VERSION "created by canmatrix"

NS_ :

BS_:

BU_: HUT T_BOX GW XBOX_D CEM Tester

BO_ 849 ABM1: 16 GW
 SG_ CheckSum_ABM1 : 7|8@0+ (1,0) [0|255] "" HUT
 SG_ SecRowLSBR : 14|1@0+ (1,0) [0|1] "" HUT
 SG_ AirbFailLmpCmd : 13|1@0+ (1,0) [0|1] "" HUT
 SG_ SecRowMidSBR : 12|1@0+ (1,0) [0|1] "" HUT
 SG_ DrvSBR : 11|1@0+ (1,0) [0|1] "" HUT
 SG_ SecRowRSBR : 10|1@0+ (1,0) [0|1] "" HUT
 SG_ PassSBR : 9|1@0+ (1,0) [0|1] "" HUT
 SG_ PassSBR_Visual : 27|2@0+ (1,0) [0|3] "" HUT
 SG_ DrvSBR_Visual : 25|2@0+ (1,0) [0|3] "" HUT
 SG_ SecRowLSBR_Visual : 29|2@0+ (1,0) [0|3] "" HUT
 SG_ SecRowMidSBR_Visual : 31|2@0+ (1,0) [0|3] "" HUT
 SG_ SecRowRSBR_Visual : 33|2@0+ (1,0) [0|3] "" HUT
 SG_ CrashOutputSts : 23|8@0+ (1,0) [0|18] "" HUT,T_BOX
 SG_ RollingCounter_ABM1 : 59|4@0+ (1,0) [0|15] "" HUT
 SG_ FreshnessValue_ABM1 : 71|16@0+ (1,0) [0|65535] "" HUT
 SG_ MAC_Check_ABM1 : 87|48@0+ (1,0) [0|281474976710655] "" HUT

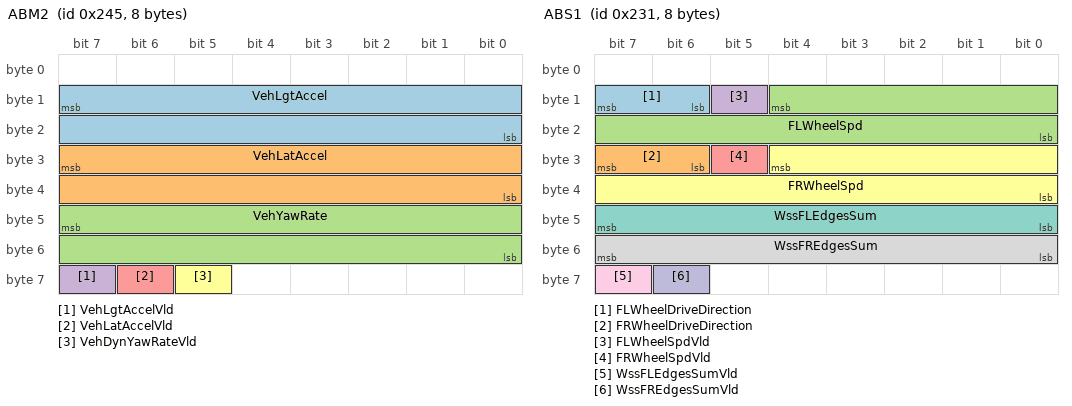
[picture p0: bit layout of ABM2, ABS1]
BO_ 581 ABM2: 8 GW
 SG_ VehLgtAccel : 15|16@0+ (0.00098,-21.592) [-21.592|21.592] "ms^2" HUT,T_BOX
 SG_ VehLatAccel : 31|16@0+ (0.00098,-21.592) [-21.592|21.592] "ms^2" HUT,T_BOX
 SG_ VehYawRate : 47|16@0+ (0.00024,-2.093) [-2.093|2.093] "rads" HUT,T_BOX
 SG_ VehLgtAccelVld : 63|1@0+ (1,0) [0|1] "" HUT,T_BOX
 SG_ VehLatAccelVld : 62|1@0+ (1,0) [0|1] "" HUT,T_BOX
 SG_ VehDynYawRateVld : 61|1@0+ (1,0) [0|1] "" HUT,T_BOX

BO_ 561 ABS1: 8 GW
 SG_ FLWheelDriveDirection : 15|2@0+ (1,0) [0|3] "" HUT
 SG_ FRWheelDriveDirection : 31|2@0+ (1,0) [0|3] "" HUT
 SG_ FLWheelSpd : 12|13@0+ (1,0) [0|299.98125] "kmh" HUT
 SG_ FLWheelSpdVld : 13|1@0+ (1,0) [0|1] "" HUT
 SG_ FRWheelSpdVld : 29|1@0+ (1,0) [0|1] "" HUT
 SG_ FRWheelSpd : 28|13@0+ (1,0) [0|299.98125] "kmh" HUT
 SG_ WssFLEdgesSum : 47|8@0+ (1,0) [0|255] "" HUT
 SG_ WssFREdgesSum : 55|8@0+ (1,0) [0|255] "" HUT
 SG_ WssFLEdgesSumVld : 63|1@0+ (1,0) [0|1] "" HUT
 SG_ WssFREdgesSumVld : 62|1@0+ (1,0) [0|1] "" HUT

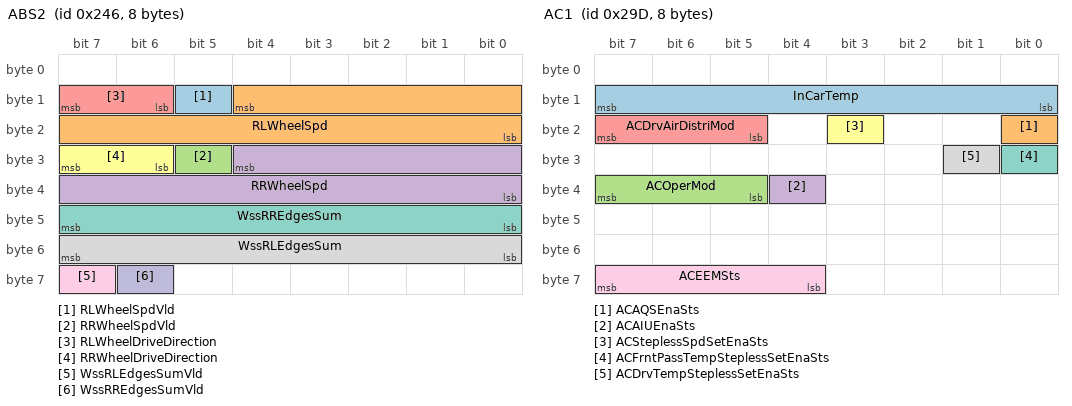
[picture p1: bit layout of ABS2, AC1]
BO_ 582 ABS2: 8 GW
 SG_ RLWheelSpdVld : 13|1@0+ (1,0) [0|1] "" HUT,T_BOX
 SG_ RLWheelSpd : 12|13@0+ (0.05625,0) [0|299.98125] "kmh" HUT,T_BOX
 SG_ RRWheelSpdVld : 29|1@0+ (1,0) [0|1] "" HUT,T_BOX
 SG_ RRWheelSpd : 28|13@0+ (0.05625,0) [0|299.98125] "kmh" HUT,T_BOX
 SG_ RLWheelDriveDirection : 15|2@0+ (1,0) [0|3] "" HUT
 SG_ RRWheelDriveDirection : 31|2@0+ (1,0) [0|3] "" HUT
 SG_ WssRREdgesSum : 47|8@0+ (1,0) [0|255] "" HUT
 SG_ WssRLEdgesSum : 55|8@0+ (1,0) [0|255] "" HUT
 SG_ WssRLEdgesSumVld : 63|1@0+ (1,0) [0|1] "" HUT
 SG_ WssRREdgesSumVld : 62|1@0+ (1,0) [0|1] "" HUT

BO_ 669 AC1: 8 GW
 SG_ InCarTemp : 15|8@0+ (0.5,-40) [-40|86.5] "Ã‚Â°C" HUT,T_BOX
 SG_ ACAQSEnaSts : 16|1@0+ (1,0) [0|1] "" HUT
 SG_ ACOperMod : 39|3@0+ (1,0) [0|7] "" HUT
 SG_ ACAIUEnaSts : 36|1@0+ (1,0) [0|1] "" HUT,T_BOX
 SG_ ACDrvAirDistriMod : 23|3@0+ (1,0) [0|7] "" HUT
 SG_ ACSteplessSpdSetEnaSts : 19|1@0+ (1,0) [0|1] "" HUT
 SG_ ACFrntPassTempSteplessSetEnaSts : 24|1@0+ (1,0) [0|1] "" HUT
 SG_ ACDrvTempSteplessSetEnaSts : 25|1@0+ (1,0) [0|1] "" HUT
 SG_ ACEEMSts : 63|4@0+ (1,0) [0|15] "" HUT

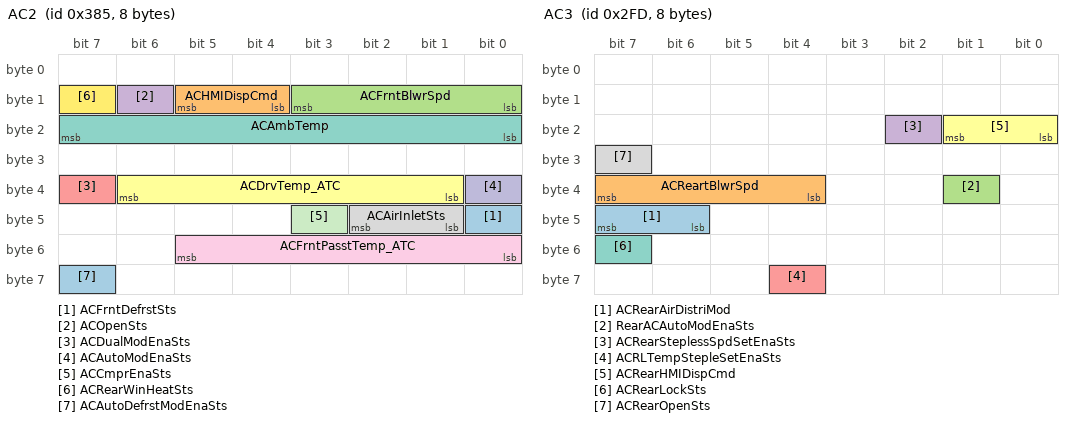
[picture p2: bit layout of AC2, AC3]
BO_ 901 AC2: 8 GW
 SG_ ACFrntDefrstSts : 40|1@0+ (1,0) [0|1] "" HUT,T_BOX
 SG_ ACHMIDispCmd : 13|2@0+ (1,0) [0|3] "" HUT,T_BOX
 SG_ ACFrntBlwrSpd : 11|4@0+ (1,0) [0|15] "" HUT,T_BOX
 SG_ ACOpenSts : 14|1@0+ (1,0) [0|1] "" HUT,T_BOX
 SG_ ACDualModEnaSts : 39|1@0+ (1,0) [0|1] "" HUT
 SG_ ACDrvTemp_ATC : 38|6@0+ (0.5,16) [16|32] "Ã‚Â°C" HUT,T_BOX
 SG_ ACAmbTemp : 23|8@0+ (0.5,-40) [-40|86.5] "Ã‚Â°C" HUT
 SG_ ACAirInletSts : 42|2@0+ (1,0) [0|3] "" HUT
 SG_ ACFrntPasstTemp_ATC : 53|6@0+ (0.5,16) [16|32] "Ã‚Â°C" HUT,T_BOX
 SG_ ACAutoModEnaSts : 32|1@0+ (1,0) [0|1] "" HUT,T_BOX
 SG_ ACCmprEnaSts : 43|1@0+ (1,0) [0|1] "" HUT
 SG_ ACRearWinHeatSts : 15|1@0+ (1,0) [0|1] "" HUT
 SG_ ACAutoDefrstModEnaSts : 63|1@0+ (1,0) [0|1] "" HUT

BO_ 765 AC3: 8 GW
 SG_ ACRearAirDistriMod : 47|2@0+ (1,0) [0|3] "" HUT
 SG_ ACReartBlwrSpd : 39|4@0+ (1,0) [0|15] "" HUT
 SG_ RearACAutoModEnaSts : 33|1@0+ (1,0) [0|1] "" HUT
 SG_ ACRearSteplessSpdSetEnaSts : 18|1@0+ (1,0) [0|1] "" HUT
 SG_ ACRLTempStepleSetEnaSts : 60|1@0+ (1,0) [0|1] "" HUT
 SG_ ACRearHMIDispCmd : 17|2@0+ (1,0) [0|3] "" HUT
 SG_ ACRearLockSts : 55|1@0+ (1,0) [0|1] "" HUT
 SG_ ACRearOpenSts : 31|1@0+ (1,0) [0|1] "" HUT

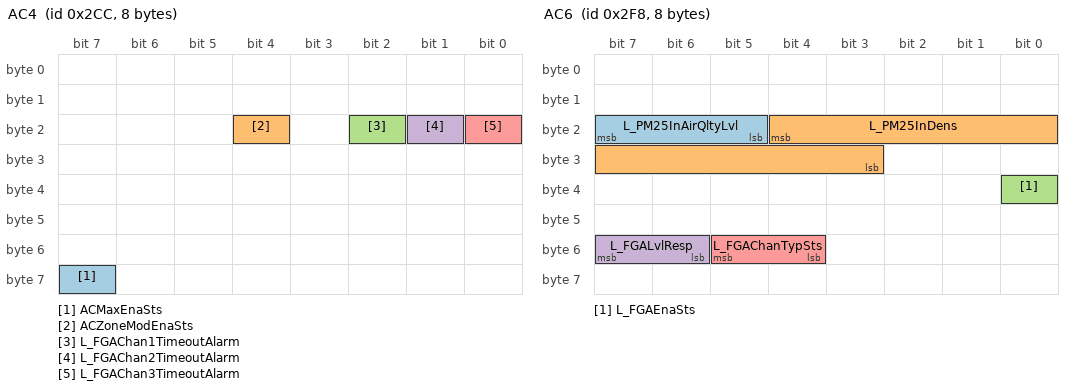
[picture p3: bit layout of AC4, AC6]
BO_ 716 AC4: 8 GW
 SG_ ACMaxEnaSts : 63|1@0+ (1,0) [0|1] "" HUT
 SG_ ACZoneModEnaSts : 20|1@0+ (1,0) [0|1] "" HUT
 SG_ L_FGAChan1TimeoutAlarm : 18|1@0+ (1,0) [0|1] "" HUT
 SG_ L_FGAChan2TimeoutAlarm : 17|1@0+ (1,0) [0|1] "" HUT
 SG_ L_FGAChan3TimeoutAlarm : 16|1@0+ (1,0) [0|1] "" HUT

BO_ 760 AC6: 8 GW
 SG_ L_PM25InAirQltyLvl : 23|3@0+ (1,0) [0|7] "" HUT
 SG_ L_PM25InDens : 20|10@0+ (1,0) [0|999] "ugm^3" HUT
 SG_ L_FGAEnaSts : 32|1@0+ (1,0) [0|1] "" HUT
 SG_ L_FGALvlResp : 55|2@0+ (1,0) [0|3] "" HUT
 SG_ L_FGAChanTypSts : 53|2@0+ (1,0) [0|3] "" HUT

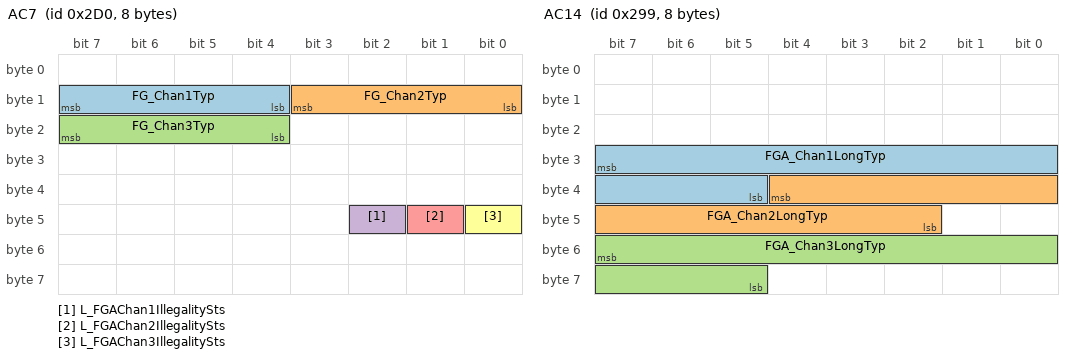
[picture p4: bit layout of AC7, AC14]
BO_ 720 AC7: 8 GW
 SG_ FG_Chan1Typ : 15|4@0+ (1,0) [0|15] "" HUT
 SG_ FG_Chan2Typ : 11|4@0+ (1,0) [0|15] "" HUT
 SG_ FG_Chan3Typ : 23|4@0+ (1,0) [0|15] "" HUT
 SG_ L_FGAChan1IllegalitySts : 42|1@0+ (1,0) [0|1] "" HUT
 SG_ L_FGAChan2IllegalitySts : 41|1@0+ (1,0) [0|1] "" HUT
 SG_ L_FGAChan3IllegalitySts : 40|1@0+ (1,0) [0|1] "" HUT

BO_ 636 AC8: 8 GW
 SG_ RearInCarTemp : 47|8@0+ (0.5,-40) [-40|86.5] "Ã‚Â°C" HUT,T_BOX
 SG_ ACRLTemp_ATC : 31|6@0+ (0.5,16) [16|32] "Ã‚Â°C" HUT,T_BOX

BO_ 665 AC14: 8 GW
 SG_ FGA_Chan1LongTyp : 31|11@0+ (1,0) [0|2047] "" HUT
 SG_ FGA_Chan2LongTyp : 36|11@0+ (1,0) [0|2047] "" HUT
 SG_ FGA_Chan3LongTyp : 55|11@0+ (1,0) [0|2047] "" HUT

BO_ 683 ACC_FD2: 64 IFC
 SG_ ACC_LeTgt_02_Dy : 15|7@0+ (0.1,-8) [-8|0] "m" HUT
 SG_ ACC_LeTgt_02_Dx : 8|9@0+ (0.5,0) [0|150] "m" HUT
 SG_ ACC_LeTgt_02_Typ : 31|3@0+ (1,0) [0|7] "" HUT
 SG_ ACC_LeTargrt_02_Detn : 28|2@0+ (1,0) [0|3] "" HUT
 SG_ ACC_RiTargrt_02_Detn : 26|2@0+ (1,0) [0|3] "" HUT
 SG_ ACC_RiTgt_02_Dy : 55|7@0+ (0.1,0) [0|8] "m" HUT
 SG_ ACC_RiTgt_02_Dx : 24|9@0+ (0.5,0) [0|150] "m" HUT
 SG_ ACC_RiTgt_02_Typ : 63|3@0+ (1,0) [0|7] "" HUT
 SG_ ACC_LeTgtObjBarDisp : 47|3@0+ (1,0) [0|7] "" HUT
 SG_ ACC_RiTgtObjBarDisp : 44|3@0+ (1,0) [0|7] "" HUT
 SG_ Checksum_ACC3 : 71|8@0+ (1,0) [0|255] "" HUT
 SG_ ICA_HandsOffResp : 78|1@0+ (1,0) [0|1] "" HUT
 SG_ ALC_Resp : 73|1@0+ (1,0) [0|1] "" HUT
 SG_ HWA_Resp : 77|1@0+ (1,0) [0|1] "" HUT
 SG_ ISL_Resp : 79|1@0+ (1,0) [0|1] "" HUT
 SG_ HWA_SnvtySet_Resp : 76|2@0+ (1,0) [0|3] "" HUT
 SG_ Longctrl_VehHldReq_DVR : 87|1@0+ (1,0) [0|1] "" HUT
 SG_ Longctrl_DrvOFF_Req_DVR : 86|1@0+ (1,0) [0|1] "" HUT
 SG_ Longctrl_ModSts_DVR : 85|4@0+ (1,0) [0|15] "" HUT
 SG_ Longctrl_Decel_Req_DVR : 81|1@0+ (1,0) [0|1] "" HUT
 SG_ Longctrl_EngTrqReq_DVR : 95|16@0+ (0.0030518,-100) [-100|99.999713] "%" HUT
 SG_ Longctrl_EngTrqReqActive_DVR : 80|1@0+ (1,0) [0|1] "" HUT
 SG_ Longctrl_DecelToStopReq_DVR : 119|1@0+ (1,0) [0|1] "" HUT
 SG_ Longctrl_ParkShiftReq_DVR : 118|2@0+ (1,0) [0|3] "" HUT
 SG_ Longctrl_Decel_ReqValue_DVR : 111|8@0+ (0.05,-7) [-7|5.75] "ms^2" HUT
 SG_ ALC_InterSysInfoDisp : 127|2@0+ (1,0) [0|3] "" HUT
 SG_ RollingCounter_ACC3 : 123|4@0+ (1,0) [0|15] "" HUT
 SG_ Checksum_ACC4 : 135|8@0+ (1,0) [0|255] "" HUT
 SG_ ACC_ObjDetecte : 143|1@0+ (1,0) [0|1] "" HUT
 SG_ ACC_TakeOverReq : 142|1@0+ (1,0) [0|1] "" HUT
 SG_ ACC_InterSysInfoDisp : 141|5@0+ (1,0) [0|31] "" HUT
 SG_ ACC_ModDisp : 151|5@0+ (1,0) [0|31] "" HUT
 SG_ ACC_FctSts : 146|2@0+ (1,0) [0|3] "" HUT
 SG_ ACC_TgtObjBarDisp : 159|3@0+ (1,0) [0|7] "" HUT
 SG_ Longctrl_HazActv : 156|2@0+ (1,0) [0|3] "" HUT
 SG_ TJA_ACC_SelSts : 154|3@0+ (1,0) [0|7] "" HUT
 SG_ CruCha_ModDisp : 167|4@0+ (1,0) [0|15] "" HUT
 SG_ TJA_ICA_InterSysInfoDisp : 163|3@0+ (1,0) [0|7] "" HUT
 SG_ TJA_ICA_ModDisp : 175|3@0+ (1,0) [0|7] "" HUT
 SG_ ISL_InterSysInfoDisp : 172|2@0+ (1,0) [0|3] "" HUT
 SG_ ACC_TimeGapSet : 170|3@0+ (1,0) [0|7] "" HUT
 SG_ ACC_SpdSetValue : 183|8@0+ (1,0) [0|255] "kphmph" HUT
 SG_ CruChar_InterSysInfoDisp : 191|4@0+ (1,0) [0|15] "" HUT
 SG_ RollingCounter_ACC4 : 187|4@0+ (1,0) [0|15] "" HUT
 SG_ Checksum_ACC8 : 199|8@0+ (1,0) [0|255] "" HUT
 SG_ HWA_ModDisp : 207|4@0+ (1,0) [0|15] "" HUT
 SG_ HWA_InterSysInfoDisp : 203|4@0+ (1,0) [0|15] "" HUT
 SG_ HWA_LaneChange : 213|2@0+ (1,0) [0|3] "" HUT
 SG_ HWA_LaneChangeReq : 223|3@0+ (1,0) [0|7] "" HUT
 SG_ HWA_Warning : 217|2@0+ (1,0) [0|3] "" HUT
 SG_ RollingCounter_ACC8 : 251|4@0+ (1,0) [0|15] "" HUT
 SG_ Checksum_ACC6 : 263|8@0+ (1,0) [0|255] "" HUT
 SG_ ACC_PotentialTgtDy : 271|8@0+ (0.1,-8) [-8|8] "m" HUT
 SG_ ACC_PotentialTgtDx : 279|9@0+ (0.5,0) [0|150] "m" HUT
 SG_ ACC_RlvTgtDetn : 286|2@0+ (1,0) [0|3] "" HUT
 SG_ ACC_EgoStatus : 284|2@0+ (1,0) [0|3] "" HUT
 SG_ ACC_RlvTgtTyp : 282|3@0+ (1,0) [0|7] "" HUT
 SG_ ACC_RlvTgtDy : 295|8@0+ (0.1,-8) [-8|8] "m" HUT
 SG_ ACC_RlvTgtDx : 303|9@0+ (0.5,0) [0|150] "m" HUT
 SG_ ACC_PotentialTgtDetn : 309|2@0+ (1,0) [0|3] "" HUT
 SG_ ACC_PotentialTgtTyp : 307|3@0+ (1,0) [0|7] "" HUT
 SG_ RollingCounter_ACC6 : 315|4@0+ (1,0) [0|15] "" HUT
 SG_ Checksum_ACC7 : 327|8@0+ (1,0) [0|255] "" HUT
 SG_ Request_driveoff : 383|3@0+ (1,0) [0|7] "" HUT
 SG_ ACCSts : 380|1@0+ (1,0) [0|1] "" HUT
 SG_ ACC_LeTgtDy : 335|8@0+ (0.1,-8) [-8|8] "m" HUT
 SG_ ACC_LeTgtDx : 343|9@0+ (0.5,0) [0|150] "m" HUT
 SG_ ACC_LeTgtTyp : 350|3@0+ (1,0) [0|7] "" HUT
 SG_ ACC_LeTargrtDection : 347|2@0+ (1,0) [0|3] "" HUT
 SG_ ACC_RiTargrtDetn : 345|2@0+ (1,0) [0|3] "" HUT
 SG_ ACC_RiTgtDy : 359|8@0+ (0.1,-8) [-8|8] "m" HUT
 SG_ ACC_RiTgtDx : 367|9@0+ (0.5,0) [0|150] "m" HUT
 SG_ ACC_RiTgtTyp : 374|3@0+ (1,0) [0|7] "" HUT
 SG_ RollingCounter_ACC7 : 379|4@0+ (1,0) [0|15] "" HUT
 SG_ FreshnessValue_ACC_FD2 : 455|16@0+ (1,0) [0|65535] "" HUT
 SG_ MAC_Check_ACC_FD2 : 471|48@0+ (1,0) [0|281474976710655] "" HUT
 SG_ ACC_RlvTgtfusion : 399|1@0+ (1,0) [0|1] "" HUT
 SG_ ACC_RlvTgtHeading : 398|6@0+ (0.05,-1.5) [-1.5|1.5] "rad" HUT
 SG_ ACC_LeTgtfusion : 392|1@0+ (1,0) [0|1] "" HUT
 SG_ ACC_LeTgtHeading : 407|6@0+ (0.05,-1.5) [-1.5|1.5] "rad" HUT
 SG_ ACC_RiTgtfusion : 401|1@0+ (1,0) [0|1] "" HUT
 SG_ ACC_RiTgtHeading : 415|6@0+ (0.05,-1.5) [-1.5|1.5] "rad" HUT
 SG_ ACC_PotentialTgtfusion : 400|1@0+ (1,0) [0|1] "" HUT
 SG_ ACC_PotentialTgtHeading : 409|6@0+ (0.05,-1.5) [-1.5|1.5] "rad" HUT
 SG_ TargetCutinPro : 419|6@0+ (0.02,0) [0|1] "" HUT
 SG_ TargetCutoutPro : 429|6@0+ (0.02,0) [0|1] "" HUT
 SG_ Longctrl_WheelTrqReqActive_DVR : 116|1@0+ (1,0) [0|1] "" HUT
 SG_ Longctrl_WheelTrqReq_DVR : 231|16@0+ (0.5,-16384) [-16384|16383.5] "NM" HUT

BO_ 692 ACC_FD3: 64 GW
 SG_ JAPedObjExist : 47|6@0+ (0.015625,0) [0|0.984375] "%" HUT
 SG_ AEBJAObjID : 79|8@0+ (1,0) [0|255] "" HUT
 SG_ AEBJAObjExist : 87|6@0+ (0.015625,0) [0|0.984375] "%" HUT
 SG_ JAPedObjID : 119|8@0+ (1,0) [0|255] "" HUT
 SG_ AEBJAObjVideoCfmd : 81|1@0+ (1,0) [0|1] "" HUT
 SG_ AEBJAObjVx : 95|12@0+ (0.0625,-128) [-128|127] "ms" HUT
 SG_ AEBJAObjDx : 99|12@0+ (0.0625,0) [0|255.9375] "m" HUT
 SG_ JAPedObjVideoCfmd : 80|1@0+ (1,0) [0|1] "" HUT
 SG_ AEBJAObjState : 127|3@0+ (1,0) [0|7] "" HUT
 SG_ AEBJAObjCntAlive : 143|12@0+ (17,0) [0|65535] "" HUT
 SG_ AEBJAObjDy : 147|11@0+ (0.125,-128) [-128|127.875] "m" HUT
 SG_ JAPedObjState : 191|3@0+ (1,0) [0|7] "" HUT
 SG_ AEBJAObjObstcl : 152|5@0+ (0.03125,0) [0|0.96875] "%" HUT
 SG_ AEBJAObjVy : 163|10@0+ (0.125,-64) [-64|63.875] "ms" HUT
 SG_ AEBJAObjAx : 169|10@0+ (0.03125,-16) [-16|15.96875] "ms2" HUT
 SG_ AEBJAObjAy : 207|10@0+ (0.03125,-16) [-16|15.96875] "ms2" HUT
 SG_ JAPedObjObstcl : 213|5@0+ (0.03125,0) [0|0.96875] "%" HUT
 SG_ JAPedObjDy : 223|11@0+ (0.125,-128) [-128|127.875] "m" HUT
 SG_ JAPedObjDx : 228|12@0+ (0.0625,0) [0|255.9375] "m" HUT
 SG_ FCWAEB_JATTC : 247|6@0+ (0.1,0) [0|6.3] "s" HUT
 SG_ JAPedObjVx : 271|12@0+ (0.0625,-128) [-128|127] "ms" HUT
 SG_ JAPedObjVy : 295|10@0+ (0.125,-64) [-64|63.875] "ms" HUT
 SG_ JAPedObjAy : 301|10@0+ (0.03125,-16) [-16|15.96875] "ms2" HUT
 SG_ JAPedObjCntAlive : 275|12@0+ (17,0) [0|65535] "" HUT
 SG_ FCWAEB_longTTC : 365|6@0+ (0.1,0) [0|6.3] "s" HUT
 SG_ FCWAEB_crossingTTC : 375|6@0+ (0.1,0) [0|6.3] "s" HUT
 SG_ JAPedObjAx : 335|10@0+ (0.03125,-16) [-16|15.96875] "ms2" HUT
 SG_ NOH_Sts : 355|4@0+ (1,0) [0|15] "" HUT
 SG_ NOH_Swt_Resp : 368|1@0+ (1,0) [0|1] "" HUT
 SG_ NOH_Act_Resp : 369|1@0+ (1,0) [0|1] "" HUT
 SG_ NOH_SysInfoDisplay : 383|4@0+ (1,0) [0|15] "" HUT
 SG_ NOH_DistToExit : 351|12@0+ (1,0) [0|4095] "m" HUT

BO_ 696 ACC_FD4: 64 GW
 SG_ AEBObjID : 7|8@0+ (1,0) [0|255] "" HUT
 SG_ AEBObjExist : 15|6@0+ (0.015625,0) [0|0.984375] "%" HUT
 SG_ AEBObjVideoCfmd : 9|1@0+ (1,0) [0|1] "" HUT
 SG_ AEBObjVx : 23|12@0+ (0.0625,-128) [-128|127] "ms" HUT
 SG_ AEBObjDx : 27|12@0+ (0.0625,0) [0|255.9375] "m" HUT
 SG_ AEBObjCntAlive : 47|12@0+ (1,0) [0|3855] "" HUT
 SG_ AEBObjDy : 50|11@0+ (0.125,-128) [-128|127.875] "m" HUT
 SG_ AEBObjState : 71|3@0+ (1,0) [0|7] "" HUT
 SG_ AEBObjObstcl : 68|5@0+ (0.03125,0) [0|0.96875] "%" HUT
 SG_ AEBObjVy : 79|10@0+ (0.125,-64) [-64|63.875] "ms" HUT
 SG_ CyclistObjExist : 85|6@0+ (0.015625,0) [0|0.984375] "%" HUT
 SG_ AEBObjAx : 95|10@0+ (0.03125,-16) [-16|15.96875] "ms2" HUT
 SG_ AEBObjAy : 101|10@0+ (0.03125,-16) [-16|15.96875] "ms2" HUT
 SG_ CyclistObjDx : 107|12@0+ (0.0625,0) [0|255.9375] "m" HUT
 SG_ CyclistObjID : 127|8@0+ (1,0) [0|255] "" HUT
 SG_ CyclistObjObstcl : 135|5@0+ (0.03125,0) [0|0.96875] "%" HUT
 SG_ CyclistObjDy : 130|11@0+ (0.125,-128) [-128|127.875] "m" HUT
 SG_ CyclistObjVx : 151|12@0+ (0.0625,-128) [-128|127] "ms" HUT
 SG_ CyclistObjCntAlive : 155|12@0+ (1,0) [0|3855] "" HUT
 SG_ CyclistObjVy : 175|10@0+ (0.125,-64) [-64|63.875] "ms" HUT
 SG_ CyclistObjState : 181|3@0+ (1,0) [0|7] "" HUT
 SG_ CyclistObjVideoCfmd : 178|1@0+ (1,0) [0|1] "" HUT
 SG_ CyclistObjAx : 177|10@0+ (0.03125,-16) [-16|15.96875] "ms2" HUT
 SG_ CyclistObjAy : 199|10@0+ (0.03125,-16) [-16|15.96875] "ms2" HUT
 SG_ PedObjExist : 205|6@0+ (0.015625,0) [0|0.984375] "%" HUT
 SG_ PedObjID : 215|8@0+ (1,0) [0|255] "" HUT
 SG_ PedObjObstcl : 223|5@0+ (0.03125,0) [0|0.96875] "%" HUT
 SG_ PedObjDy : 218|11@0+ (0.125,-128) [-128|127.875] "m" HUT
 SG_ PedObjDx : 239|12@0+ (0.0625,0) [0|255.9375] "m" HUT
 SG_ PedObjVx : 243|12@0+ (0.0625,-128) [-128|127] "ms" HUT
 SG_ PedObjVy : 263|10@0+ (0.125,-64) [-64|63.875] "ms" HUT
 SG_ PedObjVideoCfmd : 269|1@0+ (1,0) [0|1] "" HUT
 SG_ ACCTgtObjDx : 267|12@0+ (0.0625,0) [0|255.9375] "m" HUT
 SG_ PedObjAy : 287|10@0+ (0.03125,-16) [-16|15.96875] "ms2" HUT
 SG_ PedObjCntAlive : 293|12@0+ (1,0) [0|3855] "" HUT
 SG_ PedObjAx : 297|10@0+ (0.03125,-16) [-16|15.96875] "ms2" HUT
 SG_ ACCTgtObjID : 319|8@0+ (1,0) [0|255] "" HUT
 SG_ ACCTgtObjObstcl : 327|5@0+ (0.03125,0) [0|0.96875] "%" HUT
 SG_ ACCTgtObjDy : 322|11@0+ (0.125,-128) [-128|127.875] "m" HUT
 SG_ ACCTgtObjExist : 343|6@0+ (0.015625,0) [0|0.984375] "%" HUT
 SG_ ACCTgtObjVy : 337|10@0+ (0.125,-64) [-64|63.875] "ms" HUT
 SG_ ACCTgtObjVx : 359|12@0+ (0.0625,-128) [-128|127] "ms" HUT
 SG_ ACCTgtObjAx : 363|10@0+ (0.03125,-16) [-16|15.96875] "ms2" HUT
 SG_ ACCTgtObjAy : 369|10@0+ (0.03125,-16) [-16|15.96875] "ms2" HUT
 SG_ ACCTgtObjState : 391|3@0+ (1,0) [0|7] "" HUT
 SG_ ACCTgtObjVideoCfmd : 388|1@0+ (1,0) [0|1] "" HUT
 SG_ ACCTgtObjCntAlive : 387|12@0+ (1,0) [0|3855] "" HUT
 SG_ RadarHorMisalign : 407|12@0+ (0.0001,-0.2048) [-0.2048|0.2047] "rad" HUT
 SG_ HandsoffDetd : 411|2@0+ (1,0) [0|3] "" HUT
 SG_ DrvgOnHiWay : 409|2@0+ (1,0) [0|3] "" HUT
 SG_ RoadCrvt : 423|10@0+ (0.00032,-0.16352) [-0.16352|0.16352] "" HUT
 SG_ SpdLimitDst : 429|6@0+ (10,0) [0|600] "m" HUT
 SG_ RoadCrvtFar : 439|10@0+ (0.00032,-0.16352) [-0.16352|0.16352] "" HUT
 SG_ RampDst : 445|6@0+ (10,0) [0|600] "m" HUT
 SG_ SpdLimit : 455|8@0+ (1,0) [0|255] "" HUT
 SG_ CurveDst : 463|6@0+ (10,0) [0|600] "m" HUT
 SG_ NavSpdLimUnit : 457|2@0+ (1,0) [0|3] "" HUT
 SG_ TunnelDst : 471|6@0+ (10,0) [0|600] "m" HUT
 SG_ DrvgOnRiLane : 465|2@0+ (1,0) [0|3] "" HUT
 SG_ BrdgDst : 479|6@0+ (10,0) [0|600] "m" HUT
 SG_ RadarDrvrAttentive : 473|1@0+ (1,0) [0|1] "" HUT
 SG_ ACC_DataRecReq : 511|8@0+ (1,0) [0|255] "" HUT
 SG_ ACC_SOSReq : 484|2@0+ (1,0) [0|3] "" HUT,T_BOX
 SG_ PedObjState : 482|3@0+ (1,0) [0|7] "" HUT
 SG_ MapDataValid : 495|1@0+ (1,0) [0|1] "" HUT
 SG_ DrvrSts : 494|3@0+ (1,0) [0|7] "" HUT
 SG_ AEBObjOverlap : 491|5@0+ (1,0) [0|31] "" HUT
 SG_ AEBObjDrvby : 502|5@0+ (1,0) [0|31] "" HUT

BO_ 395 AEB_FD1: 64 GW
 SG_ AEB_ABA_Level : 79|2@0+ (1,0) [0|3] "" HUT
 SG_ AEB_ABA_Req : 77|1@0+ (1,0) [0|1] "" HUT
 SG_ EBA_TgtDecel_Req : 76|1@0+ (1,0) [0|1] "" HUT
 SG_ AEB_VehHldReq : 75|1@0+ (1,0) [0|1] "" HUT
 SG_ AEB_TgtDecel_Req : 74|1@0+ (1,0) [0|1] "" HUT
 SG_ AEB_TgtDecel_ReqValue : 87|16@0+ (0.000488,-16) [-16|16] "ms2" HUT
 SG_ AEB_AWB_Req : 73|1@0+ (1,0) [0|1] "" HUT
 SG_ AEB_AWB_Level : 103|4@0+ (1,0) [0|15] "" HUT
 SG_ AEB_ABP_Req : 72|1@0+ (1,0) [0|1] "" HUT
 SG_ AEB_BrkReqFunc : 99|3@0+ (1,0) [0|7] "" HUT
 SG_ AEB_ObjSty : 111|3@0+ (1,0) [0|7] "" HUT

BO_ 551 AEB_FD2: 64 IFC
 SG_ Checksum_AEB2 : 71|8@0+ (1,0) [0|255] "" HUT
 SG_ AEB_PedResp : 79|1@0+ (1,0) [0|1] "" HUT
 SG_ AEB_VehResp : 78|1@0+ (1,0) [0|1] "" HUT
 SG_ FCW_Snvty : 77|2@0+ (1,0) [0|3] "" HUT
 SG_ AEB_JA_Resp : 75|1@0+ (1,0) [0|1] "" HUT
 SG_ RollingCounter_AEB2 : 123|4@0+ (1,0) [0|15] "" HUT
 SG_ Checksum_AEB3 : 135|8@0+ (1,0) [0|255] "" HUT
 SG_ AEB_VehTrig : 143|1@0+ (1,0) [0|1] "" HUT
 SG_ AEB_PedTrig : 142|1@0+ (1,0) [0|1] "" HUT
 SG_ FCW_AEB_VehFctSts : 138|2@0+ (1,0) [0|3] "" HUT
 SG_ FCW_AEB_PedFctSts : 151|2@0+ (1,0) [0|3] "" HUT
 SG_ FCW_Warn : 149|2@0+ (1,0) [0|3] "" HUT
 SG_ AEB_JAFuncSts : 147|2@0+ (1,0) [0|3] "" HUT
 SG_ AEB_JA_Warn : 145|2@0+ (1,0) [0|3] "" HUT
 SG_ AEB_JABrkTrig : 159|2@0+ (1,0) [0|3] "" HUT
 SG_ RollingCounter_AEB3 : 187|4@0+ (1,0) [0|15] "" HUT
 SG_ ACC_PotentialTgt_02_Dy : 207|8@0+ (0.1,-8) [-8|8] "m" HUT
 SG_ ACC_PotentialTgt_02_Dx : 215|9@0+ (0.5,0) [0|150] "m" HUT
 SG_ ACC_PotentialTgt_02_Detn : 222|2@0+ (1,0) [0|3] "" HUT
 SG_ ACC_PotentialTgt_02_Typ : 220|3@0+ (1,0) [0|7] "" HUT
 SG_ ACC_PotentialTgt_02_fusion : 217|1@0+ (1,0) [0|1] "" HUT
 SG_ ACC_PotentialTgt_02_Heading : 239|6@0+ (0.05,-1.5) [-1.5|1.5] "rad" HUT
 SG_ ACC_LeTgt_03_Dy : 247|8@0+ (0.1,-8) [-8|8] "m" HUT
 SG_ ACC_LeTgt_03_Dx : 216|9@0+ (0.5,-50) [-50|150] "m" HUT
 SG_ ACC_LeTargrt_03_Detn : 233|2@0+ (1,0) [0|3] "" HUT
 SG_ ACC_LeTgt_03_Typ : 255|3@0+ (1,0) [0|7] "" HUT
 SG_ ACC_LeTgt_03_fusion : 252|1@0+ (1,0) [0|1] "" HUT
 SG_ ACC_LeTgt_03_Heading : 271|6@0+ (0.05,-1.5) [-1.5|1.5] "rad" HUT
 SG_ ACC_RiTgt_03_Dy : 279|8@0+ (0.1,-8) [-8|7] "m" HUT
 SG_ ACC_RiTgt_03_Dx : 287|9@0+ (0.5,-50) [-50|150] "m" HUT
 SG_ ACC_RiTargrt_03_Detn : 265|2@0+ (1,0) [0|3] "" HUT
 SG_ ACC_RiTgt_03_Typ : 294|3@0+ (1,0) [0|7] "" HUT
 SG_ ACC_RiTgt_03_fusion : 291|1@0+ (1,0) [0|1] "" HUT
 SG_ ACC_RiTgt_03_Heading : 303|6@0+ (0.05,-1.5) [-1.5|1.5] "rad" HUT
 SG_ FreshnessValue_AEB_FD2 : 455|16@0+ (1,0) [0|65535] "" HUT
 SG_ MAC_Check_AEB_FD2 : 471|48@0+ (1,0) [0|281474976710655] "" HUT

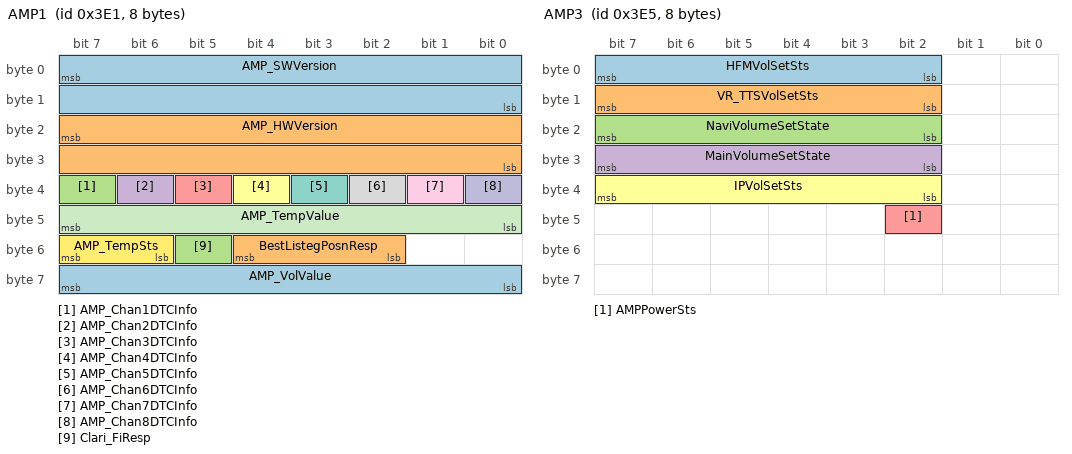
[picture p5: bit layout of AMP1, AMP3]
BO_ 993 AMP1: 8 GW
 SG_ AMP_SWVersion : 7|16@0+ (1,0) [0|65535] "" HUT
 SG_ AMP_HWVersion : 23|16@0+ (1,0) [0|65535] "" HUT
 SG_ AMP_Chan1DTCInfo : 39|1@0+ (1,0) [0|1] "" HUT
 SG_ AMP_Chan2DTCInfo : 38|1@0+ (1,0) [0|1] "" HUT
 SG_ AMP_Chan3DTCInfo : 37|1@0+ (1,0) [0|1] "" HUT
 SG_ AMP_Chan4DTCInfo : 36|1@0+ (1,0) [0|1] "" HUT
 SG_ AMP_Chan5DTCInfo : 35|1@0+ (1,0) [0|1] "" HUT
 SG_ AMP_Chan6DTCInfo : 34|1@0+ (1,0) [0|1] "" HUT
 SG_ AMP_Chan7DTCInfo : 33|1@0+ (1,0) [0|1] "" HUT
 SG_ AMP_Chan8DTCInfo : 32|1@0+ (1,0) [0|1] "" HUT
 SG_ AMP_TempValue : 47|8@0+ (1,-50) [-50|204] "" HUT
 SG_ AMP_TempSts : 55|2@0+ (1,0) [0|3] "" HUT
 SG_ AMP_VolValue : 63|8@0+ (0.1,0) [0|25.5] "" HUT
 SG_ BestListegPosnResp : 52|3@0+ (1,0) [0|7] "" HUT
 SG_ Clari_FiResp : 53|1@0+ (1,0) [0|1] "" HUT

BO_ 995 AMP2: 16 GW
 SG_ MediaCallSourceState : 7|4@0+ (1,0) [0|15] "" HUT
 SG_ BeepSourceSts : 2|3@0+ (1,0) [0|7] "" HUT
 SG_ BalanceSetState : 15|5@0+ (1,0) [0|20] "" HUT
 SG_ VSCModeState : 9|2@0+ (1,0) [0|3] "" HUT
 SG_ FadeSetState : 23|5@0+ (1,0) [0|20] "" HUT
 SG_ DriveSideSts : 17|1@0+ (1,0) [0|1] "" HUT
 SG_ BassSetState : 31|5@0+ (1,0) [0|20] "" HUT
 SG_ MuteState : 25|1@0+ (1,0) [0|1] "" HUT
 SG_ NaviSourceState : 39|3@0+ (1,0) [0|7] "" HUT
 SG_ MidrangeSetState : 47|5@0+ (1,0) [0|20] "" HUT
 SG_ T_box_ECallSts : 42|1@0+ (1,0) [0|1] "" HUT
 SG_ GetHUTInfoSts : 41|1@0+ (1,0) [0|1] "" HUT
 SG_ TrebleSetState : 55|5@0+ (1,0) [0|20] "" HUT
 SG_ QLISurroundSetSt : 49|1@0+ (1,0) [0|1] "" HUT
 SG_ AVMStResp : 3|1@0+ (1,0) [0|1] "" HUT
 SG_ NaviMediaVolLvlResp : 63|4@0+ (1,0) [0|15] "" HUT
 SG_ AVMMediaVolLvlResp : 59|4@0+ (1,0) [0|15] "" HUT
 SG_ FPASChStResp : 10|1@0+ (1,0) [0|1] "" HUT
 SG_ RPASChStResp : 18|1@0+ (1,0) [0|1] "" HUT
 SG_ FreshnessValue_AMP2 : 71|16@0+ (1,0) [0|65535] "" HUT
 SG_ MAC_Check_AMP2 : 87|48@0+ (1,0) [0|281474976710655] "" HUT

BO_ 997 AMP3: 8 GW
 SG_ HFMVolSetSts : 7|6@0+ (1,0) [0|39] "" HUT
 SG_ VR_TTSVolSetSts : 15|6@0+ (1,0) [0|39] "" HUT
 SG_ NaviVolumeSetState : 23|6@0+ (1,0) [0|39] "" HUT
 SG_ MainVolumeSetState : 31|6@0+ (1,0) [0|39] "" HUT
 SG_ AMPPowerSts : 42|1@0+ (1,0) [0|1] "" HUT
 SG_ IPVolSetSts : 39|6@0+ (1,0) [0|39] "" HUT

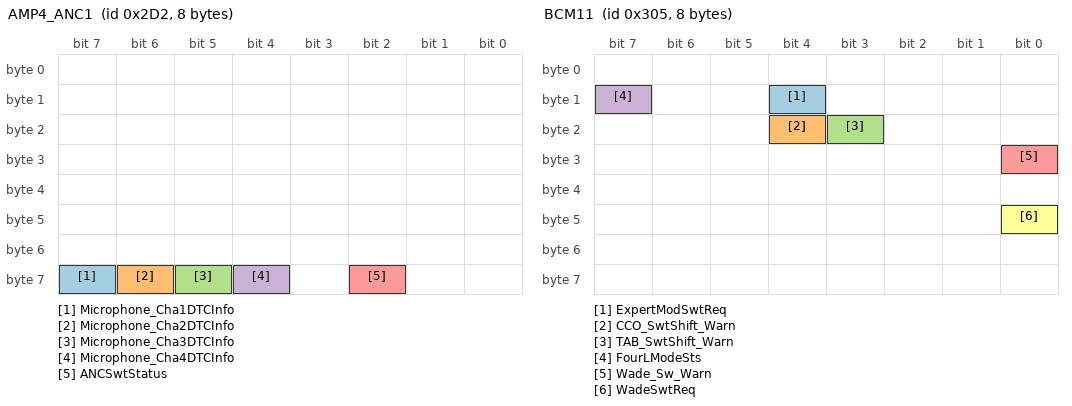
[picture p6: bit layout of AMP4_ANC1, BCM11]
BO_ 722 AMP4_ANC1: 8 GW
 SG_ Microphone_Cha1DTCInfo : 63|1@0+ (1,0) [0|1] "" HUT
 SG_ Microphone_Cha2DTCInfo : 62|1@0+ (1,0) [0|1] "" HUT
 SG_ Microphone_Cha3DTCInfo : 61|1@0+ (1,0) [0|1] "" HUT
 SG_ Microphone_Cha4DTCInfo : 60|1@0+ (1,0) [0|1] "" HUT
 SG_ ANCSwtStatus : 58|1@0+ (1,0) [0|1] "" HUT

BO_ 793 BCM1: 16 GW
 SG_ IPBackgroundLmpCmd : 18|1@0+ (1,0) [0|1] "" HUT
 SG_ TrunkSts : 23|1@0+ (1,0) [0|1] "" HUT,T_BOX
 SG_ DrvDoorSts : 22|1@0+ (1,0) [0|1] "" HUT,XBOX_D,T_BOX
 SG_ LRDoorSts : 21|1@0+ (1,0) [0|1] "" HUT,T_BOX
 SG_ PassengerDoorSts : 20|1@0+ (1,0) [0|1] "" HUT,XBOX_D,T_BOX
 SG_ RRDoorSts : 19|1@0+ (1,0) [0|1] "" HUT,T_BOX
 SG_ BrkPedalSts_BCM : 16|1@0+ (1,0) [0|1] "" HUT,T_BOX
 SG_ BackgroundLightLvl : 39|8@0+ (1,0) [0|255] "" HUT
 SG_ DrowsyDrvDetWarn : 44|2@0+ (1,0) [0|3] "" HUT
 SG_ RLSFailSts : 63|1@0+ (1,0) [0|1] "" HUT
 SG_ PosnLightReq : 61|1@0+ (1,0) [0|1] "" HUT
 SG_ WindshldWiprActvSts : 17|1@0+ (1,0) [0|1] "" HUT
 SG_ FreshnessValue_BCM1 : 71|16@0+ (1,0) [0|65535] "" HUT,T_BOX
 SG_ MAC_Check_BCM1 : 87|48@0+ (1,0) [0|281474976710655] "" HUT,T_BOX

BO_ 773 BCM11: 8 CEM
 SG_ ExpertModSwtReq : 12|1@0+ (1,0) [0|1] "" HUT
 SG_ CCO_SwtShift_Warn : 20|1@0+ (1,0) [0|1] "" HUT
 SG_ TAB_SwtShift_Warn : 19|1@0+ (1,0) [0|1] "" HUT
 SG_ FourLModeSts : 15|1@0+ (1,0) [0|1] "" HUT
 SG_ Wade_Sw_Warn : 24|1@0+ (1,0) [0|1] "" HUT
 SG_ WadeSwtReq : 40|1@0+ (1,0) [1|1] "" HUT

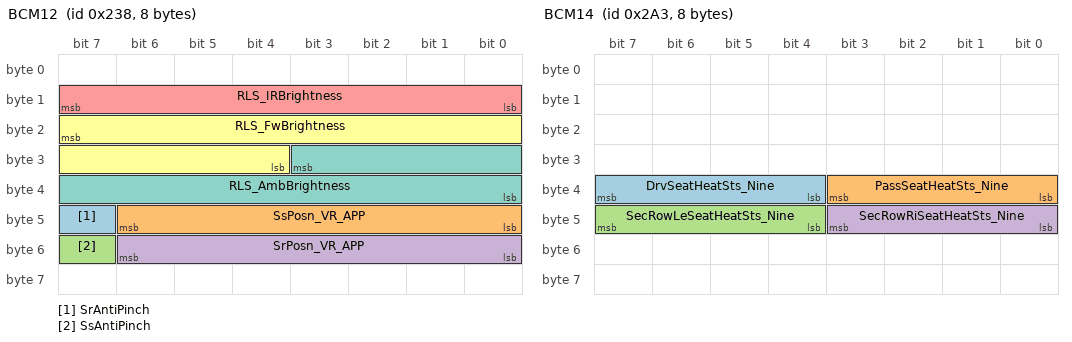
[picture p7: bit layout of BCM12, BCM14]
BO_ 568 BCM12: 8 CEM
 SG_ SrAntiPinch : 47|1@0+ (1,0) [0|1] "" HUT,T_BOX
 SG_ SsPosn_VR_APP : 46|7@0+ (1,0) [0|127] "" HUT,T_BOX
 SG_ SsAntiPinch : 55|1@0+ (1,0) [0|1] "" HUT,T_BOX
 SG_ SrPosn_VR_APP : 54|7@0+ (1,0) [0|127] "" HUT,T_BOX
 SG_ RLS_IRBrightness : 15|8@0+ (400,0) [0|101600] "" HUT
 SG_ RLS_FwBrightness : 23|12@0+ (6,0) [0|24564] "" HUT
 SG_ RLS_AmbBrightness : 27|12@0+ (20,0) [0|81880] "" HUT

BO_ 675 BCM14: 8 CEM
 SG_ DrvSeatHeatSts_Nine : 39|4@0+ (1,0) [0|15] "" HUT,T_BOX
 SG_ PassSeatHeatSts_Nine : 35|4@0+ (1,0) [0|15] "" HUT,T_BOX
 SG_ SecRowLeSeatHeatSts_Nine : 47|4@0+ (1,0) [0|15] "" HUT,T_BOX
 SG_ SecRowRiSeatHeatSts_Nine : 43|4@0+ (1,0) [0|15] "" HUT,T_BOX

BO_ 837 BCM3: 16 GW
 SG_ LasHdLmpSts : 35|1@0+ (1,0) [0|1] "" HUT
 SG_ AntitheftSts : 15|2@0+ (1,0) [0|3] "" HUT,T_BOX
 SG_ DrvDoorLockSts : 34|1@0+ (1,0) [0|1] "" HUT,T_BOX
 SG_ DoorLockSts : 13|2@0+ (1,0) [0|3] "" HUT,T_BOX
 SG_ HiLowBeamSts : 33|2@0+ (1,0) [0|2] "" HUT
 SG_ FreshnessValue_BCM3 : 71|16@0+ (1,0) [0|65535] "" HUT,T_BOX
 SG_ MAC_Check_BCM3 : 87|48@0+ (1,0) [0|281474976710655] "" HUT,T_BOX

CM_ SG_ 849 CheckSum_ABM1 "Use the checksum strategy from document Ã¢Â€ÂœEnd-to-End Communication Protection SpecificationÃ¢Â€Â";
CM_ SG_ 849 SecRowLSBR "Second row Left Seat Belt Reminder.";
CM_ SG_ 849 AirbFailLmpCmd "Indicates the Airbag system lamp commandIP Received";
CM_ SG_ 849 SecRowMidSBR "Second row Middle Seat Belt Reminder.";
CM_ SG_ 849 DrvSBR "Driver Seat Belt Reminder";
CM_ SG_ 849 SecRowRSBR "Second row Right Seat Belt Reminder.";
CM_ SG_ 849 PassSBR "Passenger Seat Belt Reminder";
CM_ SG_ 849 PassSBR_Visual "Passenger Seat Belt Reminder with Visual.IP Received";
CM_ SG_ 849 DrvSBR_Visual "Driver Seat Belt Reminder with Visual.IP Received";
CM_ SG_ 849 SecRowLSBR_Visual "Second row Left  Seat Belt Reminder with Visual.IP Received";
CM_ SG_ 849 SecRowMidSBR_Visual "Second row Middle Seat Belt Reminder with Visual.IP Received";
CM_ SG_ 849 SecRowRSBR_Visual "Second row Right  Seat Belt Reminder with Visual.IP Received";
CM_ SG_ 849 CrashOutputSts "Normal status message period is defined as 500ms.If any crash event is recognized and deploy decision sentÃ¯Â¼ÂŒ the message is sent immediatelyÃ¯Â¼ÂŒthe period is 10ms lasted for 20 times, this message is defined as crash status. After 20 times, recovery to normal status. If another deploy decision is sent during last crash status message output period, the new crash out message will not be sent, except the depoy decision out of the last crash out message course.
0x00   Startup  Default
0x03 0x11 0x12 acts asÃ¢Â€ÂœReservedÃ¢Â€Â.
Receiver: If the signal's value is reserved, the Receiver will use no crash.";
CM_ SG_ 849 RollingCounter_ABM1 "Rolling counter_ABM1";
CM_ SG_ 849 MAC_Check_ABM1 "MAC protection mechanism should comply with the GWM MAC Specificatio";
CM_ SG_ 581 VehLgtAccel "Vehicle Longitudinal acceleration";
CM_ SG_ 581 VehLatAccel "Vehicle Lateral Acceleration";
CM_ SG_ 581 VehYawRate "Vehicle yaw rate";
CM_ SG_ 581 VehLgtAccelVld "Vehicle Longitudinal acceleration valid";
CM_ SG_ 581 VehLatAccelVld "Vehicle Lateral Acceleratio valid";
CM_ SG_ 581 VehDynYawRateVld "Vehicle yaw rate valid";
CM_ SG_ 561 FLWheelDriveDirection "Front left wheel Moving direction";
CM_ SG_ 561 FRWheelDriveDirection "Front right wheel  Moving direction";
CM_ SG_ 561 FLWheelSpd "Front left wheel speed(when v <0.1 kph, set value to 0)";
CM_ SG_ 561 FLWheelSpdVld "Front left wheel speed valid";
CM_ SG_ 561 FRWheelSpdVld "Front right wheel speed valid";
CM_ SG_ 561 FRWheelSpd "Front right wheel speed(when v <0.1 kph, set value to 0)";
CM_ SG_ 561 WssFLEdgesSum "Sum of edge of Front Left Wheel speed sensor";
CM_ SG_ 561 WssFREdgesSum "Sum of edge of Front Right Wheel speed sensor";
CM_ SG_ 561 WssFLEdgesSumVld "Valid signal for Sum of edge of Front Left Wheel speed sensor";
CM_ SG_ 561 WssFREdgesSumVld "Valid signal for Sum of edge of Front Right Wheel speed sensor";
CM_ SG_ 582 RLWheelSpdVld "Rear left wheel speed valid";
CM_ SG_ 582 RLWheelSpd "Rear left wheel speed(when v <0.1 kph, set value to 0)";
CM_ SG_ 582 RRWheelSpdVld "Rear right wheel speed valid";
CM_ SG_ 582 RRWheelSpd "Rear right wheel speed(when v <0.1 kph, set value to 0)";
CM_ SG_ 582 RLWheelDriveDirection "Rear left wheel  Moving direction";
CM_ SG_ 582 RRWheelDriveDirection "Rear right wheel Moving direction";
CM_ SG_ 582 WssRREdgesSum "Sum of edge of rear Right Wheel speed sensor";
CM_ SG_ 582 WssRLEdgesSum "Sum of edge of rear Left Wheel speed sensor";
CM_ SG_ 582 WssRLEdgesSumVld "Valid signal for Sum of edge of rear Left Wheel speed sensor";
CM_ SG_ 582 WssRREdgesSumVld "Valid signal for Sum of edge of rear Right Wheel speed sensor";
CM_ SG_ 669 InCarTemp "Air Conditioning Cabin TemperatureÃ¯Â¼ÂˆDriver sideÃ¯Â¼Â‰";
CM_ SG_ 669 ACAQSEnaSts "AQS(air quality sensorÃ¯Â¼Â‰enable Status";
CM_ SG_ 669 ACOperMod "AC operation mode";
CM_ SG_ 669 ACAIUEnaSts "Air Ionizer Unit enable Status";
CM_ SG_ 669 ACDrvAirDistriMod "Driver Air Distribution Mode";
CM_ SG_ 669 ACSteplessSpdSetEnaSts "Blower Stepless Speed Set enable status";
CM_ SG_ 669 ACFrntPassTempSteplessSetEnaSts "Front passenger side Temperature Stepless Set enable status";
CM_ SG_ 669 ACDrvTempSteplessSetEnaSts "Drive side Temperature Stepless Set enable status";
CM_ SG_ 669 ACEEMSts "AC EEM status";
CM_ SG_ 901 ACFrntDefrstSts "Front Defrost status";
CM_ SG_ 901 ACHMIDispCmd "Display ACHMI on HUT command";
CM_ SG_ 901 ACFrntBlwrSpd "Front Blower Speed";
CM_ SG_ 901 ACOpenSts "AC open status";
CM_ SG_ 901 ACDualModEnaSts "AC dual mode enable status";
CM_ SG_ 901 ACDrvTemp_ATC "ATCÃ¯Â¼ÂˆAuto Touch ConditionÃ¯Â¼Â‰ Driver side Temperature";
CM_ SG_ 901 ACAmbTemp "Ambient display strategy:
1. In the Power mode = OFFÃ¯Â¼ÂŒ ACC, or Crank: Ambient Temperature = ini.
2. In the Power mode = Run:
Initial ambient temperature is depending on the EEPROM data and vehicle soak time(Soak time is <= 1min or =>60 min, it will show the raw data from ambient temperature sensor; 1min < Soak time < 60min, it will show the data from EEPROM, stored in last ignition cycle.);
The ambient temperature will be updated ACCording the raw data from sensor, vehicle speed, and timeIP Received";
CM_ SG_ 901 ACAirInletSts "AC airinlet status";
CM_ SG_ 901 ACFrntPasstTemp_ATC "Front Passenger Temperature";
CM_ SG_ 901 ACAutoModEnaSts "AC Auto mode enable status";
CM_ SG_ 901 ACCmprEnaSts "Compressor enable status";
CM_ SG_ 901 ACRearWinHeatSts "Rear Window Heating status";
CM_ SG_ 901 ACAutoDefrstModEnaSts "Auto defrost mode enable status";
CM_ SG_ 765 ACRearAirDistriMod "Rear AC Air Distribution Mode";
CM_ SG_ 765 ACReartBlwrSpd "Rear blower speed";
CM_ SG_ 765 RearACAutoModEnaSts "Rear AC Auto mode enable status";
CM_ SG_ 765 ACRearSteplessSpdSetEnaSts "Rear Blower Stepless Speed Set enable status";
CM_ SG_ 765 ACRLTempStepleSetEnaSts "Rear Left side Temperature Stepless Set enable status";
CM_ SG_ 765 ACRearHMIDispCmd "Display Rear ACHMI on HUT command";
CM_ SG_ 765 ACRearLockSts "Rear AC Control Lock Status";
CM_ SG_ 765 ACRearOpenSts "Rear AC open status";
CM_ SG_ 716 ACMaxEnaSts "AC Max Enable Status";
CM_ SG_ 716 ACZoneModEnaSts "AC Zone mode enable status";
CM_ SG_ 716 L_FGAChan1TimeoutAlarm "Fragrance channel 1 timeout alarm";
CM_ SG_ 716 L_FGAChan2TimeoutAlarm "Fragrance channel 2 timeout alarm";
CM_ SG_ 716 L_FGAChan3TimeoutAlarm "Fragrance channel 3 timeout alarm";
CM_ SG_ 760 L_PM25InAirQltyLvl "indoor air quality level";
CM_ SG_ 760 L_PM25InDens "indoor PM2.5  density";
CM_ SG_ 760 L_FGAEnaSts "Fragrance system enable status";
CM_ SG_ 760 L_FGALvlResp "Fragrance concentration response";
CM_ SG_ 760 L_FGAChanTypSts "Fragrance Type Channel Select status";
CM_ SG_ 720 FG_Chan1Typ "Fragrance channel 1 spice type";
CM_ SG_ 720 FG_Chan2Typ "Fragrance channel 2 spice type";
CM_ SG_ 720 FG_Chan3Typ "Fragrance channel 3 spice type";
CM_ SG_ 720 L_FGAChan1IllegalitySts "Fragrance channel 1 illegality status";
CM_ SG_ 720 L_FGAChan2IllegalitySts "Fragrance channel 2 illegality status";
CM_ SG_ 720 L_FGAChan3IllegalitySts "Fragrance channel 3 illegality status";
CM_ SG_ 636 RearInCarTemp "Rear Air Conditioning Cabin TemperatureÃ¯Â¼ÂˆDriver sideÃ¯Â¼Â‰";
CM_ SG_ 636 ACRLTemp_ATC "AC Rear Left Temperature";
CM_ SG_ 665 FGA_Chan1LongTyp "Fragrance channel 1 Long spice type";
CM_ SG_ 665 FGA_Chan2LongTyp "Fragrance channel 2 Long spice type";
CM_ SG_ 665 FGA_Chan3LongTyp "Fragrance channel 3 Long spice type";
CM_ SG_ 683 ACC_LeTgt_02_Dy "Lateral distance of the second target in left lane";
CM_ SG_ 683 ACC_LeTgt_02_Dx "Longitudinal distance of the second target in left lane";
CM_ SG_ 683 ACC_LeTgt_02_Typ "Type of the second target in left lane";
CM_ SG_ 683 ACC_LeTargrt_02_Detn "Detection of the second target in left lane";
CM_ SG_ 683 ACC_RiTargrt_02_Detn "Detection of the second target in rignt lane";
CM_ SG_ 683 ACC_RiTgt_02_Dy "Lateral distance of the second target in rignt lane";
CM_ SG_ 683 ACC_RiTgt_02_Dx "Longitudinal distance of the second target in right lane";
CM_ SG_ 683 ACC_RiTgt_02_Typ "Type of the second target in right lane";
CM_ SG_ 683 ACC_LeTgtObjBarDisp "Disply distance to the left target object in AR_HUD";
CM_ SG_ 683 ACC_RiTgtObjBarDisp "Disply distance to the right target object in AR_HUD";
CM_ SG_ 683 Checksum_ACC3 "Use the checksum strategy from document Ã¢Â€ÂœEnd-to-End Communication Protection SpecificationÃ¢Â€Â";
CM_ SG_ 683 ICA_HandsOffResp "Indicate ICA HandsOff Function switch status";
CM_ SG_ 683 ALC_Resp "Indicate Switch  of ALCÃ¯Â¼ÂˆAutomatic lane change assistanceÃ¯Â¼Â‰ switch statusIP Received";
CM_ SG_ 683 HWA_Resp "Indicate Switch  of HWA switch statusIP Received";
CM_ SG_ 683 ISL_Resp "Indicate ISL(Intelligent Speed Limit) switch status";
CM_ SG_ 683 HWA_SnvtySet_Resp "Indicate HWA Change track remind sensibility";
CM_ SG_ 683 Longctrl_VehHldReq_DVR "ACC request ESPÃ‚Â Ã‚Â hold vehicle";
CM_ SG_ 683 Longctrl_DrvOFF_Req_DVR "ACC request ESP(CDD-S) drive off";
CM_ SG_ 683 Longctrl_ModSts_DVR "The status of the Longctrl control unit.
The Longctrl mode should be contained in every message sent by Longctrl.";
CM_ SG_ 683 Longctrl_Decel_Req_DVR "Status of the deceleration request from ACC";
CM_ SG_ 683 Longctrl_EngTrqReq_DVR "Vehilce longitudinal control function Engine torque request";
CM_ SG_ 683 Longctrl_EngTrqReqActive_DVR "Vehilce longitudinal control function Engine torque request active";
CM_ SG_ 683 Longctrl_DecelToStopReq_DVR "The ACC request ESPVLC to decelerate untill standstill.";
CM_ SG_ 683 Longctrl_ParkShiftReq_DVR "ACC Request Park Shift";
CM_ SG_ 683 Longctrl_Decel_ReqValue_DVR "ACC deceleration request from ACC";
CM_ SG_ 683 ALC_InterSysInfoDisp "Automatic Lane Change";
CM_ SG_ 683 RollingCounter_ACC3 "RollingCounter_ACC3";
CM_ SG_ 683 Checksum_ACC4 "Use the checksum strategy from document Ã¢Â€ÂœEnd-to-End Communication Protection SpecificationÃ¢Â€Â";
CM_ SG_ 683 ACC_ObjDetecte "An ahead target object detected by ACC, to inform the driver.IP Received";
CM_ SG_ 683 ACC_TakeOverReq "The limits of the ACC control reaches, driver should take over.IP Received";
CM_ SG_ 683 ACC_InterSysInfoDisp "Provides driver for  text reminder informations of ACC functionIP Received";
CM_ SG_ 683 ACC_ModDisp "The status of the ACC control unit.IP Received";
CM_ SG_ 683 ACC_FctSts "Indicate ACC fuction system working statusIP Received";
CM_ SG_ 683 ACC_TgtObjBarDisp "Disply distance to the ahead target object in case of \"mid-end\" HMI.IP Received";
CM_ SG_ 683 Longctrl_HazActv "Indicate the hazard brake will be actived";
CM_ SG_ 683 TJA_ACC_SelSts "Indicate select status of TJAACC function swicthIP Received";
CM_ SG_ 683 CruCha_ModDisp "Cruise Chauffer StatusIP Received";
CM_ SG_ 683 TJA_ICA_InterSysInfoDisp "Provides driver for  text reminder informations of TJAICA functionIP Received";
CM_ SG_ 683 TJA_ICA_ModDisp "provides driver for  text reminder informations of TJAICA functionIP Received";
CM_ SG_ 683 ISL_InterSysInfoDisp "Provides driver for  text reminder informations of ISL(Intelligent Speed limit) functionIP Received";
CM_ SG_ 683 ACC_TimeGapSet "The set timeGap from driver, should be displayed to driver and if the set value changes.IP Received";
CM_ SG_ 683 ACC_SpdSetValue "The set speed from driver, should be available as long as ACC is active.IP Received";
CM_ SG_ 683 CruChar_InterSysInfoDisp "Provides driver for  text reminder informations of Cruise Chauffer functionIP Received";
CM_ SG_ 683 RollingCounter_ACC4 "RollingCounter_ACC4";
CM_ SG_ 683 Checksum_ACC8 "Use the checksum strategy from document Ã¢Â€ÂœEnd-to-End Communication Protection SpecificationÃ¢Â€Â";
CM_ SG_ 683 HWA_ModDisp "show the status of HWAIP Received";
CM_ SG_ 683 HWA_InterSysInfoDisp "Provides driver for  text reminder informations of HWA functionIP Received";
CM_ SG_ 683 HWA_LaneChange "Lane changingIP Received";
CM_ SG_ 683 HWA_LaneChangeReq "Lane change is availableIP Received";
CM_ SG_ 683 HWA_Warning "HWA  different level warningIP Received";
CM_ SG_ 683 RollingCounter_ACC8 "RollingCounter_ACC8";
CM_ SG_ 683 Checksum_ACC6 "Use the checksum strategy from document Ã¢Â€ÂœEnd-to-End Communication Protection SpecificationÃ¢Â€Â";
CM_ SG_ 683 ACC_PotentialTgtDy "Lateral distance of potential target in this laneIP Received";
CM_ SG_ 683 ACC_PotentialTgtDx "Longitudinal distance of potential target in this laneIP Received";
CM_ SG_ 683 ACC_RlvTgtDetn "Effective target detection.IP Received";
CM_ SG_ 683 ACC_EgoStatus "Status of ego vehicleIP Received";
CM_ SG_ 683 ACC_RlvTgtTyp "Types of effective targets in this laneIP Received";
CM_ SG_ 683 ACC_RlvTgtDy "Lateral distance of effective target in this laneIP Received";
CM_ SG_ 683 ACC_RlvTgtDx "Longitudinal distance of effective target in this laneIP Received";
CM_ SG_ 683 ACC_PotentialTgtDetn "Detection of potential targets in this laneIP Received";
CM_ SG_ 683 ACC_PotentialTgtTyp "Types of potential targets in this laneIP Received";
CM_ SG_ 683 RollingCounter_ACC6 "RollingCounter_ACC6";
CM_ SG_ 683 Checksum_ACC7 "Use the checksum strategy from document Ã¢Â€ÂœEnd-to-End Communication Protection SpecificationÃ¢Â€Â";
CM_ SG_ 683 Request_driveoff "Request driver drive off";
CM_ SG_ 683 ACCSts "show the status of ACC";
CM_ SG_ 683 ACC_LeTgtDy "Lateral distance of the nearest target in left laneIP Received";
CM_ SG_ 683 ACC_LeTgtDx "Longitudinal distance of the nearest target in left laneIP Received";
CM_ SG_ 683 ACC_LeTgtTyp "Type of the nearest target in left laneIP Received";
CM_ SG_ 683 ACC_LeTargrtDection "Detection of the nearest target in left laneIP Received";
CM_ SG_ 683 ACC_RiTargrtDetn "Detection of the nearest target in rignt laneIP Received";
CM_ SG_ 683 ACC_RiTgtDy "Lateral distance of the nearest target in rignt laneIP Received";
CM_ SG_ 683 ACC_RiTgtDx "Longitudinal distance of the nearest target in right laneIP Received";
CM_ SG_ 683 ACC_RiTgtTyp "Type of the nearest target in right laneIP Received";
CM_ SG_ 683 RollingCounter_ACC7 "RollingCounter_ACC7";
CM_ SG_ 683 MAC_Check_ACC_FD2 "MAC protection mechanism should comply with the GWM MAC Specificatio";
CM_ SG_ 683 ACC_RlvTgtfusion "fusion flag of  effective target in this lane";
CM_ SG_ 683 ACC_RlvTgtHeading "the heading angle of effective target in this lane";
CM_ SG_ 683 ACC_LeTgtfusion "fusion flag of the nearest target in left lane";
CM_ SG_ 683 ACC_LeTgtHeading "the heading angle of the nearest target in left lane";
CM_ SG_ 683 ACC_RiTgtfusion "fusion flag of the nearest target in right lane";
CM_ SG_ 683 ACC_RiTgtHeading "the heading angle of the nearest target in right lane";
CM_ SG_ 683 ACC_PotentialTgtfusion "fusion flag of potential target in this lane";
CM_ SG_ 683 ACC_PotentialTgtHeading "the heading angle of potential target in this lane";
CM_ SG_ 683 TargetCutinPro "Possibility of target cutting in";
CM_ SG_ 683 TargetCutoutPro "Possibility of target cutting out";
CM_ SG_ 683 Longctrl_WheelTrqReqActive_DVR "Vehilce longitudinal control function HCU torque request active";
CM_ SG_ 683 Longctrl_WheelTrqReq_DVR "Vehilce longitudinal control function HCU torque request at wheel level.";
CM_ SG_ 692 JAPedObjExist "The possibility of Pedestrian objecttive existence";
CM_ SG_ 692 AEBJAObjID "AEBJA objecttive ID";
CM_ SG_ 692 AEBJAObjExist "The possibility of AEBJA objecttive existence";
CM_ SG_ 692 JAPedObjID "Pedestrian objective ID";
CM_ SG_ 692 AEBJAObjVideoCfmd "AEBJA objective and Video Camera Fusion";
CM_ SG_ 692 AEBJAObjVx "Longitudinal relative speed of the AEBJA objecttive with the ego vehicle";
CM_ SG_ 692 AEBJAObjDx "Longitudinal distance of the AEBJA objecttive with the ego vehicle";
CM_ SG_ 692 JAPedObjVideoCfmd "Pedestrian objective and Video Camera Fusion";
CM_ SG_ 692 AEBJAObjState "Indicate AEBJA objective Status";
CM_ SG_ 692 AEBJAObjCntAlive "Indicate the duration of the AEBJA objecttive";
CM_ SG_ 692 AEBJAObjDy "Lateral distance of the AEBJA objecttive with the ego vehicle";
CM_ SG_ 692 JAPedObjState "Pedestrian objective Status";
CM_ SG_ 692 AEBJAObjObstcl "AEBJA Target are the possibility of obstacles";
CM_ SG_ 692 AEBJAObjVy "Lateral relative speed of the AEBJA target vehicle with the ego vehicle";
CM_ SG_ 692 AEBJAObjAx "Longitudinal relative speed of the AEBJA target with the ego vehicle";
CM_ SG_ 692 AEBJAObjAy "Lateral ACCeleration of the AEBJA target with the ego vehicle";
CM_ SG_ 692 JAPedObjObstcl "Target Pedestrian are the possibility of obstacles";
CM_ SG_ 692 JAPedObjDy "Lateral distance of the target Pedestrian with the ego vehicle";
CM_ SG_ 692 JAPedObjDx "Longitudinal distance of the target Pedestrian with the ego vehicle";
CM_ SG_ 692 FCWAEB_JATTC "FCWAEB JA turn across TTC";
CM_ SG_ 692 JAPedObjVx "Longitudinal relative speed of the target Pedestrian with the ego vehicle";
CM_ SG_ 692 JAPedObjVy "Lateral relative speed of the Pedestrian objective with the ego vehicle";
CM_ SG_ 692 JAPedObjAy "Lateral ACCeleration of Pedestrian objective with ego vehicle";
CM_ SG_ 692 JAPedObjCntAlive "Indicate the duration of the Pedestrian objective's existence";
CM_ SG_ 692 FCWAEB_longTTC "FCWAEB longitude TTC(Time to collision)";
CM_ SG_ 692 FCWAEB_crossingTTC "FCWAEB crossing TTC";
CM_ SG_ 692 JAPedObjAx "Longitudinal ACCeleration of Pedestrian objective with ego vehicle";
CM_ SG_ 692 NOH_Sts "show the status of NOH";
CM_ SG_ 692 NOH_Swt_Resp "Indicate Switch  of NOH switch status";
CM_ SG_ 692 NOH_Act_Resp "Indicate Switch  of NOH activate status";
CM_ SG_ 692 NOH_SysInfoDisplay "Provides driver for  text reminder informations of NOH function";
CM_ SG_ 692 NOH_DistToExit "Distance to NOH Geo-Fence exit";
CM_ SG_ 696 AEBObjID "AEB objecttive ID";
CM_ SG_ 696 AEBObjExist "The possibility of AEB objecttive existence";
CM_ SG_ 696 AEBObjVideoCfmd "AEB objective and Video Camera Fusion";
CM_ SG_ 696 AEBObjVx "Longitudinal relative speed of the AEB objecttive with the ego vehicle";
CM_ SG_ 696 AEBObjDx "Longitudinal distance of the AEB objecttive with the ego vehicle";
CM_ SG_ 696 AEBObjCntAlive "Indicate the duration of the AEB objecttive";
CM_ SG_ 696 AEBObjDy "Lateral distance of the AEB objecttive with the ego vehicle";
CM_ SG_ 696 AEBObjState "Indicate AEB objective Status";
CM_ SG_ 696 AEBObjObstcl "AEB Target are the possibility of obstacles";
CM_ SG_ 696 AEBObjVy "Lateral relative speed of the AEB target vehicle with the ego vehicle";
CM_ SG_ 696 CyclistObjExist "The possibility of Cyclist objecttive existence";
CM_ SG_ 696 AEBObjAx "Longitudinal relative speed of the AEB target with the ego vehicle";
CM_ SG_ 696 AEBObjAy "Lateral ACCeleration of the AEB target with the ego vehicle";
CM_ SG_ 696 CyclistObjDx "Longitudinal distance of the target Cyclist with the ego vehicle";
CM_ SG_ 696 CyclistObjID "Cyclist objecttive ID";
CM_ SG_ 696 CyclistObjObstcl "Target Cyclist are the possibility of obstacles";
CM_ SG_ 696 CyclistObjDy "Lateral distance of the Cyclist objective with the ego vehicle";
CM_ SG_ 696 CyclistObjVx "Longitudinal relative speed of the Cyclist objective with the ego vehicle";
CM_ SG_ 696 CyclistObjCntAlive "Indicate the duration of the target Cyclist's existence";
CM_ SG_ 696 CyclistObjVy "Lateral relative speed of the target Cyclist  with the ego vehicle";
CM_ SG_ 696 CyclistObjState "Cyclist objective Status";
CM_ SG_ 696 CyclistObjVideoCfmd "Cyclist objective and Video Camera Fusion";
CM_ SG_ 696 CyclistObjAx "Longitudinal ACCeleration of Cyclist objective with ego vehicle";
CM_ SG_ 696 CyclistObjAy "Lateral ACCeleration of Cyclist objective with ego vehicle";
CM_ SG_ 696 PedObjExist "The possibility of Pedestrian objecttive existence";
CM_ SG_ 696 PedObjID "Pedestrian objective ID";
CM_ SG_ 696 PedObjObstcl "Target Pedestrian are the possibility of obstacles";
CM_ SG_ 696 PedObjDy "Lateral distance of the target Pedestrian with the ego vehicle";
CM_ SG_ 696 PedObjDx "Longitudinal distance of the target Pedestrian with the ego vehicle";
CM_ SG_ 696 PedObjVx "Longitudinal relative speed of the target Pedestrian with the ego vehicle";
CM_ SG_ 696 PedObjVy "Lateral relative speed of the Pedestrian objective with the ego vehicle";
CM_ SG_ 696 PedObjVideoCfmd "Pedestrian objective and Video Camera Fusion";
CM_ SG_ 696 ACCTgtObjDx "Longitudinal distance of the ACCTarget objective with the ego vehicle";
CM_ SG_ 696 PedObjAy "Lateral ACCeleration of Pedestrian objective with ego vehicle";
CM_ SG_ 696 PedObjCntAlive "Indicate the duration of the Pedestrian objective's existence";
CM_ SG_ 696 PedObjAx "Longitudinal ACCeleration of Pedestrian objective with ego vehicle";
CM_ SG_ 696 ACCTgtObjID "ACCTarget objecttive ID";
CM_ SG_ 696 ACCTgtObjObstcl "ACCTarget objective are the possibility of obstacles";
CM_ SG_ 696 ACCTgtObjDy "Lateral distance of the ACCTarget objective with the ego vehicle";
CM_ SG_ 696 ACCTgtObjExist "The possibility of ACCTarget objecttive existence";
CM_ SG_ 696 ACCTgtObjVy "Lateral relative speed of the ACCTarget objective with the ego vehicle";
CM_ SG_ 696 ACCTgtObjVx "Longitudinal relative speed of the ACCTarget objective with the ego vehicle";
CM_ SG_ 696 ACCTgtObjAx "Longitudinal ACCeleration of ACCTarget objective with ego vehicle";
CM_ SG_ 696 ACCTgtObjAy "Lateral ACCeleration of ACCTarget objective with ego vehicle";
CM_ SG_ 696 ACCTgtObjState "ACCTarget objecttive Status";
CM_ SG_ 696 ACCTgtObjVideoCfmd "ACCTarget objective and Video Camera Fusion";
CM_ SG_ 696 ACCTgtObjCntAlive "Indicate the duration of the ACCTarget objective's existence";
CM_ SG_ 696 RadarHorMisalign "Horizontal Deviation Angle of Radar Installation for Radar Detection";
CM_ SG_ 696 HandsoffDetd "Hands off Detected";
CM_ SG_ 696 DrvgOnHiWay "Drive on Highway";
CM_ SG_ 696 RoadCrvt "Current position curvature";
CM_ SG_ 696 SpdLimitDst "Distance between Current location and speed limit point";
CM_ SG_ 696 RoadCrvtFar "200 m (tentative) road curvature ahead";
CM_ SG_ 696 RampDst "Current location and ramp distance";
CM_ SG_ 696 SpdLimit "Speed limit value";
CM_ SG_ 696 CurveDst "Distance between Current location and curve";
CM_ SG_ 696 NavSpdLimUnit "Speed limit unit";
CM_ SG_ 696 TunnelDst "Distance between Current location and tunnel";
CM_ SG_ 696 DrvgOnRiLane "Drive in the rightmost Lane";
CM_ SG_ 696 BrdgDst "Distance between Current location and bridge";
CM_ SG_ 696 RadarDrvrAttentive "Radar Detect driver's attention";
CM_ SG_ 696 ACC_DataRecReq "Rquest DVR Record Data";
CM_ SG_ 696 ACC_SOSReq "Indicate T-BOX will activative the e-call mode";
CM_ SG_ 696 PedObjState "Pedestrian objective Status";
CM_ SG_ 696 MapDataValid "Map Data is valid or invalid";
CM_ SG_ 696 DrvrSts "Driver State";
CM_ SG_ 696 AEBObjOverlap "Condition of AEB objecttive overlap";
CM_ SG_ 696 AEBObjDrvby "Condition of AEB objecttive driveby";
CM_ SG_ 395 AEB_ABA_Level "ABA level to the ESP HBA.";
CM_ SG_ 395 AEB_ABA_Req "Request of the ABA support from ESP.";
CM_ SG_ 395 EBA_TgtDecel_Req "Request of the EBA deceleration control.";
CM_ SG_ 395 AEB_VehHldReq "AEBÃ‚Â Ã‚Â request ESP hold vehicle";
CM_ SG_ 395 AEB_TgtDecel_Req "Request of the AEB deceleration control.";
CM_ SG_ 395 AEB_TgtDecel_ReqValue "Target deceleration value from AEBEBA";
CM_ SG_ 395 AEB_AWB_Req "Request of the brake jerk warning to ESP.";
CM_ SG_ 395 AEB_AWB_Level "Different level request of the brake jerk.";
CM_ SG_ 395 AEB_ABP_Req "Request of the Prefill to ESP.";
CM_ SG_ 395 AEB_BrkReqFunc "Display which Function request ESP Brake.";
CM_ SG_ 395 AEB_ObjSty "Indicate the style of AEB function trigger object";
CM_ SG_ 551 Checksum_AEB2 "Use the checksum strategy from document Ã¢Â€ÂœEnd-to-End Communication Protection SpecificationÃ¢Â€Â";
CM_ SG_ 551 AEB_PedResp "Indicate AEB-P(Pedestrian) switch status.";
CM_ SG_ 551 AEB_VehResp "Indicate AEB-V(Vehicle) switch status.IP Received";
CM_ SG_ 551 FCW_Snvty "Indicate FCW Sensitive";
CM_ SG_ 551 AEB_JA_Resp "Indicate AEB-JA(Junction Assist) switch status.IP Received";
CM_ SG_ 551 RollingCounter_AEB2 "RollingCounter_AEB2";
CM_ SG_ 551 Checksum_AEB3 "Use the checksum strategy from document Ã¢Â€ÂœEnd-to-End Communication Protection SpecificationÃ¢Â€Â";
CM_ SG_ 551 AEB_VehTrig "Indicate the AEB_Veh function had been triggeredIP Received";
CM_ SG_ 551 AEB_PedTrig "Indicate the AEB_Ped function had been triggeredIP Received";
CM_ SG_ 551 FCW_AEB_VehFctSts "Indicate FCWAEB-V fuction system working statusIP Received";
CM_ SG_ 551 FCW_AEB_PedFctSts "Indicate FCWAEB-P fuction system working statusIP Received";
CM_ SG_ 551 FCW_Warn "FCW latent(visual) warning or pre(acoustic)  warning. Used with ACC_FCW_ON_OFF signal.IP Received";
CM_ SG_ 551 AEB_JAFuncSts "Indicate AEB-JA fuction system working statusIP Received";
CM_ SG_ 551 AEB_JA_Warn "visual warning oracousticwarning.IP Received";
CM_ SG_ 551 AEB_JABrkTrig "Indicate the AEB_JA function had been triggeredIP Received";
CM_ SG_ 551 RollingCounter_AEB3 "RollingCounter_AEB3";
CM_ SG_ 551 ACC_PotentialTgt_02_Dy "Lateral distance of potential target 02 in this lane";
CM_ SG_ 551 ACC_PotentialTgt_02_Dx "Longitudinal distance of potential target02 in this lane";
CM_ SG_ 551 ACC_PotentialTgt_02_Detn "Detection of potential targets02 in this lane";
CM_ SG_ 551 ACC_PotentialTgt_02_Typ "Types of potential targets02 in this lane";
CM_ SG_ 551 ACC_PotentialTgt_02_fusion "fusion flag of potential target02 in this lane";
CM_ SG_ 551 ACC_PotentialTgt_02_Heading "the heading angle of potential target02 in this lane";
CM_ SG_ 551 ACC_LeTgt_03_Dy "Lateral distance of the 03 nearest target in left lane";
CM_ SG_ 551 ACC_LeTgt_03_Dx "Longitudinal distance  of the 03 nearest target in left lane";
CM_ SG_ 551 ACC_LeTargrt_03_Detn "Detection  of the03 nearest target in left lane";
CM_ SG_ 551 ACC_LeTgt_03_Typ "Types  of the03 nearest target in left lane";
CM_ SG_ 551 ACC_LeTgt_03_fusion "fusion flag  of the 03 nearest target in left lane";
CM_ SG_ 551 ACC_LeTgt_03_Heading "the heading angle  of the 03 nearest target in left lane";
CM_ SG_ 551 ACC_RiTgt_03_Dy "Lateral distance of the 03 nearest target in right lane";
CM_ SG_ 551 ACC_RiTgt_03_Dx "Longitudinal distance  of the 03 nearest target in right lane";
CM_ SG_ 551 ACC_RiTargrt_03_Detn "Detection  of the03 nearest target in right lane";
CM_ SG_ 551 ACC_RiTgt_03_Typ "Types  of the03 nearest target in right lane";
CM_ SG_ 551 ACC_RiTgt_03_fusion "fusion flag  of the 03 nearest target in right lane";
CM_ SG_ 551 ACC_RiTgt_03_Heading "the heading angle  of the 03 nearest target in right lane";
CM_ SG_ 551 MAC_Check_AEB_FD2 "MAC protection mechanism should comply with the GWM MAC Specificatio";
CM_ SG_ 993 AMP_SWVersion "Software version Information";
CM_ SG_ 993 AMP_HWVersion "Hardware version Information";
CM_ SG_ 993 AMP_Chan1DTCInfo "Amplifier output channel 1 DTC information";
CM_ SG_ 993 AMP_Chan2DTCInfo "Amplifier output channel 2 DTC information";
CM_ SG_ 993 AMP_Chan3DTCInfo "Amplifier output channel 3 DTC information";
CM_ SG_ 993 AMP_Chan4DTCInfo "Amplifier output channel 4 DTC information";
CM_ SG_ 993 AMP_Chan5DTCInfo "Amplifier output channel 5 DTC information";
CM_ SG_ 993 AMP_Chan6DTCInfo "Amplifier output channel 6 DTC information";
CM_ SG_ 993 AMP_Chan7DTCInfo "Amplifier output channel 7 DTC information";
CM_ SG_ 993 AMP_Chan8DTCInfo "Amplifier output channel 8 DTC information";
CM_ SG_ 993 AMP_TempValue "Amplifier internal temperature";
CM_ SG_ 993 AMP_TempSts "The value of AMP temperature status";
CM_ SG_ 993 AMP_VolValue "Amplifier internal voltage";
CM_ SG_ 993 BestListegPosnResp "Best listenting Position respond.";
CM_ SG_ 993 Clari_FiResp "Clari-Fi respond.";
CM_ SG_ 995 MediaCallSourceState "MediaCall Source State";
CM_ SG_ 995 BeepSourceSts "Beep source status.";
CM_ SG_ 995 BalanceSetState "Balance setting";
CM_ SG_ 995 VSCModeState "Vehicle Speed Compensation onoff";
CM_ SG_ 995 FadeSetState "Fade setting";
CM_ SG_ 995 DriveSideSts "Drive side state.";
CM_ SG_ 995 BassSetState "Low frequency audio setting";
CM_ SG_ 995 MuteState "MuteUnmute all speakers";
CM_ SG_ 995 NaviSourceState "Navi prompt onoff state imformation";
CM_ SG_ 995 MidrangeSetState "Mid frequency audio setting";
CM_ SG_ 995 T_box_ECallSts "T_box Ecall(emergency call) status (mute all speakers).";
CM_ SG_ 995 GetHUTInfoSts "Get HUT Information.";
CM_ SG_ 995 TrebleSetState "High frequency audio setting";
CM_ SG_ 995 QLISurroundSetSt "Stereo or surround state.";
CM_ SG_ 995 AVMStResp "AVM Status Response";
CM_ SG_ 995 NaviMediaVolLvlResp "Navigation Media Volume Level Response";
CM_ SG_ 995 AVMMediaVolLvlResp "AVM Media Volume Level Response";
CM_ SG_ 995 FPASChStResp "Front  Park Assistant System channel Status Response";
CM_ SG_ 995 RPASChStResp "Rear Park Assistant System channel Status Response";
CM_ SG_ 995 MAC_Check_AMP2 "MAC protection mechanism should comply with the GWM MAC Specificatio";
CM_ SG_ 997 HFMVolSetSts "HFM(hand free mode), RT(ring tone) and Tbox-IB call volume set status.";
CM_ SG_ 997 VR_TTSVolSetSts "VRTTS(text to sound) volume set state.";
CM_ SG_ 997 NaviVolumeSetState "Navi volume adjustment";
CM_ SG_ 997 MainVolumeSetState "Main volume step";
CM_ SG_ 997 AMPPowerSts "AMP feedback Power
Status to HUT";
CM_ SG_ 997 IPVolSetSts "IP Volume Set State";
CM_ SG_ 722 Microphone_Cha1DTCInfo "ANC Microphone  output channel 1 DTC information";
CM_ SG_ 722 Microphone_Cha2DTCInfo "ANC Microphone  output channel 2 DTC information";
CM_ SG_ 722 Microphone_Cha3DTCInfo "ANC Microphone  output channel 3 DTC information";
CM_ SG_ 722 Microphone_Cha4DTCInfo "ANC Microphone  output channel 4 DTC information";
CM_ SG_ 722 ANCSwtStatus "ANC switch onoff Status
ANCÃ¨Â®Â¾Ã§Â½Â®Ã¥Â¼Â€Ã¥Â…Â³(Ã¥Â·Â¥Ã§Â¨Â‹Ã¦Â¨Â¡Ã¥Â¼ÂÃ¤Â¸Â‹)Ã§ÂŠÂ¶Ã¦Â€ÂÃ¨Â¿Â”Ã¥Â›Âž";
CM_ SG_ 793 IPBackgroundLmpCmd "IP background lamp commandIP Received";
CM_ SG_ 793 TrunkSts "Trunk statusIP Received";
CM_ SG_ 793 DrvDoorSts "Driver door status.IP Received";
CM_ SG_ 793 LRDoorSts "Left rear door statusIP Received";
CM_ SG_ 793 PassengerDoorSts "Passenger door status.IP Received";
CM_ SG_ 793 RRDoorSts "Right   rear door statusIP Received";
CM_ SG_ 793 BrkPedalSts_BCM "Brake pedal statusIP Received";
CM_ SG_ 793 BackgroundLightLvl "Background light levelIP Received";
CM_ SG_ 793 DrowsyDrvDetWarn "Drowsy driver detect warningIP Received";
CM_ SG_ 793 RLSFailSts "Rain or light sensor failure statusIP Received";
CM_ SG_ 793 PosnLightReq "Position Light request.IP Received";
CM_ SG_ 793 WindshldWiprActvSts "Window shield Wiper active status";
CM_ SG_ 793 MAC_Check_BCM1 "MAC protection mechanism should comply with the GWM MAC Specificatio";
CM_ SG_ 773 ExpertModSwtReq "Expert Mode Switch Request";
CM_ SG_ 773 CCO_SwtShift_Warn "CCO Mode Shift Switch Warn";
CM_ SG_ 773 TAB_SwtShift_Warn "TAB Mode Shift Switch Warn";
CM_ SG_ 773 FourLModeSts "4L Mode Switch Request Status";
CM_ SG_ 773 Wade_Sw_Warn "Wade Switch Warn";
CM_ SG_ 773 WadeSwtReq "Wade Switch Request";
CM_ SG_ 568 SrAntiPinch "SR Curtain anti-pinch";
CM_ SG_ 568 SsPosn_VR_APP "Report sunshade position for HUT and T_Box";
CM_ SG_ 568 SsAntiPinch "SS Curtain anti-pinch";
CM_ SG_ 568 SrPosn_VR_APP "Report sunroof position for HUT and T_Box";
CM_ SG_ 568 RLS_IRBrightness "IR BrightnessSub_CAN:To HUD";
CM_ SG_ 568 RLS_FwBrightness "Fw BrightnessSub_CAN:To HUD";
CM_ SG_ 568 RLS_AmbBrightness "Amb BrightnessSub_CAN:To HUD";
CM_ SG_ 675 DrvSeatHeatSts_Nine "The driver side seat heating statusSC-CANFD:To HUT,T_Box";
CM_ SG_ 675 PassSeatHeatSts_Nine "The passenger side seat heating statusSC-CANFD:To HUT,T_Box";
CM_ SG_ 675 SecRowLeSeatHeatSts_Nine "Rear Left Passenger Seat Heating Status9 levelSC-CANFD:To HUT,T_Box";
CM_ SG_ 675 SecRowRiSeatHeatSts_Nine "Rear Right Passenger Seat Heating Status9 levelSC-CANFD:To HUT,T_Box";
CM_ SG_ 837 LasHdLmpSts "Laser Head Lamp Status";
CM_ SG_ 837 AntitheftSts "Vehicle antitheft status";
CM_ SG_ 837 DrvDoorLockSts "The status of the driver door lock  statusIP Received";
CM_ SG_ 837 DoorLockSts "Door lock status";
CM_ SG_ 837 HiLowBeamSts "High Low Beam StatusIP Received";
CM_ SG_ 837 MAC_Check_BCM3 "MAC protection mechanism should comply with the GWM MAC Specificatio";

BA_DEF_ BO_ "DiagRequest" ENUM  "No","Yes";
BA_DEF_ BO_ "DiagResponse" ENUM  "No","Yes";
BA_DEF_ BO_ "DiagState" ENUM  "No","Yes";
BA_DEF_ BO_ "GenMsgCycleTime" INT 0 65535;
BA_DEF_ BO_ "GenMsgCycleTimeFast" INT 0 65535;
BA_DEF_ BO_ "GenMsgILSupport" ENUM  "No","Yes";
BA_DEF_ BO_ "GenMsgNrOfRepetition" INT 0 65535;
BA_DEF_ BO_ "GenMsgSendType" ENUM  "Cyclic","CyclicAndSpontanX","Event";
BA_DEF_ BO_ "NmAsrMessage" ENUM  "No","Yes";
BA_DEF_ BO_ "OriginFrame" STRING;
BA_DEF_ BO_ "SCP_AuthInfoTxLength" INT 0 512;
BA_DEF_ BO_ "SCP_DataId" INT 0 65535;
BA_DEF_ BO_ "SCP_FreshnessValueLength" INT 0 512;
BA_DEF_ BO_ "SCP_FreshnessValueTxLength" INT 0 512;
BA_DEF_ BO_ "SC_Message" ENUM  "NO","YES";
BA_DEF_ BO_ "VFrameFormat" ENUM  "StandardCAN","ExtendedCAN","reserved","reserved","reserved","reserved","reserved","reserved","reserved","reserved","reserved","reserved","reserved","reserved","StandardCAN_FD","ExtendedCAN_FD";
BA_DEF_ SG_ "GenSigCycleTime" INT 0 65535;
BA_DEF_ SG_ "GenSigSendType" ENUM  "Cyclic","OnWrite","OnWriteWithRepetition","OnChange","OnChangeWithRepetition","NotUsed","NotUsed","NoSigSendType";
BA_DEF_ SG_ "GenSigStartValue" FLOAT 0 100000000000;
BA_DEF_ SG_ "Match" STRING;
BA_DEF_ SG_ "Origin" STRING;
BA_DEF_ SG_ "SystemSignalLongSymbol" STRING;
BA_DEF_ BU_ "NmAsrNode" ENUM  "No","Yes";
BA_DEF_  "BusType" STRING;
BA_DEF_  "DBName" STRING;
BA_DEF_  "NmAsrBaseAddress" HEX 1024 536870911;
BA_DEF_  "NmAsrCanMsgCycleTime" INT 1 65535;
BA_DEF_  "NmAsrMessageCount" INT 1 256;
BA_DEF_  "NmAsrRepeatMessageTime" INT 1 65535;
BA_DEF_  "NmAsrTimeoutTime" INT 1 65535;
BA_DEF_  "NmAsrWaitBusSleepTime" INT 1 65535;
BA_DEF_  "NmType" STRING;
BA_DEF_DEF_ "BusType" "";
BA_DEF_DEF_ "DBName" "B30_for_SC_CAN_V3_2";
BA_DEF_DEF_ "DiagRequest" "No";
BA_DEF_DEF_ "DiagResponse" "No";
BA_DEF_DEF_ "DiagState" "No";
BA_DEF_DEF_ "GenMsgCycleTime" 0;
BA_DEF_DEF_ "GenMsgCycleTimeFast" 0;
BA_DEF_DEF_ "GenMsgILSupport" "No";
BA_DEF_DEF_ "GenMsgNrOfRepetition" 0;
BA_DEF_DEF_ "GenMsgSendType" "Cyclic";
BA_DEF_DEF_ "GenSigCycleTime" 0;
BA_DEF_DEF_ "GenSigSendType" "Cyclic";
BA_DEF_DEF_ "GenSigStartValue" 0;
BA_DEF_DEF_ "Match" "";
BA_DEF_DEF_ "NmAsrBaseAddress" 1280;
BA_DEF_DEF_ "NmAsrCanMsgCycleTime" 500;
BA_DEF_DEF_ "NmAsrMessage" "No";
BA_DEF_DEF_ "NmAsrMessageCount" 100;
BA_DEF_DEF_ "NmAsrNode" "Yes";
BA_DEF_DEF_ "NmAsrRepeatMessageTime" 1500;
BA_DEF_DEF_ "NmAsrTimeoutTime" 2000;
BA_DEF_DEF_ "NmAsrWaitBusSleepTime" 5000;
BA_DEF_DEF_ "NmType" "NmAsr";
BA_DEF_DEF_ "Origin" "";
BA_DEF_DEF_ "OriginFrame" "";
BA_DEF_DEF_ "SCP_AuthInfoTxLength" 0;
BA_DEF_DEF_ "SCP_DataId" 0;
BA_DEF_DEF_ "SCP_FreshnessValueLength" 0;
BA_DEF_DEF_ "SCP_FreshnessValueTxLength" 0;
BA_DEF_DEF_ "SC_Message" "NO";
BA_DEF_DEF_ "SystemSignalLongSymbol" "";
BA_DEF_DEF_ "VFrameFormat" "";

BA_ "BusType"   "CAN FD";

BA_ "GenMsgCycleTime" BO_ 849 500;
BA_ "GenMsgCycleTimeFast" BO_ 849 20;
BA_ "GenMsgILSupport" BO_ 849 1;
BA_ "GenMsgNrOfRepetition" BO_ 849 5;
BA_ "OriginFrame" BO_ 849 "fuel,ev";
BA_ "SCP_AuthInfoTxLength" BO_ 849 48;
BA_ "SCP_DataId" BO_ 849 849;
BA_ "SCP_FreshnessValueLength" BO_ 849 64;
BA_ "SCP_FreshnessValueTxLength" BO_ 849 16;
BA_ "SC_Message" BO_ 849 1;
BA_ "VFrameFormat" BO_ 849 14;
BA_ "GenMsgCycleTime" BO_ 581 20;
BA_ "GenMsgILSupport" BO_ 581 1;
BA_ "OriginFrame" BO_ 581 "fuel,ev";
BA_ "VFrameFormat" BO_ 581 14;
BA_ "GenMsgCycleTime" BO_ 561 20;
BA_ "GenMsgILSupport" BO_ 561 1;
BA_ "OriginFrame" BO_ 561 "fuel,ev";
BA_ "VFrameFormat" BO_ 561 14;
BA_ "GenMsgCycleTime" BO_ 582 20;
BA_ "GenMsgILSupport" BO_ 582 1;
BA_ "OriginFrame" BO_ 582 "fuel,ev";
BA_ "VFrameFormat" BO_ 582 14;
BA_ "GenMsgCycleTime" BO_ 669 100;
BA_ "GenMsgILSupport" BO_ 669 1;
BA_ "OriginFrame" BO_ 669 "fuel,ev";
BA_ "VFrameFormat" BO_ 669 14;
BA_ "GenMsgCycleTime" BO_ 901 100;
BA_ "GenMsgILSupport" BO_ 901 1;
BA_ "OriginFrame" BO_ 901 "fuel,ev";
BA_ "VFrameFormat" BO_ 901 14;
BA_ "GenMsgCycleTime" BO_ 765 100;
BA_ "GenMsgILSupport" BO_ 765 1;
BA_ "OriginFrame" BO_ 765 "fuel,ev";
BA_ "VFrameFormat" BO_ 765 14;
BA_ "GenMsgCycleTime" BO_ 716 100;
BA_ "GenMsgILSupport" BO_ 716 1;
BA_ "OriginFrame" BO_ 716 "fuel,ev";
BA_ "VFrameFormat" BO_ 716 14;
BA_ "GenMsgCycleTime" BO_ 760 100;
BA_ "GenMsgILSupport" BO_ 760 1;
BA_ "OriginFrame" BO_ 760 "fuel,ev";
BA_ "VFrameFormat" BO_ 760 14;
BA_ "GenMsgCycleTime" BO_ 720 100;
BA_ "GenMsgILSupport" BO_ 720 1;
BA_ "OriginFrame" BO_ 720 "fuel,ev";
BA_ "VFrameFormat" BO_ 720 14;
BA_ "GenMsgCycleTime" BO_ 636 50;
BA_ "GenMsgILSupport" BO_ 636 1;
BA_ "OriginFrame" BO_ 636 "fuel,ev";
BA_ "VFrameFormat" BO_ 636 14;
BA_ "GenMsgCycleTime" BO_ 665 100;
BA_ "GenMsgILSupport" BO_ 665 1;
BA_ "OriginFrame" BO_ 665 "fuel,ev";
BA_ "VFrameFormat" BO_ 665 14;
BA_ "GenMsgCycleTime" BO_ 683 100;
BA_ "GenMsgILSupport" BO_ 683 1;
BA_ "OriginFrame" BO_ 683 "fuel,ev";
BA_ "SCP_AuthInfoTxLength" BO_ 683 48;
BA_ "SCP_DataId" BO_ 683 683;
BA_ "SCP_FreshnessValueLength" BO_ 683 64;
BA_ "SCP_FreshnessValueTxLength" BO_ 683 16;
BA_ "SC_Message" BO_ 683 1;
BA_ "VFrameFormat" BO_ 683 14;
BA_ "GenMsgCycleTime" BO_ 692 100;
BA_ "GenMsgILSupport" BO_ 692 1;
BA_ "OriginFrame" BO_ 692 "fuel,ev";
BA_ "VFrameFormat" BO_ 692 14;
BA_ "GenMsgCycleTime" BO_ 696 100;
BA_ "GenMsgILSupport" BO_ 696 1;
BA_ "OriginFrame" BO_ 696 "fuel,ev";
BA_ "VFrameFormat" BO_ 696 14;
BA_ "GenMsgCycleTime" BO_ 395 20;
BA_ "GenMsgILSupport" BO_ 395 1;
BA_ "OriginFrame" BO_ 395 "fuel,ev";
BA_ "VFrameFormat" BO_ 395 14;
BA_ "GenMsgCycleTime" BO_ 551 50;
BA_ "GenMsgILSupport" BO_ 551 1;
BA_ "OriginFrame" BO_ 551 "fuel,ev";
BA_ "SCP_AuthInfoTxLength" BO_ 551 48;
BA_ "SCP_DataId" BO_ 551 551;
BA_ "SCP_FreshnessValueLength" BO_ 551 64;
BA_ "SCP_FreshnessValueTxLength" BO_ 551 16;
BA_ "SC_Message" BO_ 551 1;
BA_ "VFrameFormat" BO_ 551 14;
BA_ "GenMsgCycleTimeFast" BO_ 993 20;
BA_ "GenMsgILSupport" BO_ 993 1;
BA_ "GenMsgNrOfRepetition" BO_ 993 5;
BA_ "GenMsgSendType" BO_ 993 2;
BA_ "OriginFrame" BO_ 993 "fuel,ev";
BA_ "VFrameFormat" BO_ 993 14;
BA_ "GenMsgCycleTimeFast" BO_ 995 20;
BA_ "GenMsgILSupport" BO_ 995 1;
BA_ "GenMsgNrOfRepetition" BO_ 995 5;
BA_ "GenMsgSendType" BO_ 995 2;
BA_ "OriginFrame" BO_ 995 "fuel,ev";
BA_ "SCP_AuthInfoTxLength" BO_ 995 48;
BA_ "SCP_DataId" BO_ 995 995;
BA_ "SCP_FreshnessValueLength" BO_ 995 64;
BA_ "SCP_FreshnessValueTxLength" BO_ 995 16;
BA_ "SC_Message" BO_ 995 1;
BA_ "VFrameFormat" BO_ 995 14;
BA_ "GenMsgCycleTimeFast" BO_ 997 20;
BA_ "GenMsgILSupport" BO_ 997 1;
BA_ "GenMsgNrOfRepetition" BO_ 997 5;
BA_ "GenMsgSendType" BO_ 997 2;
BA_ "OriginFrame" BO_ 997 "fuel,ev";
BA_ "VFrameFormat" BO_ 997 14;
BA_ "GenMsgCycleTimeFast" BO_ 722 20;
BA_ "GenMsgILSupport" BO_ 722 1;
BA_ "GenMsgNrOfRepetition" BO_ 722 5;
BA_ "GenMsgSendType" BO_ 722 2;
BA_ "OriginFrame" BO_ 722 "fuel,ev";
BA_ "VFrameFormat" BO_ 722 14;
BA_ "GenMsgCycleTime" BO_ 793 50;
BA_ "GenMsgILSupport" BO_ 793 1;
BA_ "OriginFrame" BO_ 793 "fuel,ev";
BA_ "SCP_AuthInfoTxLength" BO_ 793 48;
BA_ "SCP_DataId" BO_ 793 793;
BA_ "SCP_FreshnessValueLength" BO_ 793 64;
BA_ "SCP_FreshnessValueTxLength" BO_ 793 16;
BA_ "SC_Message" BO_ 793 1;
BA_ "VFrameFormat" BO_ 793 14;
BA_ "GenMsgCycleTime" BO_ 773 100;
BA_ "GenMsgILSupport" BO_ 773 1;
BA_ "OriginFrame" BO_ 773 "fuel,ev";
BA_ "VFrameFormat" BO_ 773 14;
BA_ "GenMsgCycleTime" BO_ 568 50;
BA_ "GenMsgILSupport" BO_ 568 1;
BA_ "OriginFrame" BO_ 568 "fuel,ev";
BA_ "VFrameFormat" BO_ 568 14;
BA_ "GenMsgCycleTime" BO_ 675 100;
BA_ "GenMsgILSupport" BO_ 675 1;
BA_ "OriginFrame" BO_ 675 "fuel,ev";
BA_ "VFrameFormat" BO_ 675 14;
BA_ "GenMsgCycleTime" BO_ 837 50;
BA_ "GenMsgILSupport" BO_ 837 1;
BA_ "OriginFrame" BO_ 837 "fuel,ev";
BA_ "SCP_AuthInfoTxLength" BO_ 837 48;
BA_ "SCP_DataId" BO_ 837 837;
BA_ "SCP_FreshnessValueLength" BO_ 837 64;
BA_ "SCP_FreshnessValueTxLength" BO_ 837 16;
BA_ "SC_Message" BO_ 837 1;
BA_ "VFrameFormat" BO_ 837 14;

BA_ "GenSigCycleTime" SG_ 849 CheckSum_ABM1 500;
BA_ "GenSigSendType" SG_ 849 CheckSum_ABM1 2;
BA_ "Match" SG_ 849 CheckSum_ABM1 "CheckSum_ABM1";
BA_ "Origin" SG_ 849 CheckSum_ABM1 "fuel,ev";
BA_ "GenSigCycleTime" SG_ 849 SecRowLSBR 500;
BA_ "GenSigSendType" SG_ 849 SecRowLSBR 2;
BA_ "GenSigStartValue" SG_ 849 SecRowLSBR 1;
BA_ "Match" SG_ 849 SecRowLSBR "SecRowLSBR";
BA_ "Origin" SG_ 849 SecRowLSBR "fuel,ev";
BA_ "GenSigCycleTime" SG_ 849 AirbFailLmpCmd 500;
BA_ "GenSigSendType" SG_ 849 AirbFailLmpCmd 2;
BA_ "GenSigStartValue" SG_ 849 AirbFailLmpCmd 1;
BA_ "Match" SG_ 849 AirbFailLmpCmd "AirbFailLmpCmd";
BA_ "Origin" SG_ 849 AirbFailLmpCmd "fuel,ev";
BA_ "GenSigCycleTime" SG_ 849 SecRowMidSBR 500;
BA_ "GenSigSendType" SG_ 849 SecRowMidSBR 2;
BA_ "GenSigStartValue" SG_ 849 SecRowMidSBR 1;
BA_ "Match" SG_ 849 SecRowMidSBR "SecRowMidSBR";
BA_ "Origin" SG_ 849 SecRowMidSBR "fuel,ev";
BA_ "GenSigCycleTime" SG_ 849 DrvSBR 500;
BA_ "GenSigSendType" SG_ 849 DrvSBR 2;
BA_ "GenSigStartValue" SG_ 849 DrvSBR 1;
BA_ "Match" SG_ 849 DrvSBR "DrvSBR";
BA_ "Origin" SG_ 849 DrvSBR "fuel,ev";
BA_ "GenSigCycleTime" SG_ 849 SecRowRSBR 500;
BA_ "GenSigSendType" SG_ 849 SecRowRSBR 2;
BA_ "GenSigStartValue" SG_ 849 SecRowRSBR 1;
BA_ "Match" SG_ 849 SecRowRSBR "SecRowRSBR";
BA_ "Origin" SG_ 849 SecRowRSBR "fuel,ev";
BA_ "GenSigCycleTime" SG_ 849 PassSBR 500;
BA_ "GenSigSendType" SG_ 849 PassSBR 2;
BA_ "GenSigStartValue" SG_ 849 PassSBR 1;
BA_ "Match" SG_ 849 PassSBR "PassSBR";
BA_ "Origin" SG_ 849 PassSBR "fuel,ev";
BA_ "GenSigCycleTime" SG_ 849 PassSBR_Visual 500;
BA_ "GenSigSendType" SG_ 849 PassSBR_Visual 2;
BA_ "GenSigStartValue" SG_ 849 PassSBR_Visual 1;
BA_ "Match" SG_ 849 PassSBR_Visual "PassSBR_Visual";
BA_ "Origin" SG_ 849 PassSBR_Visual "fuel,ev";
BA_ "GenSigCycleTime" SG_ 849 DrvSBR_Visual 500;
BA_ "GenSigSendType" SG_ 849 DrvSBR_Visual 2;
BA_ "GenSigStartValue" SG_ 849 DrvSBR_Visual 1;
BA_ "Match" SG_ 849 DrvSBR_Visual "DrvSBR_Visual";
BA_ "Origin" SG_ 849 DrvSBR_Visual "fuel,ev";
BA_ "GenSigCycleTime" SG_ 849 SecRowLSBR_Visual 500;
BA_ "GenSigSendType" SG_ 849 SecRowLSBR_Visual 2;
BA_ "GenSigStartValue" SG_ 849 SecRowLSBR_Visual 1;
BA_ "Match" SG_ 849 SecRowLSBR_Visual "SecRowLSBR_Visual";
BA_ "Origin" SG_ 849 SecRowLSBR_Visual "fuel,ev";
BA_ "GenSigCycleTime" SG_ 849 SecRowMidSBR_Visual 500;
BA_ "GenSigSendType" SG_ 849 SecRowMidSBR_Visual 2;
BA_ "GenSigStartValue" SG_ 849 SecRowMidSBR_Visual 1;
BA_ "Match" SG_ 849 SecRowMidSBR_Visual "SecRowMidSBR_Visual";
BA_ "Origin" SG_ 849 SecRowMidSBR_Visual "fuel,ev";
BA_ "GenSigCycleTime" SG_ 849 SecRowRSBR_Visual 500;
BA_ "GenSigSendType" SG_ 849 SecRowRSBR_Visual 2;
BA_ "GenSigStartValue" SG_ 849 SecRowRSBR_Visual 1;
BA_ "Match" SG_ 849 SecRowRSBR_Visual "SecRowRSBR_Visual";
BA_ "Origin" SG_ 849 SecRowRSBR_Visual "fuel,ev";
BA_ "GenSigCycleTime" SG_ 849 CrashOutputSts 500;
BA_ "GenSigSendType" SG_ 849 CrashOutputSts 2;
BA_ "Match" SG_ 849 CrashOutputSts "CrashOutputSts";
BA_ "Origin" SG_ 849 CrashOutputSts "fuel,ev";
BA_ "GenSigCycleTime" SG_ 849 RollingCounter_ABM1 500;
BA_ "GenSigSendType" SG_ 849 RollingCounter_ABM1 2;
BA_ "Match" SG_ 849 RollingCounter_ABM1 "RollingCounter_ABM1";
BA_ "Origin" SG_ 849 RollingCounter_ABM1 "fuel,ev";
BA_ "GenSigCycleTime" SG_ 849 FreshnessValue_ABM1 500;
BA_ "GenSigSendType" SG_ 849 FreshnessValue_ABM1 2;
BA_ "Match" SG_ 849 FreshnessValue_ABM1 "FreshnessValue_ABM1";
BA_ "Origin" SG_ 849 FreshnessValue_ABM1 "fuel,ev";
BA_ "GenSigCycleTime" SG_ 849 MAC_Check_ABM1 500;
BA_ "GenSigSendType" SG_ 849 MAC_Check_ABM1 2;
BA_ "Match" SG_ 849 MAC_Check_ABM1 "MAC_Check_ABM1";
BA_ "Origin" SG_ 849 MAC_Check_ABM1 "fuel,ev";
BA_ "GenSigCycleTime" SG_ 581 VehLgtAccel 20;
BA_ "GenSigStartValue" SG_ 581 VehLgtAccel 22033;
BA_ "Match" SG_ 581 VehLgtAccel "VehLgtAccel";
BA_ "Origin" SG_ 581 VehLgtAccel "fuel,ev";
BA_ "GenSigCycleTime" SG_ 581 VehLatAccel 20;
BA_ "GenSigStartValue" SG_ 581 VehLatAccel 22033;
BA_ "Match" SG_ 581 VehLatAccel "VehLatAccel";
BA_ "Origin" SG_ 581 VehLatAccel "fuel,ev";
BA_ "GenSigCycleTime" SG_ 581 VehYawRate 20;
BA_ "GenSigStartValue" SG_ 581 VehYawRate 8721;
BA_ "Match" SG_ 581 VehYawRate "VehYawRate";
BA_ "Origin" SG_ 581 VehYawRate "fuel,ev";
BA_ "GenSigCycleTime" SG_ 581 VehLgtAccelVld 20;
BA_ "Match" SG_ 581 VehLgtAccelVld "VehLgtAccelVld";
BA_ "Origin" SG_ 581 VehLgtAccelVld "fuel,ev";
BA_ "GenSigCycleTime" SG_ 581 VehLatAccelVld 20;
BA_ "Match" SG_ 581 VehLatAccelVld "VehLatAccelVld";
BA_ "Origin" SG_ 581 VehLatAccelVld "fuel,ev";
BA_ "GenSigCycleTime" SG_ 581 VehDynYawRateVld 20;
BA_ "Match" SG_ 581 VehDynYawRateVld "VehDynYawRateVld";
BA_ "Origin" SG_ 581 VehDynYawRateVld "fuel,ev";
BA_ "GenSigCycleTime" SG_ 561 FLWheelDriveDirection 20;
BA_ "Match" SG_ 561 FLWheelDriveDirection "FLWheelDriveDirection";
BA_ "Origin" SG_ 561 FLWheelDriveDirection "fuel,ev";
BA_ "GenSigCycleTime" SG_ 561 FRWheelDriveDirection 20;
BA_ "Match" SG_ 561 FRWheelDriveDirection "FRWheelDriveDirection";
BA_ "Origin" SG_ 561 FRWheelDriveDirection "fuel,ev";
BA_ "GenSigCycleTime" SG_ 561 FLWheelSpd 20;
BA_ "Match" SG_ 561 FLWheelSpd "FLWheelSpd";
BA_ "Origin" SG_ 561 FLWheelSpd "fuel,ev";
BA_ "GenSigCycleTime" SG_ 561 FLWheelSpdVld 20;
BA_ "Match" SG_ 561 FLWheelSpdVld "FLWheelSpdVld";
BA_ "Origin" SG_ 561 FLWheelSpdVld "fuel,ev";
BA_ "GenSigCycleTime" SG_ 561 FRWheelSpdVld 20;
BA_ "Match" SG_ 561 FRWheelSpdVld "FRWheelSpdVld";
BA_ "Origin" SG_ 561 FRWheelSpdVld "fuel,ev";
BA_ "GenSigCycleTime" SG_ 561 FRWheelSpd 20;
BA_ "Match" SG_ 561 FRWheelSpd "FRWheelSpd";
BA_ "Origin" SG_ 561 FRWheelSpd "fuel,ev";
BA_ "GenSigCycleTime" SG_ 561 WssFLEdgesSum 20;
BA_ "Match" SG_ 561 WssFLEdgesSum "WssFLEdgesSum";
BA_ "Origin" SG_ 561 WssFLEdgesSum "fuel,ev";
BA_ "GenSigCycleTime" SG_ 561 WssFREdgesSum 20;
BA_ "Match" SG_ 561 WssFREdgesSum "WssFREdgesSum";
BA_ "Origin" SG_ 561 WssFREdgesSum "fuel,ev";
BA_ "GenSigCycleTime" SG_ 561 WssFLEdgesSumVld 20;
BA_ "Match" SG_ 561 WssFLEdgesSumVld "WssFLEdgesSumVld";
BA_ "Origin" SG_ 561 WssFLEdgesSumVld "fuel,ev";
BA_ "GenSigCycleTime" SG_ 561 WssFREdgesSumVld 20;
BA_ "Match" SG_ 561 WssFREdgesSumVld "WssFREdgesSumVld";
BA_ "Origin" SG_ 561 WssFREdgesSumVld "fuel,ev";
BA_ "GenSigCycleTime" SG_ 582 RLWheelSpdVld 20;
BA_ "Match" SG_ 582 RLWheelSpdVld "RLWheelSpdVld";
BA_ "Origin" SG_ 582 RLWheelSpdVld "fuel,ev";
BA_ "GenSigCycleTime" SG_ 582 RLWheelSpd 20;
BA_ "Match" SG_ 582 RLWheelSpd "RLWheelSpd";
BA_ "Origin" SG_ 582 RLWheelSpd "fuel,ev";
BA_ "GenSigCycleTime" SG_ 582 RRWheelSpdVld 20;
BA_ "Match" SG_ 582 RRWheelSpdVld "RRWheelSpdVld";
BA_ "Origin" SG_ 582 RRWheelSpdVld "fuel,ev";
BA_ "GenSigCycleTime" SG_ 582 RRWheelSpd 20;
BA_ "Match" SG_ 582 RRWheelSpd "RRWheelSpd";
BA_ "Origin" SG_ 582 RRWheelSpd "fuel,ev";
BA_ "GenSigCycleTime" SG_ 582 RLWheelDriveDirection 20;
BA_ "Match" SG_ 582 RLWheelDriveDirection "RLWheelDriveDirection";
BA_ "Origin" SG_ 582 RLWheelDriveDirection "fuel,ev";
BA_ "GenSigCycleTime" SG_ 582 RRWheelDriveDirection 20;
BA_ "Match" SG_ 582 RRWheelDriveDirection "RRWheelDriveDirection";
BA_ "Origin" SG_ 582 RRWheelDriveDirection "fuel,ev";
BA_ "GenSigCycleTime" SG_ 582 WssRREdgesSum 20;
BA_ "Match" SG_ 582 WssRREdgesSum "WssRREdgesSum";
BA_ "Origin" SG_ 582 WssRREdgesSum "fuel,ev";
BA_ "GenSigCycleTime" SG_ 582 WssRLEdgesSum 20;
BA_ "Match" SG_ 582 WssRLEdgesSum "WssRLEdgesSum";
BA_ "Origin" SG_ 582 WssRLEdgesSum "fuel,ev";
BA_ "GenSigCycleTime" SG_ 582 WssRLEdgesSumVld 20;
BA_ "Match" SG_ 582 WssRLEdgesSumVld "WssRLEdgesSumVld";
BA_ "Origin" SG_ 582 WssRLEdgesSumVld "fuel,ev";
BA_ "GenSigCycleTime" SG_ 582 WssRREdgesSumVld 20;
BA_ "Match" SG_ 582 WssRREdgesSumVld "WssRREdgesSumVld";
BA_ "Origin" SG_ 582 WssRREdgesSumVld "fuel,ev";
BA_ "GenSigCycleTime" SG_ 669 InCarTemp 100;
BA_ "GenSigStartValue" SG_ 669 InCarTemp 254;
BA_ "Match" SG_ 669 InCarTemp "InCarTemp";
BA_ "Origin" SG_ 669 InCarTemp "fuel,ev";
BA_ "GenSigCycleTime" SG_ 669 ACAQSEnaSts 100;
BA_ "Match" SG_ 669 ACAQSEnaSts "ACAQSEnaSts";
BA_ "Origin" SG_ 669 ACAQSEnaSts "fuel,ev";
BA_ "GenSigCycleTime" SG_ 669 ACOperMod 100;
BA_ "Match" SG_ 669 ACOperMod "ACOperMod";
BA_ "Origin" SG_ 669 ACOperMod "fuel,ev";
BA_ "GenSigCycleTime" SG_ 669 ACAIUEnaSts 100;
BA_ "Match" SG_ 669 ACAIUEnaSts "ACAIUEnaSts";
BA_ "Origin" SG_ 669 ACAIUEnaSts "fuel,ev";
BA_ "GenSigCycleTime" SG_ 669 ACDrvAirDistriMod 100;
BA_ "GenSigStartValue" SG_ 669 ACDrvAirDistriMod 7;
BA_ "Match" SG_ 669 ACDrvAirDistriMod "ACDrvAirDistriMod";
BA_ "Origin" SG_ 669 ACDrvAirDistriMod "fuel,ev";
BA_ "GenSigCycleTime" SG_ 669 ACSteplessSpdSetEnaSts 100;
BA_ "Match" SG_ 669 ACSteplessSpdSetEnaSts "ACSteplessSpdSetEnaSts";
BA_ "Origin" SG_ 669 ACSteplessSpdSetEnaSts "fuel,ev";
BA_ "GenSigCycleTime" SG_ 669 ACFrntPassTempSteplessSetEnaSts 100;
BA_ "Match" SG_ 669 ACFrntPassTempSteplessSetEnaSts "ACFrntPassTempSteplessSetEnaSts";
BA_ "Origin" SG_ 669 ACFrntPassTempSteplessSetEnaSts "fuel,ev";
BA_ "GenSigCycleTime" SG_ 669 ACDrvTempSteplessSetEnaSts 100;
BA_ "Match" SG_ 669 ACDrvTempSteplessSetEnaSts "ACDrvTempSteplessSetEnaSts";
BA_ "Origin" SG_ 669 ACDrvTempSteplessSetEnaSts "fuel,ev";
BA_ "GenSigCycleTime" SG_ 669 ACEEMSts 100;
BA_ "Match" SG_ 669 ACEEMSts "ACEEMSts";
BA_ "Origin" SG_ 669 ACEEMSts "fuel,ev";
BA_ "GenSigCycleTime" SG_ 901 ACFrntDefrstSts 100;
BA_ "Match" SG_ 901 ACFrntDefrstSts "ACFrntDefrstSts";
BA_ "Origin" SG_ 901 ACFrntDefrstSts "fuel,ev";
BA_ "GenSigCycleTime" SG_ 901 ACHMIDispCmd 100;
BA_ "Match" SG_ 901 ACHMIDispCmd "ACHMIDispCmd";
BA_ "Origin" SG_ 901 ACHMIDispCmd "fuel,ev";
BA_ "GenSigCycleTime" SG_ 901 ACFrntBlwrSpd 100;
BA_ "GenSigStartValue" SG_ 901 ACFrntBlwrSpd 15;
BA_ "Match" SG_ 901 ACFrntBlwrSpd "ACFrntBlwrSpd";
BA_ "Origin" SG_ 901 ACFrntBlwrSpd "fuel,ev";
BA_ "GenSigCycleTime" SG_ 901 ACOpenSts 100;
BA_ "Match" SG_ 901 ACOpenSts "ACOpenSts";
BA_ "Origin" SG_ 901 ACOpenSts "fuel,ev";
BA_ "GenSigCycleTime" SG_ 901 ACDualModEnaSts 100;
BA_ "Match" SG_ 901 ACDualModEnaSts "ACDualModEnaSts";
BA_ "Origin" SG_ 901 ACDualModEnaSts "fuel,ev";
BA_ "GenSigCycleTime" SG_ 901 ACDrvTemp_ATC 100;
BA_ "GenSigStartValue" SG_ 901 ACDrvTemp_ATC 33;
BA_ "Match" SG_ 901 ACDrvTemp_ATC "ACDrvTemp_ATC";
BA_ "Origin" SG_ 901 ACDrvTemp_ATC "fuel,ev";
BA_ "GenSigCycleTime" SG_ 901 ACAmbTemp 100;
BA_ "GenSigStartValue" SG_ 901 ACAmbTemp 254;
BA_ "Match" SG_ 901 ACAmbTemp "ACAmbTemp";
BA_ "Origin" SG_ 901 ACAmbTemp "fuel,ev";
BA_ "GenSigCycleTime" SG_ 901 ACAirInletSts 100;
BA_ "GenSigStartValue" SG_ 901 ACAirInletSts 3;
BA_ "Match" SG_ 901 ACAirInletSts "ACAirInletSts";
BA_ "Origin" SG_ 901 ACAirInletSts "fuel,ev";
BA_ "GenSigCycleTime" SG_ 901 ACFrntPasstTemp_ATC 100;
BA_ "GenSigStartValue" SG_ 901 ACFrntPasstTemp_ATC 33;
BA_ "Match" SG_ 901 ACFrntPasstTemp_ATC "ACFrntPasstTemp_ATC";
BA_ "Origin" SG_ 901 ACFrntPasstTemp_ATC "fuel,ev";
BA_ "GenSigCycleTime" SG_ 901 ACAutoModEnaSts 100;
BA_ "Match" SG_ 901 ACAutoModEnaSts "ACAutoModEnaSts";
BA_ "Origin" SG_ 901 ACAutoModEnaSts "fuel,ev";
BA_ "GenSigCycleTime" SG_ 901 ACCmprEnaSts 100;
BA_ "Match" SG_ 901 ACCmprEnaSts "ACCmprEnaSts";
BA_ "Origin" SG_ 901 ACCmprEnaSts "fuel,ev";
BA_ "GenSigCycleTime" SG_ 901 ACRearWinHeatSts 100;
BA_ "Match" SG_ 901 ACRearWinHeatSts "ACRearWinHeatSts";
BA_ "Origin" SG_ 901 ACRearWinHeatSts "fuel,ev";
BA_ "GenSigCycleTime" SG_ 901 ACAutoDefrstModEnaSts 100;
BA_ "Match" SG_ 901 ACAutoDefrstModEnaSts "ACAutoDefrstModEnaSts";
BA_ "Origin" SG_ 901 ACAutoDefrstModEnaSts "fuel,ev";
BA_ "GenSigCycleTime" SG_ 765 ACRearAirDistriMod 100;
BA_ "GenSigStartValue" SG_ 765 ACRearAirDistriMod 3;
BA_ "Match" SG_ 765 ACRearAirDistriMod "ACRearAirDistriMod";
BA_ "Origin" SG_ 765 ACRearAirDistriMod "fuel,ev";
BA_ "GenSigCycleTime" SG_ 765 ACReartBlwrSpd 100;
BA_ "GenSigStartValue" SG_ 765 ACReartBlwrSpd 15;
BA_ "Match" SG_ 765 ACReartBlwrSpd "ACReartBlwrSpd";
BA_ "Origin" SG_ 765 ACReartBlwrSpd "fuel,ev";
BA_ "GenSigCycleTime" SG_ 765 RearACAutoModEnaSts 100;
BA_ "Match" SG_ 765 RearACAutoModEnaSts "RearACAutoModEnaSts";
BA_ "Origin" SG_ 765 RearACAutoModEnaSts "fuel,ev";
BA_ "GenSigCycleTime" SG_ 765 ACRearSteplessSpdSetEnaSts 100;
BA_ "Match" SG_ 765 ACRearSteplessSpdSetEnaSts "ACRearSteplessSpdSetEnaSts";
BA_ "Origin" SG_ 765 ACRearSteplessSpdSetEnaSts "fuel,ev";
BA_ "GenSigCycleTime" SG_ 765 ACRLTempStepleSetEnaSts 100;
BA_ "Match" SG_ 765 ACRLTempStepleSetEnaSts "ACRLTempStepleSetEnaSts";
BA_ "Origin" SG_ 765 ACRLTempStepleSetEnaSts "fuel,ev";
BA_ "GenSigCycleTime" SG_ 765 ACRearHMIDispCmd 100;
BA_ "Match" SG_ 765 ACRearHMIDispCmd "ACRearHMIDispCmd";
BA_ "Origin" SG_ 765 ACRearHMIDispCmd "fuel,ev";
BA_ "GenSigCycleTime" SG_ 765 ACRearLockSts 100;
BA_ "Match" SG_ 765 ACRearLockSts "ACRearLockSts";
BA_ "Origin" SG_ 765 ACRearLockSts "fuel,ev";
BA_ "GenSigCycleTime" SG_ 765 ACRearOpenSts 100;
BA_ "Match" SG_ 765 ACRearOpenSts "ACRearOpenSts";
BA_ "Origin" SG_ 765 ACRearOpenSts "fuel,ev";
BA_ "GenSigCycleTime" SG_ 716 ACMaxEnaSts 100;
BA_ "Match" SG_ 716 ACMaxEnaSts "ACMaxEnaSts";
BA_ "Origin" SG_ 716 ACMaxEnaSts "fuel,ev";
BA_ "GenSigCycleTime" SG_ 716 ACZoneModEnaSts 100;
BA_ "Match" SG_ 716 ACZoneModEnaSts "ACZoneModEnaSts";
BA_ "Origin" SG_ 716 ACZoneModEnaSts "fuel,ev";
BA_ "GenSigCycleTime" SG_ 716 L_FGAChan1TimeoutAlarm 100;
BA_ "Match" SG_ 716 L_FGAChan1TimeoutAlarm "L_FGAChan1TimeoutAlarm";
BA_ "Origin" SG_ 716 L_FGAChan1TimeoutAlarm "fuel,ev";
BA_ "GenSigCycleTime" SG_ 716 L_FGAChan2TimeoutAlarm 100;
BA_ "Match" SG_ 716 L_FGAChan2TimeoutAlarm "L_FGAChan2TimeoutAlarm";
BA_ "Origin" SG_ 716 L_FGAChan2TimeoutAlarm "fuel,ev";
BA_ "GenSigCycleTime" SG_ 716 L_FGAChan3TimeoutAlarm 100;
BA_ "Match" SG_ 716 L_FGAChan3TimeoutAlarm "L_FGAChan3TimeoutAlarm";
BA_ "Origin" SG_ 716 L_FGAChan3TimeoutAlarm "fuel,ev";
BA_ "GenSigCycleTime" SG_ 760 L_PM25InAirQltyLvl 100;
BA_ "Match" SG_ 760 L_PM25InAirQltyLvl "L_PM25InAirQltyLvl";
BA_ "Origin" SG_ 760 L_PM25InAirQltyLvl "fuel,ev";
BA_ "GenSigCycleTime" SG_ 760 L_PM25InDens 100;
BA_ "Match" SG_ 760 L_PM25InDens "L_PM25InDens";
BA_ "Origin" SG_ 760 L_PM25InDens "fuel,ev";
BA_ "GenSigCycleTime" SG_ 760 L_FGAEnaSts 100;
BA_ "Match" SG_ 760 L_FGAEnaSts "L_FGAEnaSts";
BA_ "Origin" SG_ 760 L_FGAEnaSts "fuel,ev";
BA_ "GenSigCycleTime" SG_ 760 L_FGALvlResp 100;
BA_ "Match" SG_ 760 L_FGALvlResp "L_FGALvlResp";
BA_ "Origin" SG_ 760 L_FGALvlResp "fuel,ev";
BA_ "GenSigCycleTime" SG_ 760 L_FGAChanTypSts 100;
BA_ "Match" SG_ 760 L_FGAChanTypSts "L_FGAChanTypSts";
BA_ "Origin" SG_ 760 L_FGAChanTypSts "fuel,ev";
BA_ "GenSigCycleTime" SG_ 720 FG_Chan1Typ 100;
BA_ "Match" SG_ 720 FG_Chan1Typ "FG_Chan1Typ";
BA_ "Origin" SG_ 720 FG_Chan1Typ "fuel,ev";
BA_ "GenSigCycleTime" SG_ 720 FG_Chan2Typ 100;
BA_ "Match" SG_ 720 FG_Chan2Typ "FG_Chan2Typ";
BA_ "Origin" SG_ 720 FG_Chan2Typ "fuel,ev";
BA_ "GenSigCycleTime" SG_ 720 FG_Chan3Typ 100;
BA_ "Match" SG_ 720 FG_Chan3Typ "FG_Chan3Typ";
BA_ "Origin" SG_ 720 FG_Chan3Typ "fuel,ev";
BA_ "GenSigCycleTime" SG_ 720 L_FGAChan1IllegalitySts 100;
BA_ "Match" SG_ 720 L_FGAChan1IllegalitySts "L_FGAChan1IllegalitySts";
BA_ "Origin" SG_ 720 L_FGAChan1IllegalitySts "fuel,ev";
BA_ "GenSigCycleTime" SG_ 720 L_FGAChan2IllegalitySts 100;
BA_ "Match" SG_ 720 L_FGAChan2IllegalitySts "L_FGAChan2IllegalitySts";
BA_ "Origin" SG_ 720 L_FGAChan2IllegalitySts "fuel,ev";
BA_ "GenSigCycleTime" SG_ 720 L_FGAChan3IllegalitySts 100;
BA_ "Match" SG_ 720 L_FGAChan3IllegalitySts "L_FGAChan3IllegalitySts";
BA_ "Origin" SG_ 720 L_FGAChan3IllegalitySts "fuel,ev";
BA_ "GenSigCycleTime" SG_ 636 RearInCarTemp 50;
BA_ "GenSigStartValue" SG_ 636 RearInCarTemp 254;
BA_ "Match" SG_ 636 RearInCarTemp "RearInCarTemp";
BA_ "Origin" SG_ 636 RearInCarTemp "fuel,ev";
BA_ "GenSigCycleTime" SG_ 636 ACRLTemp_ATC 50;
BA_ "GenSigStartValue" SG_ 636 ACRLTemp_ATC 33;
BA_ "Match" SG_ 636 ACRLTemp_ATC "ACRLTemp_ATC";
BA_ "Origin" SG_ 636 ACRLTemp_ATC "fuel,ev";
BA_ "GenSigCycleTime" SG_ 665 FGA_Chan1LongTyp 100;
BA_ "Match" SG_ 665 FGA_Chan1LongTyp "FGA_Chan1LongTyp";
BA_ "Origin" SG_ 665 FGA_Chan1LongTyp "fuel,ev";
BA_ "GenSigCycleTime" SG_ 665 FGA_Chan2LongTyp 100;
BA_ "Match" SG_ 665 FGA_Chan2LongTyp "FGA_Chan2LongTyp";
BA_ "Origin" SG_ 665 FGA_Chan2LongTyp "fuel,ev";
BA_ "GenSigCycleTime" SG_ 665 FGA_Chan3LongTyp 100;
BA_ "Match" SG_ 665 FGA_Chan3LongTyp "FGA_Chan3LongTyp";
BA_ "Origin" SG_ 665 FGA_Chan3LongTyp "fuel,ev";
BA_ "GenSigCycleTime" SG_ 683 ACC_LeTgt_02_Dy 100;
BA_ "Match" SG_ 683 ACC_LeTgt_02_Dy "ACC_LeTgt_02_Dy";
BA_ "Origin" SG_ 683 ACC_LeTgt_02_Dy "fuel,ev";
BA_ "GenSigCycleTime" SG_ 683 ACC_LeTgt_02_Dx 100;
BA_ "Match" SG_ 683 ACC_LeTgt_02_Dx "ACC_LeTgt_02_Dx";
BA_ "Origin" SG_ 683 ACC_LeTgt_02_Dx "fuel,ev";
BA_ "GenSigCycleTime" SG_ 683 ACC_LeTgt_02_Typ 100;
BA_ "Match" SG_ 683 ACC_LeTgt_02_Typ "ACC_LeTgt_02_Typ";
BA_ "Origin" SG_ 683 ACC_LeTgt_02_Typ "fuel,ev";
BA_ "GenSigCycleTime" SG_ 683 ACC_LeTargrt_02_Detn 100;
BA_ "Match" SG_ 683 ACC_LeTargrt_02_Detn "ACC_LeTargrt_02_Detn";
BA_ "Origin" SG_ 683 ACC_LeTargrt_02_Detn "fuel,ev";
BA_ "GenSigCycleTime" SG_ 683 ACC_RiTargrt_02_Detn 100;
BA_ "Match" SG_ 683 ACC_RiTargrt_02_Detn "ACC_RiTargrt_02_Detn";
BA_ "Origin" SG_ 683 ACC_RiTargrt_02_Detn "fuel,ev";
BA_ "GenSigCycleTime" SG_ 683 ACC_RiTgt_02_Dy 100;
BA_ "Match" SG_ 683 ACC_RiTgt_02_Dy "ACC_RiTgt_02_Dy";
BA_ "Origin" SG_ 683 ACC_RiTgt_02_Dy "fuel,ev";
BA_ "GenSigCycleTime" SG_ 683 ACC_RiTgt_02_Dx 100;
BA_ "Match" SG_ 683 ACC_RiTgt_02_Dx "ACC_RiTgt_02_Dx";
BA_ "Origin" SG_ 683 ACC_RiTgt_02_Dx "fuel,ev";
BA_ "GenSigCycleTime" SG_ 683 ACC_RiTgt_02_Typ 100;
BA_ "Match" SG_ 683 ACC_RiTgt_02_Typ "ACC_RiTgt_02_Typ";
BA_ "Origin" SG_ 683 ACC_RiTgt_02_Typ "fuel,ev";
BA_ "GenSigCycleTime" SG_ 683 ACC_LeTgtObjBarDisp 100;
BA_ "Match" SG_ 683 ACC_LeTgtObjBarDisp "ACC_LeTgtObjBarDisp";
BA_ "Origin" SG_ 683 ACC_LeTgtObjBarDisp "fuel,ev";
BA_ "GenSigCycleTime" SG_ 683 ACC_RiTgtObjBarDisp 100;
BA_ "Match" SG_ 683 ACC_RiTgtObjBarDisp "ACC_RiTgtObjBarDisp";
BA_ "Origin" SG_ 683 ACC_RiTgtObjBarDisp "fuel,ev";
BA_ "GenSigCycleTime" SG_ 683 Checksum_ACC3 100;
BA_ "Match" SG_ 683 Checksum_ACC3 "Checksum_ACC3";
BA_ "Origin" SG_ 683 Checksum_ACC3 "fuel,ev";
BA_ "GenSigCycleTime" SG_ 683 ICA_HandsOffResp 100;
BA_ "Match" SG_ 683 ICA_HandsOffResp "ICA_HandsOffResp";
BA_ "Origin" SG_ 683 ICA_HandsOffResp "fuel,ev";
BA_ "GenSigCycleTime" SG_ 683 ALC_Resp 100;
BA_ "Match" SG_ 683 ALC_Resp "ALC_Resp";
BA_ "Origin" SG_ 683 ALC_Resp "fuel,ev";
BA_ "GenSigCycleTime" SG_ 683 HWA_Resp 100;
BA_ "Match" SG_ 683 HWA_Resp "HWA_Resp";
BA_ "Origin" SG_ 683 HWA_Resp "fuel,ev";
BA_ "GenSigCycleTime" SG_ 683 ISL_Resp 100;
BA_ "Match" SG_ 683 ISL_Resp "ISL_Resp";
BA_ "Origin" SG_ 683 ISL_Resp "fuel,ev";
BA_ "GenSigCycleTime" SG_ 683 HWA_SnvtySet_Resp 100;
BA_ "Match" SG_ 683 HWA_SnvtySet_Resp "HWA_SnvtySet_Resp";
BA_ "Origin" SG_ 683 HWA_SnvtySet_Resp "fuel,ev";
BA_ "GenSigCycleTime" SG_ 683 Longctrl_VehHldReq_DVR 100;
BA_ "Match" SG_ 683 Longctrl_VehHldReq_DVR "Longctrl_VehHldReq_DVR";
BA_ "Origin" SG_ 683 Longctrl_VehHldReq_DVR "fuel,ev";
BA_ "GenSigCycleTime" SG_ 683 Longctrl_DrvOFF_Req_DVR 100;
BA_ "Match" SG_ 683 Longctrl_DrvOFF_Req_DVR "Longctrl_DrvOFF_Req_DVR";
BA_ "Origin" SG_ 683 Longctrl_DrvOFF_Req_DVR "fuel,ev";
BA_ "GenSigCycleTime" SG_ 683 Longctrl_ModSts_DVR 100;
BA_ "GenSigStartValue" SG_ 683 Longctrl_ModSts_DVR 1;
BA_ "Match" SG_ 683 Longctrl_ModSts_DVR "Longctrl_ModSts_DVR";
BA_ "Origin" SG_ 683 Longctrl_ModSts_DVR "fuel,ev";
BA_ "GenSigCycleTime" SG_ 683 Longctrl_Decel_Req_DVR 100;
BA_ "Match" SG_ 683 Longctrl_Decel_Req_DVR "Longctrl_Decel_Req_DVR";
BA_ "Origin" SG_ 683 Longctrl_Decel_Req_DVR "fuel,ev";
BA_ "GenSigCycleTime" SG_ 683 Longctrl_EngTrqReq_DVR 100;
BA_ "GenSigStartValue" SG_ 683 Longctrl_EngTrqReq_DVR 32767;
BA_ "Match" SG_ 683 Longctrl_EngTrqReq_DVR "Longctrl_EngTrqReq_DVR";
BA_ "Origin" SG_ 683 Longctrl_EngTrqReq_DVR "fuel,ev";
BA_ "GenSigCycleTime" SG_ 683 Longctrl_EngTrqReqActive_DVR 100;
BA_ "Match" SG_ 683 Longctrl_EngTrqReqActive_DVR "Longctrl_EngTrqReqActive_DVR";
BA_ "Origin" SG_ 683 Longctrl_EngTrqReqActive_DVR "fuel,ev";
BA_ "GenSigCycleTime" SG_ 683 Longctrl_DecelToStopReq_DVR 100;
BA_ "Match" SG_ 683 Longctrl_DecelToStopReq_DVR "Longctrl_DecelToStopReq_DVR";
BA_ "Origin" SG_ 683 Longctrl_DecelToStopReq_DVR "fuel,ev";
BA_ "GenSigCycleTime" SG_ 683 Longctrl_ParkShiftReq_DVR 100;
BA_ "Match" SG_ 683 Longctrl_ParkShiftReq_DVR "Longctrl_ParkShiftReq_DVR";
BA_ "Origin" SG_ 683 Longctrl_ParkShiftReq_DVR "fuel,ev";
BA_ "GenSigCycleTime" SG_ 683 Longctrl_Decel_ReqValue_DVR 100;
BA_ "Match" SG_ 683 Longctrl_Decel_ReqValue_DVR "Longctrl_Decel_ReqValue_DVR";
BA_ "Origin" SG_ 683 Longctrl_Decel_ReqValue_DVR "fuel,ev";
BA_ "GenSigCycleTime" SG_ 683 ALC_InterSysInfoDisp 100;
BA_ "Match" SG_ 683 ALC_InterSysInfoDisp "ALC_InterSysInfoDisp";
BA_ "Origin" SG_ 683 ALC_InterSysInfoDisp "fuel,ev";
BA_ "GenSigCycleTime" SG_ 683 RollingCounter_ACC3 100;
BA_ "Match" SG_ 683 RollingCounter_ACC3 "RollingCounter_ACC3";
BA_ "Origin" SG_ 683 RollingCounter_ACC3 "fuel,ev";
BA_ "GenSigCycleTime" SG_ 683 Checksum_ACC4 100;
BA_ "Match" SG_ 683 Checksum_ACC4 "Checksum_ACC4";
BA_ "Origin" SG_ 683 Checksum_ACC4 "fuel,ev";
BA_ "GenSigCycleTime" SG_ 683 ACC_ObjDetecte 100;
BA_ "Match" SG_ 683 ACC_ObjDetecte "ACC_ObjDetecte";
BA_ "Origin" SG_ 683 ACC_ObjDetecte "fuel,ev";
BA_ "GenSigCycleTime" SG_ 683 ACC_TakeOverReq 100;
BA_ "Match" SG_ 683 ACC_TakeOverReq "ACC_TakeOverReq";
BA_ "Origin" SG_ 683 ACC_TakeOverReq "fuel,ev";
BA_ "GenSigCycleTime" SG_ 683 ACC_InterSysInfoDisp 100;
BA_ "Match" SG_ 683 ACC_InterSysInfoDisp "ACC_InterSysInfoDisp";
BA_ "Origin" SG_ 683 ACC_InterSysInfoDisp "fuel,ev";
BA_ "GenSigCycleTime" SG_ 683 ACC_ModDisp 100;
BA_ "GenSigStartValue" SG_ 683 ACC_ModDisp 1;
BA_ "Match" SG_ 683 ACC_ModDisp "ACC_ModDisp";
BA_ "Origin" SG_ 683 ACC_ModDisp "fuel,ev";
BA_ "GenSigCycleTime" SG_ 683 ACC_FctSts 100;
BA_ "Match" SG_ 683 ACC_FctSts "ACC_FctSts";
BA_ "Origin" SG_ 683 ACC_FctSts "fuel,ev";
BA_ "GenSigCycleTime" SG_ 683 ACC_TgtObjBarDisp 100;
BA_ "Match" SG_ 683 ACC_TgtObjBarDisp "ACC_TgtObjBarDisp";
BA_ "Origin" SG_ 683 ACC_TgtObjBarDisp "fuel,ev";
BA_ "GenSigCycleTime" SG_ 683 Longctrl_HazActv 100;
BA_ "Match" SG_ 683 Longctrl_HazActv "Longctrl_HazActv";
BA_ "Origin" SG_ 683 Longctrl_HazActv "fuel,ev";
BA_ "GenSigCycleTime" SG_ 683 TJA_ACC_SelSts 100;
BA_ "Match" SG_ 683 TJA_ACC_SelSts "TJA_ACC_SelSts";
BA_ "Origin" SG_ 683 TJA_ACC_SelSts "fuel,ev";
BA_ "GenSigCycleTime" SG_ 683 CruCha_ModDisp 100;
BA_ "Match" SG_ 683 CruCha_ModDisp "CruCha_ModDisp";
BA_ "Origin" SG_ 683 CruCha_ModDisp "fuel,ev";
BA_ "GenSigCycleTime" SG_ 683 TJA_ICA_InterSysInfoDisp 100;
BA_ "Match" SG_ 683 TJA_ICA_InterSysInfoDisp "TJA_ICA_InterSysInfoDisp";
BA_ "Origin" SG_ 683 TJA_ICA_InterSysInfoDisp "fuel,ev";
BA_ "GenSigCycleTime" SG_ 683 TJA_ICA_ModDisp 100;
BA_ "GenSigStartValue" SG_ 683 TJA_ICA_ModDisp 1;
BA_ "Match" SG_ 683 TJA_ICA_ModDisp "TJA_ICA_ModDisp";
BA_ "Origin" SG_ 683 TJA_ICA_ModDisp "fuel,ev";
BA_ "GenSigCycleTime" SG_ 683 ISL_InterSysInfoDisp 100;
BA_ "Match" SG_ 683 ISL_InterSysInfoDisp "ISL_InterSysInfoDisp";
BA_ "Origin" SG_ 683 ISL_InterSysInfoDisp "fuel,ev";
BA_ "GenSigCycleTime" SG_ 683 ACC_TimeGapSet 100;
BA_ "Match" SG_ 683 ACC_TimeGapSet "ACC_TimeGapSet";
BA_ "Origin" SG_ 683 ACC_TimeGapSet "fuel,ev";
BA_ "GenSigCycleTime" SG_ 683 ACC_SpdSetValue 100;
BA_ "GenSigStartValue" SG_ 683 ACC_SpdSetValue 255;
BA_ "Match" SG_ 683 ACC_SpdSetValue "ACC_SpdSetValue";
BA_ "Origin" SG_ 683 ACC_SpdSetValue "fuel,ev";
BA_ "GenSigCycleTime" SG_ 683 CruChar_InterSysInfoDisp 100;
BA_ "Match" SG_ 683 CruChar_InterSysInfoDisp "CruChar_InterSysInfoDisp";
BA_ "Origin" SG_ 683 CruChar_InterSysInfoDisp "fuel,ev";
BA_ "GenSigCycleTime" SG_ 683 RollingCounter_ACC4 100;
BA_ "Match" SG_ 683 RollingCounter_ACC4 "RollingCounter_ACC4";
BA_ "Origin" SG_ 683 RollingCounter_ACC4 "fuel,ev";
BA_ "GenSigCycleTime" SG_ 683 Checksum_ACC8 100;
BA_ "Match" SG_ 683 Checksum_ACC8 "Checksum_ACC8";
BA_ "Origin" SG_ 683 Checksum_ACC8 "fuel,ev";
BA_ "GenSigCycleTime" SG_ 683 HWA_ModDisp 100;
BA_ "Match" SG_ 683 HWA_ModDisp "HWA_ModDisp";
BA_ "Origin" SG_ 683 HWA_ModDisp "fuel,ev";
BA_ "GenSigCycleTime" SG_ 683 HWA_InterSysInfoDisp 100;
BA_ "Match" SG_ 683 HWA_InterSysInfoDisp "HWA_InterSysInfoDisp";
BA_ "Origin" SG_ 683 HWA_InterSysInfoDisp "fuel,ev";
BA_ "GenSigCycleTime" SG_ 683 HWA_LaneChange 100;
BA_ "Match" SG_ 683 HWA_LaneChange "HWA_LaneChange";
BA_ "Origin" SG_ 683 HWA_LaneChange "fuel,ev";
BA_ "GenSigCycleTime" SG_ 683 HWA_LaneChangeReq 100;
BA_ "Match" SG_ 683 HWA_LaneChangeReq "HWA_LaneChangeReq";
BA_ "Origin" SG_ 683 HWA_LaneChangeReq "fuel,ev";
BA_ "GenSigCycleTime" SG_ 683 HWA_Warning 100;
BA_ "Match" SG_ 683 HWA_Warning "HWA_Warning";
BA_ "Origin" SG_ 683 HWA_Warning "fuel,ev";
BA_ "GenSigCycleTime" SG_ 683 RollingCounter_ACC8 100;
BA_ "Match" SG_ 683 RollingCounter_ACC8 "RollingCounter_ACC8";
BA_ "Origin" SG_ 683 RollingCounter_ACC8 "fuel,ev";
BA_ "GenSigCycleTime" SG_ 683 Checksum_ACC6 100;
BA_ "Match" SG_ 683 Checksum_ACC6 "Checksum_ACC6";
BA_ "Origin" SG_ 683 Checksum_ACC6 "fuel,ev";
BA_ "GenSigCycleTime" SG_ 683 ACC_PotentialTgtDy 100;
BA_ "Match" SG_ 683 ACC_PotentialTgtDy "ACC_PotentialTgtDy";
BA_ "Origin" SG_ 683 ACC_PotentialTgtDy "fuel,ev";
BA_ "GenSigCycleTime" SG_ 683 ACC_PotentialTgtDx 100;
BA_ "Match" SG_ 683 ACC_PotentialTgtDx "ACC_PotentialTgtDx";
BA_ "Origin" SG_ 683 ACC_PotentialTgtDx "fuel,ev";
BA_ "GenSigCycleTime" SG_ 683 ACC_RlvTgtDetn 100;
BA_ "Match" SG_ 683 ACC_RlvTgtDetn "ACC_RlvTgtDetn";
BA_ "Origin" SG_ 683 ACC_RlvTgtDetn "fuel,ev";
BA_ "GenSigCycleTime" SG_ 683 ACC_EgoStatus 100;
BA_ "Match" SG_ 683 ACC_EgoStatus "ACC_EgoStatus";
BA_ "Origin" SG_ 683 ACC_EgoStatus "fuel,ev";
BA_ "GenSigCycleTime" SG_ 683 ACC_RlvTgtTyp 100;
BA_ "Match" SG_ 683 ACC_RlvTgtTyp "ACC_RlvTgtTyp";
BA_ "Origin" SG_ 683 ACC_RlvTgtTyp "fuel,ev";
BA_ "GenSigCycleTime" SG_ 683 ACC_RlvTgtDy 100;
BA_ "Match" SG_ 683 ACC_RlvTgtDy "ACC_RlvTgtDy";
BA_ "Origin" SG_ 683 ACC_RlvTgtDy "fuel,ev";
BA_ "GenSigCycleTime" SG_ 683 ACC_RlvTgtDx 100;
BA_ "Match" SG_ 683 ACC_RlvTgtDx "ACC_RlvTgtDx";
BA_ "Origin" SG_ 683 ACC_RlvTgtDx "fuel,ev";
BA_ "GenSigCycleTime" SG_ 683 ACC_PotentialTgtDetn 100;
BA_ "Match" SG_ 683 ACC_PotentialTgtDetn "ACC_PotentialTgtDetn";
BA_ "Origin" SG_ 683 ACC_PotentialTgtDetn "fuel,ev";
BA_ "GenSigCycleTime" SG_ 683 ACC_PotentialTgtTyp 100;
BA_ "Match" SG_ 683 ACC_PotentialTgtTyp "ACC_PotentialTgtTyp";
BA_ "Origin" SG_ 683 ACC_PotentialTgtTyp "fuel,ev";
BA_ "GenSigCycleTime" SG_ 683 RollingCounter_ACC6 100;
BA_ "Match" SG_ 683 RollingCounter_ACC6 "RollingCounter_ACC6";
BA_ "Origin" SG_ 683 RollingCounter_ACC6 "fuel,ev";
BA_ "GenSigCycleTime" SG_ 683 Checksum_ACC7 100;
BA_ "Match" SG_ 683 Checksum_ACC7 "Checksum_ACC7";
BA_ "Origin" SG_ 683 Checksum_ACC7 "fuel,ev";
BA_ "GenSigCycleTime" SG_ 683 Request_driveoff 100;
BA_ "Match" SG_ 683 Request_driveoff "Request_driveoff";
BA_ "Origin" SG_ 683 Request_driveoff "fuel,ev";
BA_ "GenSigCycleTime" SG_ 683 ACCSts 100;
BA_ "Match" SG_ 683 ACCSts "ACCSts";
BA_ "Origin" SG_ 683 ACCSts "fuel,ev";
BA_ "GenSigCycleTime" SG_ 683 ACC_LeTgtDy 100;
BA_ "Match" SG_ 683 ACC_LeTgtDy "ACC_LeTgtDy";
BA_ "Origin" SG_ 683 ACC_LeTgtDy "fuel,ev";
BA_ "GenSigCycleTime" SG_ 683 ACC_LeTgtDx 100;
BA_ "Match" SG_ 683 ACC_LeTgtDx "ACC_LeTgtDx";
BA_ "Origin" SG_ 683 ACC_LeTgtDx "fuel,ev";
BA_ "GenSigCycleTime" SG_ 683 ACC_LeTgtTyp 100;
BA_ "Match" SG_ 683 ACC_LeTgtTyp "ACC_LeTgtTyp";
BA_ "Origin" SG_ 683 ACC_LeTgtTyp "fuel,ev";
BA_ "GenSigCycleTime" SG_ 683 ACC_LeTargrtDection 100;
BA_ "Match" SG_ 683 ACC_LeTargrtDection "ACC_LeTargrtDection";
BA_ "Origin" SG_ 683 ACC_LeTargrtDection "fuel,ev";
BA_ "GenSigCycleTime" SG_ 683 ACC_RiTargrtDetn 100;
BA_ "Match" SG_ 683 ACC_RiTargrtDetn "ACC_RiTargrtDetn";
BA_ "Origin" SG_ 683 ACC_RiTargrtDetn "fuel,ev";
BA_ "GenSigCycleTime" SG_ 683 ACC_RiTgtDy 100;
BA_ "Match" SG_ 683 ACC_RiTgtDy "ACC_RiTgtDy";
BA_ "Origin" SG_ 683 ACC_RiTgtDy "fuel,ev";
BA_ "GenSigCycleTime" SG_ 683 ACC_RiTgtDx 100;
BA_ "Match" SG_ 683 ACC_RiTgtDx "ACC_RiTgtDx";
BA_ "Origin" SG_ 683 ACC_RiTgtDx "fuel,ev";
BA_ "GenSigCycleTime" SG_ 683 ACC_RiTgtTyp 100;
BA_ "Match" SG_ 683 ACC_RiTgtTyp "ACC_RiTgtTyp";
BA_ "Origin" SG_ 683 ACC_RiTgtTyp "fuel,ev";
BA_ "GenSigCycleTime" SG_ 683 RollingCounter_ACC7 100;
BA_ "Match" SG_ 683 RollingCounter_ACC7 "RollingCounter_ACC7";
BA_ "Origin" SG_ 683 RollingCounter_ACC7 "fuel,ev";
BA_ "GenSigCycleTime" SG_ 683 FreshnessValue_ACC_FD2 100;
BA_ "Match" SG_ 683 FreshnessValue_ACC_FD2 "FreshnessValue_ACC_FD2";
BA_ "Origin" SG_ 683 FreshnessValue_ACC_FD2 "fuel,ev";
BA_ "GenSigCycleTime" SG_ 683 MAC_Check_ACC_FD2 100;
BA_ "Match" SG_ 683 MAC_Check_ACC_FD2 "MAC_Check_ACC_FD2";
BA_ "Origin" SG_ 683 MAC_Check_ACC_FD2 "fuel,ev";
BA_ "GenSigCycleTime" SG_ 683 ACC_RlvTgtfusion 100;
BA_ "Match" SG_ 683 ACC_RlvTgtfusion "ACC_RlvTgtfusion";
BA_ "Origin" SG_ 683 ACC_RlvTgtfusion "fuel,ev";
BA_ "GenSigCycleTime" SG_ 683 ACC_RlvTgtHeading 100;
BA_ "GenSigStartValue" SG_ 683 ACC_RlvTgtHeading 30;
BA_ "Match" SG_ 683 ACC_RlvTgtHeading "ACC_RlvTgtHeading";
BA_ "Origin" SG_ 683 ACC_RlvTgtHeading "fuel,ev";
BA_ "GenSigCycleTime" SG_ 683 ACC_LeTgtfusion 100;
BA_ "Match" SG_ 683 ACC_LeTgtfusion "ACC_LeTgtfusion";
BA_ "Origin" SG_ 683 ACC_LeTgtfusion "fuel,ev";
BA_ "GenSigCycleTime" SG_ 683 ACC_LeTgtHeading 100;
BA_ "GenSigStartValue" SG_ 683 ACC_LeTgtHeading 30;
BA_ "Match" SG_ 683 ACC_LeTgtHeading "ACC_LeTgtHeading";
BA_ "Origin" SG_ 683 ACC_LeTgtHeading "fuel,ev";
BA_ "GenSigCycleTime" SG_ 683 ACC_RiTgtfusion 100;
BA_ "Match" SG_ 683 ACC_RiTgtfusion "ACC_RiTgtfusion";
BA_ "Origin" SG_ 683 ACC_RiTgtfusion "fuel,ev";
BA_ "GenSigCycleTime" SG_ 683 ACC_RiTgtHeading 100;
BA_ "GenSigStartValue" SG_ 683 ACC_RiTgtHeading 30;
BA_ "Match" SG_ 683 ACC_RiTgtHeading "ACC_RiTgtHeading";
BA_ "Origin" SG_ 683 ACC_RiTgtHeading "fuel,ev";
BA_ "GenSigCycleTime" SG_ 683 ACC_PotentialTgtfusion 100;
BA_ "Match" SG_ 683 ACC_PotentialTgtfusion "ACC_PotentialTgtfusion";
BA_ "Origin" SG_ 683 ACC_PotentialTgtfusion "fuel,ev";
BA_ "GenSigCycleTime" SG_ 683 ACC_PotentialTgtHeading 100;
BA_ "GenSigStartValue" SG_ 683 ACC_PotentialTgtHeading 30;
BA_ "Match" SG_ 683 ACC_PotentialTgtHeading "ACC_PotentialTgtHeading";
BA_ "Origin" SG_ 683 ACC_PotentialTgtHeading "fuel,ev";
BA_ "GenSigCycleTime" SG_ 683 TargetCutinPro 100;
BA_ "Match" SG_ 683 TargetCutinPro "TargetCutinPro";
BA_ "Origin" SG_ 683 TargetCutinPro "fuel,ev";
BA_ "GenSigCycleTime" SG_ 683 TargetCutoutPro 100;
BA_ "Match" SG_ 683 TargetCutoutPro "TargetCutoutPro";
BA_ "Origin" SG_ 683 TargetCutoutPro "fuel,ev";
BA_ "GenSigCycleTime" SG_ 683 Longctrl_WheelTrqReqActive_DVR 100;
BA_ "Match" SG_ 683 Longctrl_WheelTrqReqActive_DVR "Longctrl_WheelTrqReqActive_DVR";
BA_ "Origin" SG_ 683 Longctrl_WheelTrqReqActive_DVR "ev";
BA_ "GenSigCycleTime" SG_ 683 Longctrl_WheelTrqReq_DVR 100;
BA_ "Match" SG_ 683 Longctrl_WheelTrqReq_DVR "Longctrl_WheelTrqReq_DVR";
BA_ "Origin" SG_ 683 Longctrl_WheelTrqReq_DVR "ev";
BA_ "GenSigCycleTime" SG_ 692 JAPedObjExist 100;
BA_ "Match" SG_ 692 JAPedObjExist "JAPedObjExist";
BA_ "Origin" SG_ 692 JAPedObjExist "fuel,ev";
BA_ "GenSigCycleTime" SG_ 692 AEBJAObjID 100;
BA_ "GenSigStartValue" SG_ 692 AEBJAObjID 255;
BA_ "Match" SG_ 692 AEBJAObjID "AEBJAObjID";
BA_ "Origin" SG_ 692 AEBJAObjID "fuel,ev";
BA_ "GenSigCycleTime" SG_ 692 AEBJAObjExist 100;
BA_ "Match" SG_ 692 AEBJAObjExist "AEBJAObjExist";
BA_ "Origin" SG_ 692 AEBJAObjExist "fuel,ev";
BA_ "GenSigCycleTime" SG_ 692 JAPedObjID 100;
BA_ "GenSigStartValue" SG_ 692 JAPedObjID 255;
BA_ "Match" SG_ 692 JAPedObjID "JAPedObjID";
BA_ "Origin" SG_ 692 JAPedObjID "fuel,ev";
BA_ "GenSigCycleTime" SG_ 692 AEBJAObjVideoCfmd 100;
BA_ "Match" SG_ 692 AEBJAObjVideoCfmd "AEBJAObjVideoCfmd";
BA_ "Origin" SG_ 692 AEBJAObjVideoCfmd "fuel,ev";
BA_ "GenSigCycleTime" SG_ 692 AEBJAObjVx 100;
BA_ "Match" SG_ 692 AEBJAObjVx "AEBJAObjVx";
BA_ "Origin" SG_ 692 AEBJAObjVx "fuel,ev";
BA_ "GenSigCycleTime" SG_ 692 AEBJAObjDx 100;
BA_ "Match" SG_ 692 AEBJAObjDx "AEBJAObjDx";
BA_ "Origin" SG_ 692 AEBJAObjDx "fuel,ev";
BA_ "GenSigCycleTime" SG_ 692 JAPedObjVideoCfmd 100;
BA_ "Match" SG_ 692 JAPedObjVideoCfmd "JAPedObjVideoCfmd";
BA_ "Origin" SG_ 692 JAPedObjVideoCfmd "fuel,ev";
BA_ "GenSigCycleTime" SG_ 692 AEBJAObjState 100;
BA_ "Match" SG_ 692 AEBJAObjState "AEBJAObjState";
BA_ "Origin" SG_ 692 AEBJAObjState "fuel,ev";
BA_ "GenSigCycleTime" SG_ 692 AEBJAObjCntAlive 100;
BA_ "Match" SG_ 692 AEBJAObjCntAlive "AEBJAObjCntAlive";
BA_ "Origin" SG_ 692 AEBJAObjCntAlive "fuel,ev";
BA_ "GenSigCycleTime" SG_ 692 AEBJAObjDy 100;
BA_ "Match" SG_ 692 AEBJAObjDy "AEBJAObjDy";
BA_ "Origin" SG_ 692 AEBJAObjDy "fuel,ev";
BA_ "GenSigCycleTime" SG_ 692 JAPedObjState 100;
BA_ "Match" SG_ 692 JAPedObjState "JAPedObjState";
BA_ "Origin" SG_ 692 JAPedObjState "fuel,ev";
BA_ "GenSigCycleTime" SG_ 692 AEBJAObjObstcl 100;
BA_ "Match" SG_ 692 AEBJAObjObstcl "AEBJAObjObstcl";
BA_ "Origin" SG_ 692 AEBJAObjObstcl "fuel,ev";
BA_ "GenSigCycleTime" SG_ 692 AEBJAObjVy 100;
BA_ "Match" SG_ 692 AEBJAObjVy "AEBJAObjVy";
BA_ "Origin" SG_ 692 AEBJAObjVy "fuel,ev";
BA_ "GenSigCycleTime" SG_ 692 AEBJAObjAx 100;
BA_ "Match" SG_ 692 AEBJAObjAx "AEBJAObjAx";
BA_ "Origin" SG_ 692 AEBJAObjAx "fuel,ev";
BA_ "GenSigCycleTime" SG_ 692 AEBJAObjAy 100;
BA_ "Match" SG_ 692 AEBJAObjAy "AEBJAObjAy";
BA_ "Origin" SG_ 692 AEBJAObjAy "fuel,ev";
BA_ "GenSigCycleTime" SG_ 692 JAPedObjObstcl 100;
BA_ "Match" SG_ 692 JAPedObjObstcl "JAPedObjObstcl";
BA_ "Origin" SG_ 692 JAPedObjObstcl "fuel,ev";
BA_ "GenSigCycleTime" SG_ 692 JAPedObjDy 100;
BA_ "Match" SG_ 692 JAPedObjDy "JAPedObjDy";
BA_ "Origin" SG_ 692 JAPedObjDy "fuel,ev";
BA_ "GenSigCycleTime" SG_ 692 JAPedObjDx 100;
BA_ "Match" SG_ 692 JAPedObjDx "JAPedObjDx";
BA_ "Origin" SG_ 692 JAPedObjDx "fuel,ev";
BA_ "GenSigCycleTime" SG_ 692 FCWAEB_JATTC 100;
BA_ "Match" SG_ 692 FCWAEB_JATTC "FCWAEB_JATTC";
BA_ "Origin" SG_ 692 FCWAEB_JATTC "fuel,ev";
BA_ "GenSigCycleTime" SG_ 692 JAPedObjVx 100;
BA_ "Match" SG_ 692 JAPedObjVx "JAPedObjVx";
BA_ "Origin" SG_ 692 JAPedObjVx "fuel,ev";
BA_ "GenSigCycleTime" SG_ 692 JAPedObjVy 100;
BA_ "Match" SG_ 692 JAPedObjVy "JAPedObjVy";
BA_ "Origin" SG_ 692 JAPedObjVy "fuel,ev";
BA_ "GenSigCycleTime" SG_ 692 JAPedObjAy 100;
BA_ "Match" SG_ 692 JAPedObjAy "JAPedObjAy";
BA_ "Origin" SG_ 692 JAPedObjAy "fuel,ev";
BA_ "GenSigCycleTime" SG_ 692 JAPedObjCntAlive 100;
BA_ "Match" SG_ 692 JAPedObjCntAlive "JAPedObjCntAlive";
BA_ "Origin" SG_ 692 JAPedObjCntAlive "fuel,ev";
BA_ "GenSigCycleTime" SG_ 692 FCWAEB_longTTC 100;
BA_ "Match" SG_ 692 FCWAEB_longTTC "FCWAEB_longTTC";
BA_ "Origin" SG_ 692 FCWAEB_longTTC "fuel,ev";
BA_ "GenSigCycleTime" SG_ 692 FCWAEB_crossingTTC 100;
BA_ "Match" SG_ 692 FCWAEB_crossingTTC "FCWAEB_crossingTTC";
BA_ "Origin" SG_ 692 FCWAEB_crossingTTC "fuel,ev";
BA_ "GenSigCycleTime" SG_ 692 JAPedObjAx 100;
BA_ "Match" SG_ 692 JAPedObjAx "JAPedObjAx";
BA_ "Origin" SG_ 692 JAPedObjAx "fuel,ev";
BA_ "GenSigCycleTime" SG_ 692 NOH_Sts 100;
BA_ "Match" SG_ 692 NOH_Sts "NOH_Sts";
BA_ "Origin" SG_ 692 NOH_Sts "fuel,ev";
BA_ "GenSigCycleTime" SG_ 692 NOH_Swt_Resp 100;
BA_ "Match" SG_ 692 NOH_Swt_Resp "NOH_Swt_Resp";
BA_ "Origin" SG_ 692 NOH_Swt_Resp "fuel,ev";
BA_ "GenSigCycleTime" SG_ 692 NOH_Act_Resp 100;
BA_ "Match" SG_ 692 NOH_Act_Resp "NOH_Act_Resp";
BA_ "Origin" SG_ 692 NOH_Act_Resp "fuel,ev";
BA_ "GenSigCycleTime" SG_ 692 NOH_SysInfoDisplay 100;
BA_ "Match" SG_ 692 NOH_SysInfoDisplay "NOH_SysInfoDisplay";
BA_ "Origin" SG_ 692 NOH_SysInfoDisplay "fuel,ev";
BA_ "GenSigCycleTime" SG_ 692 NOH_DistToExit 100;
BA_ "Match" SG_ 692 NOH_DistToExit "NOH_DistToExit";
BA_ "Origin" SG_ 692 NOH_DistToExit "fuel,ev";
BA_ "GenSigCycleTime" SG_ 696 AEBObjID 100;
BA_ "GenSigStartValue" SG_ 696 AEBObjID 255;
BA_ "Match" SG_ 696 AEBObjID "AEBObjID";
BA_ "Origin" SG_ 696 AEBObjID "fuel,ev";
BA_ "GenSigCycleTime" SG_ 696 AEBObjExist 100;
BA_ "Match" SG_ 696 AEBObjExist "AEBObjExist";
BA_ "Origin" SG_ 696 AEBObjExist "fuel,ev";
BA_ "GenSigCycleTime" SG_ 696 AEBObjVideoCfmd 100;
BA_ "Match" SG_ 696 AEBObjVideoCfmd "AEBObjVideoCfmd";
BA_ "Origin" SG_ 696 AEBObjVideoCfmd "fuel,ev";
BA_ "GenSigCycleTime" SG_ 696 AEBObjVx 100;
BA_ "Match" SG_ 696 AEBObjVx "AEBObjVx";
BA_ "Origin" SG_ 696 AEBObjVx "fuel,ev";
BA_ "GenSigCycleTime" SG_ 696 AEBObjDx 100;
BA_ "Match" SG_ 696 AEBObjDx "AEBObjDx";
BA_ "Origin" SG_ 696 AEBObjDx "fuel,ev";
BA_ "GenSigCycleTime" SG_ 696 AEBObjCntAlive 100;
BA_ "Match" SG_ 696 AEBObjCntAlive "AEBObjCntAlive";
BA_ "Origin" SG_ 696 AEBObjCntAlive "fuel,ev";
BA_ "GenSigCycleTime" SG_ 696 AEBObjDy 100;
BA_ "Match" SG_ 696 AEBObjDy "AEBObjDy";
BA_ "Origin" SG_ 696 AEBObjDy "fuel,ev";
BA_ "GenSigCycleTime" SG_ 696 AEBObjState 100;
BA_ "Match" SG_ 696 AEBObjState "AEBObjState";
BA_ "Origin" SG_ 696 AEBObjState "fuel,ev";
BA_ "GenSigCycleTime" SG_ 696 AEBObjObstcl 100;
BA_ "Match" SG_ 696 AEBObjObstcl "AEBObjObstcl";
BA_ "Origin" SG_ 696 AEBObjObstcl "fuel,ev";
BA_ "GenSigCycleTime" SG_ 696 AEBObjVy 100;
BA_ "Match" SG_ 696 AEBObjVy "AEBObjVy";
BA_ "Origin" SG_ 696 AEBObjVy "fuel,ev";
BA_ "GenSigCycleTime" SG_ 696 CyclistObjExist 100;
BA_ "Match" SG_ 696 CyclistObjExist "CyclistObjExist";
BA_ "Origin" SG_ 696 CyclistObjExist "fuel,ev";
BA_ "GenSigCycleTime" SG_ 696 AEBObjAx 100;
BA_ "Match" SG_ 696 AEBObjAx "AEBObjAx";
BA_ "Origin" SG_ 696 AEBObjAx "fuel,ev";
BA_ "GenSigCycleTime" SG_ 696 AEBObjAy 100;
BA_ "Match" SG_ 696 AEBObjAy "AEBObjAy";
BA_ "Origin" SG_ 696 AEBObjAy "fuel,ev";
BA_ "GenSigCycleTime" SG_ 696 CyclistObjDx 100;
BA_ "Match" SG_ 696 CyclistObjDx "CyclistObjDx";
BA_ "Origin" SG_ 696 CyclistObjDx "fuel,ev";
BA_ "GenSigCycleTime" SG_ 696 CyclistObjID 100;
BA_ "GenSigStartValue" SG_ 696 CyclistObjID 255;
BA_ "Match" SG_ 696 CyclistObjID "CyclistObjID";
BA_ "Origin" SG_ 696 CyclistObjID "fuel,ev";
BA_ "GenSigCycleTime" SG_ 696 CyclistObjObstcl 100;
BA_ "Match" SG_ 696 CyclistObjObstcl "CyclistObjObstcl";
BA_ "Origin" SG_ 696 CyclistObjObstcl "fuel,ev";
BA_ "GenSigCycleTime" SG_ 696 CyclistObjDy 100;
BA_ "Match" SG_ 696 CyclistObjDy "CyclistObjDy";
BA_ "Origin" SG_ 696 CyclistObjDy "fuel,ev";
BA_ "GenSigCycleTime" SG_ 696 CyclistObjVx 100;
BA_ "Match" SG_ 696 CyclistObjVx "CyclistObjVx";
BA_ "Origin" SG_ 696 CyclistObjVx "fuel,ev";
BA_ "GenSigCycleTime" SG_ 696 CyclistObjCntAlive 100;
BA_ "Match" SG_ 696 CyclistObjCntAlive "CyclistObjCntAlive";
BA_ "Origin" SG_ 696 CyclistObjCntAlive "fuel,ev";
BA_ "GenSigCycleTime" SG_ 696 CyclistObjVy 100;
BA_ "Match" SG_ 696 CyclistObjVy "CyclistObjVy";
BA_ "Origin" SG_ 696 CyclistObjVy "fuel,ev";
BA_ "GenSigCycleTime" SG_ 696 CyclistObjState 100;
BA_ "Match" SG_ 696 CyclistObjState "CyclistObjState";
BA_ "Origin" SG_ 696 CyclistObjState "fuel,ev";
BA_ "GenSigCycleTime" SG_ 696 CyclistObjVideoCfmd 100;
BA_ "Match" SG_ 696 CyclistObjVideoCfmd "CyclistObjVideoCfmd";
BA_ "Origin" SG_ 696 CyclistObjVideoCfmd "fuel,ev";
BA_ "GenSigCycleTime" SG_ 696 CyclistObjAx 100;
BA_ "Match" SG_ 696 CyclistObjAx "CyclistObjAx";
BA_ "Origin" SG_ 696 CyclistObjAx "fuel,ev";
BA_ "GenSigCycleTime" SG_ 696 CyclistObjAy 100;
BA_ "Match" SG_ 696 CyclistObjAy "CyclistObjAy";
BA_ "Origin" SG_ 696 CyclistObjAy "fuel,ev";
BA_ "GenSigCycleTime" SG_ 696 PedObjExist 100;
BA_ "Match" SG_ 696 PedObjExist "PedObjExist";
BA_ "Origin" SG_ 696 PedObjExist "fuel,ev";
BA_ "GenSigCycleTime" SG_ 696 PedObjID 100;
BA_ "GenSigStartValue" SG_ 696 PedObjID 255;
BA_ "Match" SG_ 696 PedObjID "PedObjID";
BA_ "Origin" SG_ 696 PedObjID "fuel,ev";
BA_ "GenSigCycleTime" SG_ 696 PedObjObstcl 100;
BA_ "Match" SG_ 696 PedObjObstcl "PedObjObstcl";
BA_ "Origin" SG_ 696 PedObjObstcl "fuel,ev";
BA_ "GenSigCycleTime" SG_ 696 PedObjDy 100;
BA_ "Match" SG_ 696 PedObjDy "PedObjDy";
BA_ "Origin" SG_ 696 PedObjDy "fuel,ev";
BA_ "GenSigCycleTime" SG_ 696 PedObjDx 100;
BA_ "Match" SG_ 696 PedObjDx "PedObjDx";
BA_ "Origin" SG_ 696 PedObjDx "fuel,ev";
BA_ "GenSigCycleTime" SG_ 696 PedObjVx 100;
BA_ "Match" SG_ 696 PedObjVx "PedObjVx";
BA_ "Origin" SG_ 696 PedObjVx "fuel,ev";
BA_ "GenSigCycleTime" SG_ 696 PedObjVy 100;
BA_ "Match" SG_ 696 PedObjVy "PedObjVy";
BA_ "Origin" SG_ 696 PedObjVy "fuel,ev";
BA_ "GenSigCycleTime" SG_ 696 PedObjVideoCfmd 100;
BA_ "Match" SG_ 696 PedObjVideoCfmd "PedObjVideoCfmd";
BA_ "Origin" SG_ 696 PedObjVideoCfmd "fuel,ev";
BA_ "GenSigCycleTime" SG_ 696 ACCTgtObjDx 100;
BA_ "Match" SG_ 696 ACCTgtObjDx "ACCTgtObjDx";
BA_ "Origin" SG_ 696 ACCTgtObjDx "fuel,ev";
BA_ "GenSigCycleTime" SG_ 696 PedObjAy 100;
BA_ "Match" SG_ 696 PedObjAy "PedObjAy";
BA_ "Origin" SG_ 696 PedObjAy "fuel,ev";
BA_ "GenSigCycleTime" SG_ 696 PedObjCntAlive 100;
BA_ "Match" SG_ 696 PedObjCntAlive "PedObjCntAlive";
BA_ "Origin" SG_ 696 PedObjCntAlive "fuel,ev";
BA_ "GenSigCycleTime" SG_ 696 PedObjAx 100;
BA_ "Match" SG_ 696 PedObjAx "PedObjAx";
BA_ "Origin" SG_ 696 PedObjAx "fuel,ev";
BA_ "GenSigCycleTime" SG_ 696 ACCTgtObjID 100;
BA_ "GenSigStartValue" SG_ 696 ACCTgtObjID 255;
BA_ "Match" SG_ 696 ACCTgtObjID "ACCTgtObjID";
BA_ "Origin" SG_ 696 ACCTgtObjID "fuel,ev";
BA_ "GenSigCycleTime" SG_ 696 ACCTgtObjObstcl 100;
BA_ "Match" SG_ 696 ACCTgtObjObstcl "ACCTgtObjObstcl";
BA_ "Origin" SG_ 696 ACCTgtObjObstcl "fuel,ev";
BA_ "GenSigCycleTime" SG_ 696 ACCTgtObjDy 100;
BA_ "Match" SG_ 696 ACCTgtObjDy "ACCTgtObjDy";
BA_ "Origin" SG_ 696 ACCTgtObjDy "fuel,ev";
BA_ "GenSigCycleTime" SG_ 696 ACCTgtObjExist 100;
BA_ "Match" SG_ 696 ACCTgtObjExist "ACCTgtObjExist";
BA_ "Origin" SG_ 696 ACCTgtObjExist "fuel,ev";
BA_ "GenSigCycleTime" SG_ 696 ACCTgtObjVy 100;
BA_ "Match" SG_ 696 ACCTgtObjVy "ACCTgtObjVy";
BA_ "Origin" SG_ 696 ACCTgtObjVy "fuel,ev";
BA_ "GenSigCycleTime" SG_ 696 ACCTgtObjVx 100;
BA_ "Match" SG_ 696 ACCTgtObjVx "ACCTgtObjVx";
BA_ "Origin" SG_ 696 ACCTgtObjVx "fuel,ev";
BA_ "GenSigCycleTime" SG_ 696 ACCTgtObjAx 100;
BA_ "Match" SG_ 696 ACCTgtObjAx "ACCTgtObjAx";
BA_ "Origin" SG_ 696 ACCTgtObjAx "fuel,ev";
BA_ "GenSigCycleTime" SG_ 696 ACCTgtObjAy 100;
BA_ "Match" SG_ 696 ACCTgtObjAy "ACCTgtObjAy";
BA_ "Origin" SG_ 696 ACCTgtObjAy "fuel,ev";
BA_ "GenSigCycleTime" SG_ 696 ACCTgtObjState 100;
BA_ "Match" SG_ 696 ACCTgtObjState "ACCTgtObjState";
BA_ "Origin" SG_ 696 ACCTgtObjState "fuel,ev";
BA_ "GenSigCycleTime" SG_ 696 ACCTgtObjVideoCfmd 100;
BA_ "Match" SG_ 696 ACCTgtObjVideoCfmd "ACCTgtObjVideoCfmd";
BA_ "Origin" SG_ 696 ACCTgtObjVideoCfmd "fuel,ev";
BA_ "GenSigCycleTime" SG_ 696 ACCTgtObjCntAlive 100;
BA_ "Match" SG_ 696 ACCTgtObjCntAlive "ACCTgtObjCntAlive";
BA_ "Origin" SG_ 696 ACCTgtObjCntAlive "fuel,ev";
BA_ "GenSigCycleTime" SG_ 696 RadarHorMisalign 100;
BA_ "Match" SG_ 696 RadarHorMisalign "RadarHorMisalign";
BA_ "Origin" SG_ 696 RadarHorMisalign "fuel,ev";
BA_ "GenSigCycleTime" SG_ 696 HandsoffDetd 100;
BA_ "Match" SG_ 696 HandsoffDetd "HandsoffDetd";
BA_ "Origin" SG_ 696 HandsoffDetd "fuel,ev";
BA_ "GenSigCycleTime" SG_ 696 DrvgOnHiWay 100;
BA_ "Match" SG_ 696 DrvgOnHiWay "DrvgOnHiWay";
BA_ "Origin" SG_ 696 DrvgOnHiWay "fuel,ev";
BA_ "GenSigCycleTime" SG_ 696 RoadCrvt 100;
BA_ "GenSigStartValue" SG_ 696 RoadCrvt 511;
BA_ "Match" SG_ 696 RoadCrvt "RoadCrvt";
BA_ "Origin" SG_ 696 RoadCrvt "fuel,ev";
BA_ "GenSigCycleTime" SG_ 696 SpdLimitDst 100;
BA_ "GenSigStartValue" SG_ 696 SpdLimitDst 63;
BA_ "Match" SG_ 696 SpdLimitDst "SpdLimitDst";
BA_ "Origin" SG_ 696 SpdLimitDst "fuel,ev";
BA_ "GenSigCycleTime" SG_ 696 RoadCrvtFar 100;
BA_ "GenSigStartValue" SG_ 696 RoadCrvtFar 511;
BA_ "Match" SG_ 696 RoadCrvtFar "RoadCrvtFar";
BA_ "Origin" SG_ 696 RoadCrvtFar "fuel,ev";
BA_ "GenSigCycleTime" SG_ 696 RampDst 100;
BA_ "GenSigStartValue" SG_ 696 RampDst 63;
BA_ "Match" SG_ 696 RampDst "RampDst";
BA_ "Origin" SG_ 696 RampDst "fuel,ev";
BA_ "GenSigCycleTime" SG_ 696 SpdLimit 100;
BA_ "GenSigStartValue" SG_ 696 SpdLimit 254;
BA_ "Match" SG_ 696 SpdLimit "SpdLimit";
BA_ "Origin" SG_ 696 SpdLimit "fuel,ev";
BA_ "GenSigCycleTime" SG_ 696 CurveDst 100;
BA_ "GenSigStartValue" SG_ 696 CurveDst 63;
BA_ "Match" SG_ 696 CurveDst "CurveDst";
BA_ "Origin" SG_ 696 CurveDst "fuel,ev";
BA_ "GenSigCycleTime" SG_ 696 NavSpdLimUnit 100;
BA_ "Match" SG_ 696 NavSpdLimUnit "NavSpdLimUnit";
BA_ "Origin" SG_ 696 NavSpdLimUnit "fuel,ev";
BA_ "GenSigCycleTime" SG_ 696 TunnelDst 100;
BA_ "GenSigStartValue" SG_ 696 TunnelDst 63;
BA_ "Match" SG_ 696 TunnelDst "TunnelDst";
BA_ "Origin" SG_ 696 TunnelDst "fuel,ev";
BA_ "GenSigCycleTime" SG_ 696 DrvgOnRiLane 100;
BA_ "Match" SG_ 696 DrvgOnRiLane "DrvgOnRiLane";
BA_ "Origin" SG_ 696 DrvgOnRiLane "fuel,ev";
BA_ "GenSigCycleTime" SG_ 696 BrdgDst 100;
BA_ "GenSigStartValue" SG_ 696 BrdgDst 63;
BA_ "Match" SG_ 696 BrdgDst "BrdgDst";
BA_ "Origin" SG_ 696 BrdgDst "fuel,ev";
BA_ "GenSigCycleTime" SG_ 696 RadarDrvrAttentive 100;
BA_ "Match" SG_ 696 RadarDrvrAttentive "RadarDrvrAttentive";
BA_ "Origin" SG_ 696 RadarDrvrAttentive "fuel,ev";
BA_ "GenSigCycleTime" SG_ 696 ACC_DataRecReq 100;
BA_ "Match" SG_ 696 ACC_DataRecReq "ACC_DataRecReq";
BA_ "Origin" SG_ 696 ACC_DataRecReq "fuel,ev";
BA_ "GenSigCycleTime" SG_ 696 ACC_SOSReq 100;
BA_ "Match" SG_ 696 ACC_SOSReq "ACC_SOSReq";
BA_ "Origin" SG_ 696 ACC_SOSReq "fuel,ev";
BA_ "GenSigCycleTime" SG_ 696 PedObjState 100;
BA_ "Match" SG_ 696 PedObjState "PedObjState";
BA_ "Origin" SG_ 696 PedObjState "fuel,ev";
BA_ "GenSigCycleTime" SG_ 696 MapDataValid 100;
BA_ "Match" SG_ 696 MapDataValid "MapDataValid";
BA_ "Origin" SG_ 696 MapDataValid "fuel,ev";
BA_ "GenSigCycleTime" SG_ 696 DrvrSts 100;
BA_ "Match" SG_ 696 DrvrSts "DrvrSts";
BA_ "Origin" SG_ 696 DrvrSts "fuel,ev";
BA_ "GenSigCycleTime" SG_ 696 AEBObjOverlap 100;
BA_ "Match" SG_ 696 AEBObjOverlap "AEBObjOverlap";
BA_ "Origin" SG_ 696 AEBObjOverlap "fuel,ev";
BA_ "GenSigCycleTime" SG_ 696 AEBObjDrvby 100;
BA_ "Match" SG_ 696 AEBObjDrvby "AEBObjDrvby";
BA_ "Origin" SG_ 696 AEBObjDrvby "fuel,ev";
BA_ "GenSigCycleTime" SG_ 395 AEB_ABA_Level 20;
BA_ "Match" SG_ 395 AEB_ABA_Level "AEB_ABA_Level";
BA_ "Origin" SG_ 395 AEB_ABA_Level "fuel,ev";
BA_ "GenSigCycleTime" SG_ 395 AEB_ABA_Req 20;
BA_ "Match" SG_ 395 AEB_ABA_Req "AEB_ABA_Req";
BA_ "Origin" SG_ 395 AEB_ABA_Req "fuel,ev";
BA_ "GenSigCycleTime" SG_ 395 EBA_TgtDecel_Req 20;
BA_ "Match" SG_ 395 EBA_TgtDecel_Req "EBA_TgtDecel_Req";
BA_ "Origin" SG_ 395 EBA_TgtDecel_Req "fuel,ev";
BA_ "GenSigCycleTime" SG_ 395 AEB_VehHldReq 20;
BA_ "Match" SG_ 395 AEB_VehHldReq "AEB_VehHldReq";
BA_ "Origin" SG_ 395 AEB_VehHldReq "fuel,ev";
BA_ "GenSigCycleTime" SG_ 395 AEB_TgtDecel_Req 20;
BA_ "Match" SG_ 395 AEB_TgtDecel_Req "AEB_TgtDecel_Req";
BA_ "Origin" SG_ 395 AEB_TgtDecel_Req "fuel,ev";
BA_ "GenSigCycleTime" SG_ 395 AEB_TgtDecel_ReqValue 20;
BA_ "Match" SG_ 395 AEB_TgtDecel_ReqValue "AEB_TgtDecel_ReqValue";
BA_ "Origin" SG_ 395 AEB_TgtDecel_ReqValue "fuel,ev";
BA_ "GenSigCycleTime" SG_ 395 AEB_AWB_Req 20;
BA_ "Match" SG_ 395 AEB_AWB_Req "AEB_AWB_Req";
BA_ "Origin" SG_ 395 AEB_AWB_Req "fuel,ev";
BA_ "GenSigCycleTime" SG_ 395 AEB_AWB_Level 20;
BA_ "Match" SG_ 395 AEB_AWB_Level "AEB_AWB_Level";
BA_ "Origin" SG_ 395 AEB_AWB_Level "fuel,ev";
BA_ "GenSigCycleTime" SG_ 395 AEB_ABP_Req 20;
BA_ "Match" SG_ 395 AEB_ABP_Req "AEB_ABP_Req";
BA_ "Origin" SG_ 395 AEB_ABP_Req "fuel,ev";
BA_ "GenSigCycleTime" SG_ 395 AEB_BrkReqFunc 20;
BA_ "Match" SG_ 395 AEB_BrkReqFunc "AEB_BrkReqFunc";
BA_ "Origin" SG_ 395 AEB_BrkReqFunc "fuel,ev";
BA_ "GenSigCycleTime" SG_ 395 AEB_ObjSty 20;
BA_ "Match" SG_ 395 AEB_ObjSty "AEB_ObjSty";
BA_ "Origin" SG_ 395 AEB_ObjSty "fuel,ev";
BA_ "GenSigCycleTime" SG_ 551 Checksum_AEB2 50;
BA_ "Match" SG_ 551 Checksum_AEB2 "Checksum_AEB2";
BA_ "Origin" SG_ 551 Checksum_AEB2 "fuel,ev";
BA_ "GenSigCycleTime" SG_ 551 AEB_PedResp 50;
BA_ "GenSigStartValue" SG_ 551 AEB_PedResp 1;
BA_ "Match" SG_ 551 AEB_PedResp "AEB_PedResp";
BA_ "Origin" SG_ 551 AEB_PedResp "fuel,ev";
BA_ "GenSigCycleTime" SG_ 551 AEB_VehResp 50;
BA_ "GenSigStartValue" SG_ 551 AEB_VehResp 1;
BA_ "Match" SG_ 551 AEB_VehResp "AEB_VehResp";
BA_ "Origin" SG_ 551 AEB_VehResp "fuel,ev";
BA_ "GenSigCycleTime" SG_ 551 FCW_Snvty 50;
BA_ "Match" SG_ 551 FCW_Snvty "FCW_Snvty";
BA_ "Origin" SG_ 551 FCW_Snvty "fuel,ev";
BA_ "GenSigCycleTime" SG_ 551 AEB_JA_Resp 50;
BA_ "GenSigStartValue" SG_ 551 AEB_JA_Resp 1;
BA_ "Match" SG_ 551 AEB_JA_Resp "AEB_JA_Resp";
BA_ "Origin" SG_ 551 AEB_JA_Resp "fuel,ev";
BA_ "GenSigCycleTime" SG_ 551 RollingCounter_AEB2 50;
BA_ "Match" SG_ 551 RollingCounter_AEB2 "RollingCounter_AEB2";
BA_ "Origin" SG_ 551 RollingCounter_AEB2 "fuel,ev";
BA_ "GenSigCycleTime" SG_ 551 Checksum_AEB3 50;
BA_ "Match" SG_ 551 Checksum_AEB3 "Checksum_AEB3";
BA_ "Origin" SG_ 551 Checksum_AEB3 "fuel,ev";
BA_ "GenSigCycleTime" SG_ 551 AEB_VehTrig 50;
BA_ "Match" SG_ 551 AEB_VehTrig "AEB_VehTrig";
BA_ "Origin" SG_ 551 AEB_VehTrig "fuel,ev";
BA_ "GenSigCycleTime" SG_ 551 AEB_PedTrig 50;
BA_ "Match" SG_ 551 AEB_PedTrig "AEB_PedTrig";
BA_ "Origin" SG_ 551 AEB_PedTrig "fuel,ev";
BA_ "GenSigCycleTime" SG_ 551 FCW_AEB_VehFctSts 50;
BA_ "Match" SG_ 551 FCW_AEB_VehFctSts "FCW_AEB_VehFctSts";
BA_ "Origin" SG_ 551 FCW_AEB_VehFctSts "fuel,ev";
BA_ "GenSigCycleTime" SG_ 551 FCW_AEB_PedFctSts 50;
BA_ "Match" SG_ 551 FCW_AEB_PedFctSts "FCW_AEB_PedFctSts";
BA_ "Origin" SG_ 551 FCW_AEB_PedFctSts "fuel,ev";
BA_ "GenSigCycleTime" SG_ 551 FCW_Warn 50;
BA_ "Match" SG_ 551 FCW_Warn "FCW_Warn";
BA_ "Origin" SG_ 551 FCW_Warn "fuel,ev";
BA_ "GenSigCycleTime" SG_ 551 AEB_JAFuncSts 50;
BA_ "Match" SG_ 551 AEB_JAFuncSts "AEB_JAFuncSts";
BA_ "Origin" SG_ 551 AEB_JAFuncSts "fuel,ev";
BA_ "GenSigCycleTime" SG_ 551 AEB_JA_Warn 50;
BA_ "Match" SG_ 551 AEB_JA_Warn "AEB_JA_Warn";
BA_ "Origin" SG_ 551 AEB_JA_Warn "fuel,ev";
BA_ "GenSigCycleTime" SG_ 551 AEB_JABrkTrig 50;
BA_ "Match" SG_ 551 AEB_JABrkTrig "AEB_JABrkTrig";
BA_ "Origin" SG_ 551 AEB_JABrkTrig "fuel,ev";
BA_ "GenSigCycleTime" SG_ 551 RollingCounter_AEB3 50;
BA_ "Match" SG_ 551 RollingCounter_AEB3 "RollingCounter_AEB3";
BA_ "Origin" SG_ 551 RollingCounter_AEB3 "fuel,ev";
BA_ "GenSigCycleTime" SG_ 551 ACC_PotentialTgt_02_Dy 50;
BA_ "Match" SG_ 551 ACC_PotentialTgt_02_Dy "ACC_PotentialTgt_02_Dy";
BA_ "Origin" SG_ 551 ACC_PotentialTgt_02_Dy "fuel,ev";
BA_ "GenSigCycleTime" SG_ 551 ACC_PotentialTgt_02_Dx 50;
BA_ "Match" SG_ 551 ACC_PotentialTgt_02_Dx "ACC_PotentialTgt_02_Dx";
BA_ "Origin" SG_ 551 ACC_PotentialTgt_02_Dx "fuel,ev";
BA_ "GenSigCycleTime" SG_ 551 ACC_PotentialTgt_02_Detn 50;
BA_ "Match" SG_ 551 ACC_PotentialTgt_02_Detn "ACC_PotentialTgt_02_Detn";
BA_ "Origin" SG_ 551 ACC_PotentialTgt_02_Detn "fuel,ev";
BA_ "GenSigCycleTime" SG_ 551 ACC_PotentialTgt_02_Typ 50;
BA_ "Match" SG_ 551 ACC_PotentialTgt_02_Typ "ACC_PotentialTgt_02_Typ";
BA_ "Origin" SG_ 551 ACC_PotentialTgt_02_Typ "fuel,ev";
BA_ "GenSigCycleTime" SG_ 551 ACC_PotentialTgt_02_fusion 50;
BA_ "Match" SG_ 551 ACC_PotentialTgt_02_fusion "ACC_PotentialTgt_02_fusion";
BA_ "Origin" SG_ 551 ACC_PotentialTgt_02_fusion "fuel,ev";
BA_ "GenSigCycleTime" SG_ 551 ACC_PotentialTgt_02_Heading 50;
BA_ "GenSigStartValue" SG_ 551 ACC_PotentialTgt_02_Heading 30;
BA_ "Match" SG_ 551 ACC_PotentialTgt_02_Heading "ACC_PotentialTgt_02_Heading";
BA_ "Origin" SG_ 551 ACC_PotentialTgt_02_Heading "fuel,ev";
BA_ "GenSigCycleTime" SG_ 551 ACC_LeTgt_03_Dy 50;
BA_ "Match" SG_ 551 ACC_LeTgt_03_Dy "ACC_LeTgt_03_Dy";
BA_ "Origin" SG_ 551 ACC_LeTgt_03_Dy "fuel,ev";
BA_ "GenSigCycleTime" SG_ 551 ACC_LeTgt_03_Dx 50;
BA_ "Match" SG_ 551 ACC_LeTgt_03_Dx "ACC_LeTgt_03_Dx";
BA_ "Origin" SG_ 551 ACC_LeTgt_03_Dx "fuel,ev";
BA_ "GenSigCycleTime" SG_ 551 ACC_LeTargrt_03_Detn 50;
BA_ "Match" SG_ 551 ACC_LeTargrt_03_Detn "ACC_LeTargrt_03_Detn";
BA_ "Origin" SG_ 551 ACC_LeTargrt_03_Detn "fuel,ev";
BA_ "GenSigCycleTime" SG_ 551 ACC_LeTgt_03_Typ 50;
BA_ "Match" SG_ 551 ACC_LeTgt_03_Typ "ACC_LeTgt_03_Typ";
BA_ "Origin" SG_ 551 ACC_LeTgt_03_Typ "fuel,ev";
BA_ "GenSigCycleTime" SG_ 551 ACC_LeTgt_03_fusion 50;
BA_ "Match" SG_ 551 ACC_LeTgt_03_fusion "ACC_LeTgt_03_fusion";
BA_ "Origin" SG_ 551 ACC_LeTgt_03_fusion "fuel,ev";
BA_ "GenSigCycleTime" SG_ 551 ACC_LeTgt_03_Heading 50;
BA_ "GenSigStartValue" SG_ 551 ACC_LeTgt_03_Heading 30;
BA_ "Match" SG_ 551 ACC_LeTgt_03_Heading "ACC_LeTgt_03_Heading";
BA_ "Origin" SG_ 551 ACC_LeTgt_03_Heading "fuel,ev";
BA_ "GenSigCycleTime" SG_ 551 ACC_RiTgt_03_Dy 50;
BA_ "Match" SG_ 551 ACC_RiTgt_03_Dy "ACC_RiTgt_03_Dy";
BA_ "Origin" SG_ 551 ACC_RiTgt_03_Dy "fuel,ev";
BA_ "GenSigCycleTime" SG_ 551 ACC_RiTgt_03_Dx 50;
BA_ "Match" SG_ 551 ACC_RiTgt_03_Dx "ACC_RiTgt_03_Dx";
BA_ "Origin" SG_ 551 ACC_RiTgt_03_Dx "fuel,ev";
BA_ "GenSigCycleTime" SG_ 551 ACC_RiTargrt_03_Detn 50;
BA_ "Match" SG_ 551 ACC_RiTargrt_03_Detn "ACC_RiTargrt_03_Detn";
BA_ "Origin" SG_ 551 ACC_RiTargrt_03_Detn "fuel,ev";
BA_ "GenSigCycleTime" SG_ 551 ACC_RiTgt_03_Typ 50;
BA_ "Match" SG_ 551 ACC_RiTgt_03_Typ "ACC_RiTgt_03_Typ";
BA_ "Origin" SG_ 551 ACC_RiTgt_03_Typ "fuel,ev";
BA_ "GenSigCycleTime" SG_ 551 ACC_RiTgt_03_fusion 50;
BA_ "Match" SG_ 551 ACC_RiTgt_03_fusion "ACC_RiTgt_03_fusion";
BA_ "Origin" SG_ 551 ACC_RiTgt_03_fusion "fuel,ev";
BA_ "GenSigCycleTime" SG_ 551 ACC_RiTgt_03_Heading 50;
BA_ "GenSigStartValue" SG_ 551 ACC_RiTgt_03_Heading 30;
BA_ "Match" SG_ 551 ACC_RiTgt_03_Heading "ACC_RiTgt_03_Heading";
BA_ "Origin" SG_ 551 ACC_RiTgt_03_Heading "fuel,ev";
BA_ "GenSigCycleTime" SG_ 551 FreshnessValue_AEB_FD2 50;
BA_ "Match" SG_ 551 FreshnessValue_AEB_FD2 "FreshnessValue_AEB_FD2";
BA_ "Origin" SG_ 551 FreshnessValue_AEB_FD2 "fuel,ev";
BA_ "GenSigCycleTime" SG_ 551 MAC_Check_AEB_FD2 50;
BA_ "Match" SG_ 551 MAC_Check_AEB_FD2 "MAC_Check_AEB_FD2";
BA_ "Origin" SG_ 551 MAC_Check_AEB_FD2 "fuel,ev";
BA_ "GenSigSendType" SG_ 993 AMP_SWVersion 2;
BA_ "Match" SG_ 993 AMP_SWVersion "AMP_SWVersion";
BA_ "Origin" SG_ 993 AMP_SWVersion "fuel,ev";
BA_ "GenSigSendType" SG_ 993 AMP_HWVersion 2;
BA_ "Match" SG_ 993 AMP_HWVersion "AMP_HWVersion";
BA_ "Origin" SG_ 993 AMP_HWVersion "fuel,ev";
BA_ "GenSigSendType" SG_ 993 AMP_Chan1DTCInfo 2;
BA_ "Match" SG_ 993 AMP_Chan1DTCInfo "AMP_Chan1DTCInfo";
BA_ "Origin" SG_ 993 AMP_Chan1DTCInfo "fuel,ev";
BA_ "GenSigSendType" SG_ 993 AMP_Chan2DTCInfo 2;
BA_ "Match" SG_ 993 AMP_Chan2DTCInfo "AMP_Chan2DTCInfo";
BA_ "Origin" SG_ 993 AMP_Chan2DTCInfo "fuel,ev";
BA_ "GenSigSendType" SG_ 993 AMP_Chan3DTCInfo 2;
BA_ "Match" SG_ 993 AMP_Chan3DTCInfo "AMP_Chan3DTCInfo";
BA_ "Origin" SG_ 993 AMP_Chan3DTCInfo "fuel,ev";
BA_ "GenSigSendType" SG_ 993 AMP_Chan4DTCInfo 2;
BA_ "Match" SG_ 993 AMP_Chan4DTCInfo "AMP_Chan4DTCInfo";
BA_ "Origin" SG_ 993 AMP_Chan4DTCInfo "fuel,ev";
BA_ "GenSigSendType" SG_ 993 AMP_Chan5DTCInfo 2;
BA_ "Match" SG_ 993 AMP_Chan5DTCInfo "AMP_Chan5DTCInfo";
BA_ "Origin" SG_ 993 AMP_Chan5DTCInfo "fuel,ev";
BA_ "GenSigSendType" SG_ 993 AMP_Chan6DTCInfo 2;
BA_ "Match" SG_ 993 AMP_Chan6DTCInfo "AMP_Chan6DTCInfo";
BA_ "Origin" SG_ 993 AMP_Chan6DTCInfo "fuel,ev";
BA_ "GenSigSendType" SG_ 993 AMP_Chan7DTCInfo 2;
BA_ "Match" SG_ 993 AMP_Chan7DTCInfo "AMP_Chan7DTCInfo";
BA_ "Origin" SG_ 993 AMP_Chan7DTCInfo "fuel,ev";
BA_ "GenSigSendType" SG_ 993 AMP_Chan8DTCInfo 2;
BA_ "Match" SG_ 993 AMP_Chan8DTCInfo "AMP_Chan8DTCInfo";
BA_ "Origin" SG_ 993 AMP_Chan8DTCInfo "fuel,ev";
BA_ "GenSigSendType" SG_ 993 AMP_TempValue 2;
BA_ "Match" SG_ 993 AMP_TempValue "AMP_TempValue";
BA_ "Origin" SG_ 993 AMP_TempValue "fuel,ev";
BA_ "GenSigSendType" SG_ 993 AMP_TempSts 2;
BA_ "Match" SG_ 993 AMP_TempSts "AMP_TempSts";
BA_ "Origin" SG_ 993 AMP_TempSts "fuel,ev";
BA_ "GenSigSendType" SG_ 993 AMP_VolValue 2;
BA_ "Match" SG_ 993 AMP_VolValue "AMP_VolValue";
BA_ "Origin" SG_ 993 AMP_VolValue "fuel,ev";
BA_ "GenSigSendType" SG_ 993 BestListegPosnResp 2;
BA_ "Match" SG_ 993 BestListegPosnResp "BestListegPosnResp";
BA_ "Origin" SG_ 993 BestListegPosnResp "fuel,ev";
BA_ "GenSigSendType" SG_ 993 Clari_FiResp 2;
BA_ "GenSigStartValue" SG_ 993 Clari_FiResp 1;
BA_ "Match" SG_ 993 Clari_FiResp "Clari_FiResp";
BA_ "Origin" SG_ 993 Clari_FiResp "fuel,ev";
BA_ "GenSigSendType" SG_ 995 MediaCallSourceState 2;
BA_ "Match" SG_ 995 MediaCallSourceState "MediaCallSourceState";
BA_ "Origin" SG_ 995 MediaCallSourceState "fuel,ev";
BA_ "GenSigSendType" SG_ 995 BeepSourceSts 2;
BA_ "Match" SG_ 995 BeepSourceSts "BeepSourceSts";
BA_ "Origin" SG_ 995 BeepSourceSts "fuel,ev";
BA_ "GenSigSendType" SG_ 995 BalanceSetState 2;
BA_ "GenSigStartValue" SG_ 995 BalanceSetState 10;
BA_ "Match" SG_ 995 BalanceSetState "BalanceSetState";
BA_ "Origin" SG_ 995 BalanceSetState "fuel,ev";
BA_ "GenSigSendType" SG_ 995 VSCModeState 2;
BA_ "GenSigStartValue" SG_ 995 VSCModeState 2;
BA_ "Match" SG_ 995 VSCModeState "VSCModeState";
BA_ "Origin" SG_ 995 VSCModeState "fuel,ev";
BA_ "GenSigSendType" SG_ 995 FadeSetState 2;
BA_ "GenSigStartValue" SG_ 995 FadeSetState 10;
BA_ "Match" SG_ 995 FadeSetState "FadeSetState";
BA_ "Origin" SG_ 995 FadeSetState "fuel,ev";
BA_ "GenSigSendType" SG_ 995 DriveSideSts 2;
BA_ "Match" SG_ 995 DriveSideSts "DriveSideSts";
BA_ "Origin" SG_ 995 DriveSideSts "fuel,ev";
BA_ "GenSigSendType" SG_ 995 BassSetState 2;
BA_ "GenSigStartValue" SG_ 995 BassSetState 10;
BA_ "Match" SG_ 995 BassSetState "BassSetState";
BA_ "Origin" SG_ 995 BassSetState "fuel,ev";
BA_ "GenSigSendType" SG_ 995 MuteState 2;
BA_ "GenSigStartValue" SG_ 995 MuteState 1;
BA_ "Match" SG_ 995 MuteState "MuteState";
BA_ "Origin" SG_ 995 MuteState "fuel,ev";
BA_ "GenSigSendType" SG_ 995 NaviSourceState 2;
BA_ "Match" SG_ 995 NaviSourceState "NaviSourceState";
BA_ "Origin" SG_ 995 NaviSourceState "fuel,ev";
BA_ "GenSigSendType" SG_ 995 MidrangeSetState 2;
BA_ "GenSigStartValue" SG_ 995 MidrangeSetState 10;
BA_ "Match" SG_ 995 MidrangeSetState "MidrangeSetState";
BA_ "Origin" SG_ 995 MidrangeSetState "fuel,ev";
BA_ "GenSigSendType" SG_ 995 T_box_ECallSts 2;
BA_ "Match" SG_ 995 T_box_ECallSts "T_box_ECallSts";
BA_ "Origin" SG_ 995 T_box_ECallSts "fuel,ev";
BA_ "GenSigSendType" SG_ 995 GetHUTInfoSts 2;
BA_ "GenSigStartValue" SG_ 995 GetHUTInfoSts 1;
BA_ "Match" SG_ 995 GetHUTInfoSts "GetHUTInfoSts";
BA_ "Origin" SG_ 995 GetHUTInfoSts "fuel,ev";
BA_ "GenSigSendType" SG_ 995 TrebleSetState 2;
BA_ "GenSigStartValue" SG_ 995 TrebleSetState 10;
BA_ "Match" SG_ 995 TrebleSetState "TrebleSetState";
BA_ "Origin" SG_ 995 TrebleSetState "fuel,ev";
BA_ "GenSigSendType" SG_ 995 QLISurroundSetSt 2;
BA_ "GenSigStartValue" SG_ 995 QLISurroundSetSt 1;
BA_ "Match" SG_ 995 QLISurroundSetSt "QLISurroundSetSt";
BA_ "Origin" SG_ 995 QLISurroundSetSt "fuel,ev";
BA_ "GenSigSendType" SG_ 995 AVMStResp 2;
BA_ "Match" SG_ 995 AVMStResp "AVMStResp";
BA_ "Origin" SG_ 995 AVMStResp "fuel,ev";
BA_ "GenSigSendType" SG_ 995 NaviMediaVolLvlResp 2;
BA_ "GenSigStartValue" SG_ 995 NaviMediaVolLvlResp 3;
BA_ "Match" SG_ 995 NaviMediaVolLvlResp "NaviMediaVolLvlResp";
BA_ "Origin" SG_ 995 NaviMediaVolLvlResp "fuel,ev";
BA_ "GenSigSendType" SG_ 995 AVMMediaVolLvlResp 2;
BA_ "GenSigStartValue" SG_ 995 AVMMediaVolLvlResp 3;
BA_ "Match" SG_ 995 AVMMediaVolLvlResp "AVMMediaVolLvlResp";
BA_ "Origin" SG_ 995 AVMMediaVolLvlResp "fuel,ev";
BA_ "GenSigSendType" SG_ 995 FPASChStResp 2;
BA_ "Match" SG_ 995 FPASChStResp "FPASChStResp";
BA_ "Origin" SG_ 995 FPASChStResp "fuel,ev";
BA_ "GenSigSendType" SG_ 995 RPASChStResp 2;
BA_ "Match" SG_ 995 RPASChStResp "RPASChStResp";
BA_ "Origin" SG_ 995 RPASChStResp "fuel,ev";
BA_ "GenSigSendType" SG_ 995 FreshnessValue_AMP2 2;
BA_ "Match" SG_ 995 FreshnessValue_AMP2 "FreshnessValue_AMP2";
BA_ "Origin" SG_ 995 FreshnessValue_AMP2 "fuel,ev";
BA_ "GenSigSendType" SG_ 995 MAC_Check_AMP2 2;
BA_ "Match" SG_ 995 MAC_Check_AMP2 "MAC_Check_AMP2";
BA_ "Origin" SG_ 995 MAC_Check_AMP2 "fuel,ev";
BA_ "GenSigSendType" SG_ 997 HFMVolSetSts 2;
BA_ "GenSigStartValue" SG_ 997 HFMVolSetSts 10;
BA_ "Match" SG_ 997 HFMVolSetSts "HFMVolSetSts";
BA_ "Origin" SG_ 997 HFMVolSetSts "fuel,ev";
BA_ "GenSigSendType" SG_ 997 VR_TTSVolSetSts 2;
BA_ "GenSigStartValue" SG_ 997 VR_TTSVolSetSts 10;
BA_ "Match" SG_ 997 VR_TTSVolSetSts "VR_TTSVolSetSts";
BA_ "Origin" SG_ 997 VR_TTSVolSetSts "fuel,ev";
BA_ "GenSigSendType" SG_ 997 NaviVolumeSetState 2;
BA_ "GenSigStartValue" SG_ 997 NaviVolumeSetState 10;
BA_ "Match" SG_ 997 NaviVolumeSetState "NaviVolumeSetState";
BA_ "Origin" SG_ 997 NaviVolumeSetState "fuel,ev";
BA_ "GenSigSendType" SG_ 997 MainVolumeSetState 2;
BA_ "GenSigStartValue" SG_ 997 MainVolumeSetState 10;
BA_ "Match" SG_ 997 MainVolumeSetState "MainVolumeSetState";
BA_ "Origin" SG_ 997 MainVolumeSetState "fuel,ev";
BA_ "GenSigSendType" SG_ 997 AMPPowerSts 2;
BA_ "GenSigStartValue" SG_ 997 AMPPowerSts 1;
BA_ "Match" SG_ 997 AMPPowerSts "AMPPowerSts";
BA_ "Origin" SG_ 997 AMPPowerSts "fuel,ev";
BA_ "GenSigSendType" SG_ 997 IPVolSetSts 2;
BA_ "GenSigStartValue" SG_ 997 IPVolSetSts 15;
BA_ "Match" SG_ 997 IPVolSetSts "IPVolSetSts";
BA_ "Origin" SG_ 997 IPVolSetSts "fuel,ev";
BA_ "GenSigSendType" SG_ 722 Microphone_Cha1DTCInfo 2;
BA_ "Match" SG_ 722 Microphone_Cha1DTCInfo "Microphone_Cha1DTCInfo";
BA_ "Origin" SG_ 722 Microphone_Cha1DTCInfo "fuel,ev";
BA_ "GenSigSendType" SG_ 722 Microphone_Cha2DTCInfo 2;
BA_ "Match" SG_ 722 Microphone_Cha2DTCInfo "Microphone_Cha2DTCInfo";
BA_ "Origin" SG_ 722 Microphone_Cha2DTCInfo "fuel,ev";
BA_ "GenSigSendType" SG_ 722 Microphone_Cha3DTCInfo 2;
BA_ "Match" SG_ 722 Microphone_Cha3DTCInfo "Microphone_Cha3DTCInfo";
BA_ "Origin" SG_ 722 Microphone_Cha3DTCInfo "fuel,ev";
BA_ "GenSigSendType" SG_ 722 Microphone_Cha4DTCInfo 2;
BA_ "Match" SG_ 722 Microphone_Cha4DTCInfo "Microphone_Cha4DTCInfo";
BA_ "Origin" SG_ 722 Microphone_Cha4DTCInfo "fuel,ev";
BA_ "GenSigSendType" SG_ 722 ANCSwtStatus 2;
BA_ "GenSigStartValue" SG_ 722 ANCSwtStatus 1;
BA_ "Match" SG_ 722 ANCSwtStatus "ANCSwtStatus";
BA_ "Origin" SG_ 722 ANCSwtStatus "fuel,ev";
BA_ "GenSigCycleTime" SG_ 793 IPBackgroundLmpCmd 50;
BA_ "Match" SG_ 793 IPBackgroundLmpCmd "IPBackgroundLmpCmd";
BA_ "Origin" SG_ 793 IPBackgroundLmpCmd "fuel,ev";
BA_ "GenSigCycleTime" SG_ 793 TrunkSts 50;
BA_ "Match" SG_ 793 TrunkSts "TrunkSts";
BA_ "Origin" SG_ 793 TrunkSts "fuel,ev";
BA_ "GenSigCycleTime" SG_ 793 DrvDoorSts 50;
BA_ "Match" SG_ 793 DrvDoorSts "DrvDoorSts";
BA_ "Origin" SG_ 793 DrvDoorSts "fuel,ev";
BA_ "GenSigCycleTime" SG_ 793 LRDoorSts 50;
BA_ "Match" SG_ 793 LRDoorSts "LRDoorSts";
BA_ "Origin" SG_ 793 LRDoorSts "fuel,ev";
BA_ "GenSigCycleTime" SG_ 793 PassengerDoorSts 50;
BA_ "Match" SG_ 793 PassengerDoorSts "PassengerDoorSts";
BA_ "Origin" SG_ 793 PassengerDoorSts "fuel,ev";
BA_ "GenSigCycleTime" SG_ 793 RRDoorSts 50;
BA_ "Match" SG_ 793 RRDoorSts "RRDoorSts";
BA_ "Origin" SG_ 793 RRDoorSts "fuel,ev";
BA_ "GenSigCycleTime" SG_ 793 BrkPedalSts_BCM 50;
BA_ "Match" SG_ 793 BrkPedalSts_BCM "BrkPedalSts_BCM";
BA_ "Origin" SG_ 793 BrkPedalSts_BCM "fuel,ev";
BA_ "GenSigCycleTime" SG_ 793 BackgroundLightLvl 50;
BA_ "GenSigStartValue" SG_ 793 BackgroundLightLvl 128;
BA_ "Match" SG_ 793 BackgroundLightLvl "BackgroundLightLvl";
BA_ "Origin" SG_ 793 BackgroundLightLvl "fuel,ev";
BA_ "GenSigCycleTime" SG_ 793 DrowsyDrvDetWarn 50;
BA_ "Match" SG_ 793 DrowsyDrvDetWarn "DrowsyDrvDetWarn";
BA_ "Origin" SG_ 793 DrowsyDrvDetWarn "fuel,ev";
BA_ "GenSigCycleTime" SG_ 793 RLSFailSts 50;
BA_ "Match" SG_ 793 RLSFailSts "RLSFailSts";
BA_ "Origin" SG_ 793 RLSFailSts "fuel,ev";
BA_ "GenSigCycleTime" SG_ 793 PosnLightReq 50;
BA_ "Match" SG_ 793 PosnLightReq "PosnLightReq";
BA_ "Origin" SG_ 793 PosnLightReq "fuel,ev";
BA_ "GenSigCycleTime" SG_ 793 WindshldWiprActvSts 50;
BA_ "Match" SG_ 793 WindshldWiprActvSts "WindshldWiprActvSts";
BA_ "Origin" SG_ 793 WindshldWiprActvSts "fuel,ev";
BA_ "GenSigCycleTime" SG_ 793 FreshnessValue_BCM1 50;
BA_ "Match" SG_ 793 FreshnessValue_BCM1 "FreshnessValue_BCM1";
BA_ "Origin" SG_ 793 FreshnessValue_BCM1 "fuel,ev";
BA_ "GenSigCycleTime" SG_ 793 MAC_Check_BCM1 50;
BA_ "Match" SG_ 793 MAC_Check_BCM1 "MAC_Check_BCM1";
BA_ "Origin" SG_ 793 MAC_Check_BCM1 "fuel,ev";
BA_ "GenSigCycleTime" SG_ 773 ExpertModSwtReq 100;
BA_ "Match" SG_ 773 ExpertModSwtReq "ExpertModSwtReq";
BA_ "Origin" SG_ 773 ExpertModSwtReq "fuel,ev";
BA_ "GenSigCycleTime" SG_ 773 CCO_SwtShift_Warn 100;
BA_ "Match" SG_ 773 CCO_SwtShift_Warn "CCO_SwtShift_Warn";
BA_ "Origin" SG_ 773 CCO_SwtShift_Warn "fuel,ev";
BA_ "GenSigCycleTime" SG_ 773 TAB_SwtShift_Warn 100;
BA_ "Match" SG_ 773 TAB_SwtShift_Warn "TAB_SwtShift_Warn";
BA_ "Origin" SG_ 773 TAB_SwtShift_Warn "fuel,ev";
BA_ "GenSigCycleTime" SG_ 773 FourLModeSts 100;
BA_ "Match" SG_ 773 FourLModeSts "FourLModeSts";
BA_ "Origin" SG_ 773 FourLModeSts "fuel,ev";
BA_ "GenSigCycleTime" SG_ 773 Wade_Sw_Warn 100;
BA_ "Match" SG_ 773 Wade_Sw_Warn "Wade_Sw_Warn";
BA_ "Origin" SG_ 773 Wade_Sw_Warn "fuel,ev";
BA_ "GenSigCycleTime" SG_ 773 WadeSwtReq 100;
BA_ "Match" SG_ 773 WadeSwtReq "WadeSwtReq";
BA_ "Origin" SG_ 773 WadeSwtReq "fuel,ev";
BA_ "GenSigCycleTime" SG_ 568 SrAntiPinch 50;
BA_ "Match" SG_ 568 SrAntiPinch "SrAntiPinch";
BA_ "Origin" SG_ 568 SrAntiPinch "fuel,ev";
BA_ "GenSigCycleTime" SG_ 568 SsPosn_VR_APP 50;
BA_ "GenSigStartValue" SG_ 568 SsPosn_VR_APP 127;
BA_ "Match" SG_ 568 SsPosn_VR_APP "SsPosn_VR_APP";
BA_ "Origin" SG_ 568 SsPosn_VR_APP "fuel,ev";
BA_ "GenSigCycleTime" SG_ 568 SsAntiPinch 50;
BA_ "Match" SG_ 568 SsAntiPinch "SsAntiPinch";
BA_ "Origin" SG_ 568 SsAntiPinch "fuel,ev";
BA_ "GenSigCycleTime" SG_ 568 SrPosn_VR_APP 50;
BA_ "GenSigStartValue" SG_ 568 SrPosn_VR_APP 127;
BA_ "Match" SG_ 568 SrPosn_VR_APP "SrPosn_VR_APP";
BA_ "Origin" SG_ 568 SrPosn_VR_APP "fuel,ev";
BA_ "GenSigCycleTime" SG_ 568 RLS_IRBrightness 50;
BA_ "Match" SG_ 568 RLS_IRBrightness "RLS_IRBrightness";
BA_ "Origin" SG_ 568 RLS_IRBrightness "fuel,ev";
BA_ "GenSigCycleTime" SG_ 568 RLS_FwBrightness 50;
BA_ "Match" SG_ 568 RLS_FwBrightness "RLS_FwBrightness";
BA_ "Origin" SG_ 568 RLS_FwBrightness "fuel,ev";
BA_ "GenSigCycleTime" SG_ 568 RLS_AmbBrightness 50;
BA_ "Match" SG_ 568 RLS_AmbBrightness "RLS_AmbBrightness";
BA_ "Origin" SG_ 568 RLS_AmbBrightness "fuel,ev";
BA_ "GenSigCycleTime" SG_ 675 DrvSeatHeatSts_Nine 100;
BA_ "Match" SG_ 675 DrvSeatHeatSts_Nine "DrvSeatHeatSts_Nine";
BA_ "Origin" SG_ 675 DrvSeatHeatSts_Nine "fuel,ev";
BA_ "GenSigCycleTime" SG_ 675 PassSeatHeatSts_Nine 100;
BA_ "Match" SG_ 675 PassSeatHeatSts_Nine "PassSeatHeatSts_Nine";
BA_ "Origin" SG_ 675 PassSeatHeatSts_Nine "fuel,ev";
BA_ "GenSigCycleTime" SG_ 675 SecRowLeSeatHeatSts_Nine 100;
BA_ "Match" SG_ 675 SecRowLeSeatHeatSts_Nine "SecRowLeSeatHeatSts_Nine";
BA_ "Origin" SG_ 675 SecRowLeSeatHeatSts_Nine "fuel,ev";
BA_ "GenSigCycleTime" SG_ 675 SecRowRiSeatHeatSts_Nine 100;
BA_ "Match" SG_ 675 SecRowRiSeatHeatSts_Nine "SecRowRiSeatHeatSts_Nine";
BA_ "Origin" SG_ 675 SecRowRiSeatHeatSts_Nine "fuel,ev";
BA_ "GenSigCycleTime" SG_ 837 LasHdLmpSts 50;
BA_ "Match" SG_ 837 LasHdLmpSts "LasHdLmpSts";
BA_ "Origin" SG_ 837 LasHdLmpSts "fuel,ev";
BA_ "GenSigCycleTime" SG_ 837 AntitheftSts 50;
BA_ "Match" SG_ 837 AntitheftSts "AntitheftSts";
BA_ "Origin" SG_ 837 AntitheftSts "fuel,ev";
BA_ "GenSigCycleTime" SG_ 837 DrvDoorLockSts 50;
BA_ "Match" SG_ 837 DrvDoorLockSts "DrvDoorLockSts";
BA_ "Origin" SG_ 837 DrvDoorLockSts "fuel,ev";
BA_ "GenSigCycleTime" SG_ 837 DoorLockSts 50;
BA_ "Match" SG_ 837 DoorLockSts "DoorLockSts";
BA_ "Origin" SG_ 837 DoorLockSts "fuel,ev";
BA_ "GenSigCycleTime" SG_ 837 HiLowBeamSts 50;
BA_ "Match" SG_ 837 HiLowBeamSts "HiLowBeamSts";
BA_ "Origin" SG_ 837 HiLowBeamSts "fuel,ev";
BA_ "GenSigCycleTime" SG_ 837 FreshnessValue_BCM3 50;
BA_ "Match" SG_ 837 FreshnessValue_BCM3 "FreshnessValue_BCM3";
BA_ "Origin" SG_ 837 FreshnessValue_BCM3 "fuel,ev";
BA_ "GenSigCycleTime" SG_ 837 MAC_Check_BCM3 50;
BA_ "Match" SG_ 837 MAC_Check_BCM3 "MAC_Check_BCM3";
BA_ "Origin" SG_ 837 MAC_Check_BCM3 "fuel,ev";

VAL_ 849 CheckSum_ABM1 0 "Valid values" 255 "Valid values";
VAL_ 849 SecRowLSBR 0 "No reminder" 1 "Reminder";
VAL_ 849 AirbFailLmpCmd 0 "Lamp off" 1 "Lamp on";
VAL_ 849 SecRowMidSBR 0 "No reminder" 1 "Reminder";
VAL_ 849 DrvSBR 0 "No reminder" 1 "Reminder";
VAL_ 849 SecRowRSBR 0 "No reminder" 1 "Reminder";
VAL_ 849 PassSBR 0 "No reminder" 1 "Reminder";
VAL_ 849 PassSBR_Visual 0 "Lamp off" 1 "Lamp on" 2 "Reserved" 3 "Lamp  blink & sound remind";
VAL_ 849 DrvSBR_Visual 0 "Lamp off" 1 "Lamp on" 2 "Reserved" 3 "Lamp  blink & sound remind";
VAL_ 849 SecRowLSBR_Visual 0 "Lamp off" 1 "Lamp on" 2 "Reserved" 3 "Lamp  blink & sound remind";
VAL_ 849 SecRowMidSBR_Visual 0 "Lamp off" 1 "Lamp on" 2 "Reserved" 3 "Lamp  blink & sound remind";
VAL_ 849 SecRowRSBR_Visual 0 "Lamp off" 1 "Lamp on" 2 "Reserved" 3 "Lamp  blink & sound remind";
VAL_ 849 CrashOutputSts 0 "No crash" 1 "Reserved" 2 "Front First level" 3 "rear crash(Reserved)" 4 "Reserved" 7 "Reserved" 8 "Right hand side" 9 "Reserved" 15 "Reserved" 16 "Left hand side" 17 "Rollover(Reserved)" 18 "Static Roll(Reserved)" 19 "Reserved" 255 "Reserved";
VAL_ 849 RollingCounter_ABM1 0 "Valid value" 14 "Valid value" 15 "Invalid value";
VAL_ 581 VehLgtAccel 0 "Valid Value" 44066 "Valid Value" 44067 "Reserved" 65535 "Reserved";
VAL_ 581 VehLatAccel 0 "Valid Value" 44066 "Valid Value" 44067 "Reserved" 65535 "Reserved";
VAL_ 581 VehYawRate 0 "Valid Value" 17441 "Valid Value" 17442 "Reserved" 65535 "Reserved";
VAL_ 581 VehLgtAccelVld 0 "Invalid" 1 "Valid";
VAL_ 581 VehLatAccelVld 0 "Invalid" 1 "Valid";
VAL_ 581 VehDynYawRateVld 0 "Invalid" 1 "Valid";
VAL_ 561 FLWheelDriveDirection 0 "Invalid" 1 "Forward" 2 "Backward" 3 "Stop";
VAL_ 561 FRWheelDriveDirection 0 "Invalid" 1 "Forward" 2 "Backward" 3 "Stop";
VAL_ 561 FLWheelSpd 0 "Valid values" 5333 "Valid values" 5334 "Reserved" 8191 "Reserved";
VAL_ 561 FLWheelSpdVld 0 "Invalid" 1 "Valid";
VAL_ 561 FRWheelSpdVld 0 "Invalid" 1 "Valid";
VAL_ 561 FRWheelSpd 0 "Valid values" 5333 "Valid values" 5334 "Reserved" 8191 "Reserved";
VAL_ 561 WssFLEdgesSum 0 "Valid values" 255 "Valid values";
VAL_ 561 WssFREdgesSum 0 "Valid Values" 255 "Valid Values";
VAL_ 561 WssFLEdgesSumVld 0 "Invalid" 1 "Valid";
VAL_ 561 WssFREdgesSumVld 0 "Invalid" 1 "Valid";
VAL_ 582 RLWheelSpdVld 0 "Invalid" 1 "Valid";
VAL_ 582 RLWheelSpd 0 "Valid values" 5333 "Valid values" 5334 "Reserved" 8191 "Reserved";
VAL_ 582 RRWheelSpdVld 0 "Invalid" 1 "Valid";
VAL_ 582 RRWheelSpd 0 "Valid values" 5333 "Valid values" 5334 "Reserved" 8191 "Reserved";
VAL_ 582 RLWheelDriveDirection 0 "Invalid" 1 "Forward" 2 "Backward" 3 "Stop";
VAL_ 582 RRWheelDriveDirection 0 "Invalid" 1 "Forward" 2 "Backward" 3 "Stop";
VAL_ 582 WssRREdgesSum 0 "Valid Values" 255 "Valid Values";
VAL_ 582 WssRLEdgesSum 0 "Valid Values" 255 "Valid Values";
VAL_ 582 WssRLEdgesSumVld 0 "Invalid" 1 "Valid";
VAL_ 582 WssRREdgesSumVld 0 "Invalid" 1 "Valid";
VAL_ 669 InCarTemp 0 "Valid value" 253 "Valid value" 254 "Initial value" 255 "Invalid value";
VAL_ 669 ACAQSEnaSts 0 "Disable" 1 "Enable";
VAL_ 669 ACOperMod 0 "Economy Mode" 1 "Standard Mode" 2 "Strong Mode" 3 "Reserved" 7 "Reserved";
VAL_ 669 ACAIUEnaSts 0 "Disable" 1 "Enable";
VAL_ 669 ACDrvAirDistriMod 0 "Face" 1 "Face & Foot" 2 "Foot" 3 "Foot & Defrost" 4 "Defrost" 5 "Reserved" 6 "Reserved" 7 "Auto air distribution mode";
VAL_ 669 ACSteplessSpdSetEnaSts 0 "Disable" 1 "Enable";
VAL_ 669 ACFrntPassTempSteplessSetEnaSts 0 "Disable" 1 "Enable";
VAL_ 669 ACDrvTempSteplessSetEnaSts 0 "Disable" 1 "Enable";
VAL_ 669 ACEEMSts 0 "Normal mode" 1 "Transport_static mode" 2 "Transport_Dynamic mode" 3 "Static_power saving level 1" 4 "Static_power saving level 2" 5 "Dynamic_power saving level 4" 6 "Dynamic_power saving level 5" 7 "Power system error" 8 "Reserved" 15 "Reserved";
VAL_ 901 ACFrntDefrstSts 0 "Off" 1 "On";
VAL_ 901 ACHMIDispCmd 0 "No Display" 1 "No DisplayÃ¯Â¼ÂˆAC status changed in Auto modeÃ¯Â¼Â‰" 2 "Display" 3 "Reserved";
VAL_ 901 ACFrntBlwrSpd 0 "Off" 1 "Level 1Ã¯Â¼ÂˆLowÃ¯Â¼Â‰-7Ã¯Â¼ÂˆHiÃ¯Â¼Â‰" 7 "Level 1Ã¯Â¼ÂˆLowÃ¯Â¼Â‰-7Ã¯Â¼ÂˆHiÃ¯Â¼Â‰" 8 "Reserved" 13 "Reserved" 14 "Auto blower level" 15 "Initial value";
VAL_ 901 ACOpenSts 0 "Off" 1 "On";
VAL_ 901 ACDualModEnaSts 0 "Disable" 1 "Enable";
VAL_ 901 ACDrvTemp_ATC 0 "Low" 1 "Valid value" 31 "Valid value" 32 "High" 33 "Initial value" 34 "Reserved" 63 "Reserved";
VAL_ 901 ACAmbTemp 0 "Valid value" 253 "Valid value" 254 "Initial value" 255 "Invalid Value";
VAL_ 901 ACAirInletSts 0 "Recirculation" 1 "Fresh" 2 "Auto" 3 "Initial value";
VAL_ 901 ACFrntPasstTemp_ATC 0 "Low" 1 "Valid value" 31 "Valid value" 32 "High" 33 "Initial value" 34 "Reserved" 63 "Reserved";
VAL_ 901 ACAutoModEnaSts 0 "Disable" 1 "Enable";
VAL_ 901 ACCmprEnaSts 0 "Disable" 1 "Enable";
VAL_ 901 ACRearWinHeatSts 0 "Off" 1 "On";
VAL_ 901 ACAutoDefrstModEnaSts 0 "Disable" 1 "Enable";
VAL_ 765 ACRearAirDistriMod 0 "Face" 1 "Face & Foot" 2 "Foot" 3 "Auto air distribution mode";
VAL_ 765 ACReartBlwrSpd 0 "Off" 1 "Level 1(Low)-7(Hi)" 7 "Level 1(Low)-7(Hi)" 8 "Reserved" 13 "Reserved" 14 "Auto blower level" 15 "Initial value";
VAL_ 765 RearACAutoModEnaSts 0 "Disable" 1 "Enable";
VAL_ 765 ACRearSteplessSpdSetEnaSts 0 "Disable" 1 "Enable";
VAL_ 765 ACRLTempStepleSetEnaSts 0 "Disable" 1 "Enable";
VAL_ 765 ACRearHMIDispCmd 0 "No Display" 1 "No DisplayÃ¯Â¼ÂˆAC status changed in Auto modeÃ¯Â¼Â‰" 2 "Display" 3 "Reserved";
VAL_ 765 ACRearLockSts 0 "unlockÃ¯Â¼Âˆrear contorl enableÃ¯Â¼Â‰" 1 "LockÃ¯Â¼Âˆrear control disableÃ¯Â¼Â‰";
VAL_ 765 ACRearOpenSts 0 "Off" 1 "On";
VAL_ 716 ACMaxEnaSts 0 "Disable" 1 "Enable";
VAL_ 716 ACZoneModEnaSts 0 "Disable" 1 "Enable";
VAL_ 716 L_FGAChan1TimeoutAlarm 0 "No alarm" 1 "Alarm";
VAL_ 716 L_FGAChan2TimeoutAlarm 0 "No alarm" 1 "Alarm";
VAL_ 716 L_FGAChan3TimeoutAlarm 0 "No alarm" 1 "Alarm";
VAL_ 760 L_PM25InAirQltyLvl 0 "Initial value" 1 "Level 1(Low) - 6(Hi)" 6 "Level 1(Low) - 6(Hi)" 7 "Invalid Value";
VAL_ 760 L_PM25InDens 0 "Valid value" 999 "Valid value" 1000 "Reserved" 1022 "Reserved" 1023 "Invalid value";
VAL_ 760 L_FGAEnaSts 0 "Disable" 1 "Enable";
VAL_ 760 L_FGALvlResp 0 "Off" 1 "Level1 (Low)" 2 "Level2 (Mid)" 3 "Level3 (High)";
VAL_ 760 L_FGAChanTypSts 0 "Off" 1 "Channel 1" 2 "Channel 2" 3 "Channel 3";
VAL_ 720 FG_Chan1Typ 0 "Valid Value" 14 "Valid Value" 15 "No conncet";
VAL_ 720 FG_Chan2Typ 0 "Valid Value" 14 "Valid Value" 15 "No conncet";
VAL_ 720 FG_Chan3Typ 0 "Valid Value" 14 "Valid Value" 15 "No conncet";
VAL_ 720 L_FGAChan1IllegalitySts 0 "Normal" 1 "Unnomal";
VAL_ 720 L_FGAChan2IllegalitySts 0 "Normal" 1 "Unnomal";
VAL_ 720 L_FGAChan3IllegalitySts 0 "Normal" 1 "Unnomal";
VAL_ 636 RearInCarTemp 0 "Valid value" 253 "Valid value" 254 "Initial value" 255 "Invalid value";
VAL_ 636 ACRLTemp_ATC 0 "Low" 1 "Valid value" 31 "Valid value" 32 "High" 33 "Initial value" 34 "Reserved" 63 "Reserved";
VAL_ 665 FGA_Chan1LongTyp 0 "Valid Value" 14 "Valid Value" 15 "No_connect" 16 "Valid Value" 2047 "Valid Value";
VAL_ 665 FGA_Chan2LongTyp 0 "Valid Value" 14 "Valid Value" 15 "No_connect" 16 "Valid Value" 2047 "Valid Value";
VAL_ 665 FGA_Chan3LongTyp 0 "Valid Value" 14 "Valid Value" 15 "No_connect" 16 "Valid Value" 2047 "Valid Value";
VAL_ 683 ACC_LeTgt_02_Dy 0 "Valid value" 81 "Valid value" 82 "Reserved" 127 "Reserved";
VAL_ 683 ACC_LeTgt_02_Dx 0 "Valid value" 300 "Valid value" 301 "Reserved" 511 "Reserved";
VAL_ 683 ACC_LeTgt_02_Typ 0 "Unkown" 1 "Sedan" 2 "Truck" 3 "Motorcycle" 4 "Pedestrian" 5 "Bicycle" 6 "Traffic_cone" 7 "Obstacle";
VAL_ 683 ACC_LeTargrt_02_Detn 0 "Not dectected" 1 "Dectected" 2 "Reserved" 3 "Invalid";
VAL_ 683 ACC_RiTargrt_02_Detn 0 "Not dectected" 1 "Dectected" 2 "Reserved" 3 "Invalid";
VAL_ 683 ACC_RiTgt_02_Dy 0 "Valid value" 81 "Valid value" 82 "Reserved" 127 "Reserved";
VAL_ 683 ACC_RiTgt_02_Dx 0 "Valid value" 300 "Valid value" 301 "Reserved" 511 "Reserved";
VAL_ 683 ACC_RiTgt_02_Typ 0 "Unkown" 1 "Sedan" 2 "Truck" 3 "Motorcycle" 4 "Pedestrian" 5 "Bicycle" 6 "Traffic_cone" 7 "Obstacle";
VAL_ 683 ACC_LeTgtObjBarDisp 0 "No display" 1 "Distance_1 one bar" 2 "Distance_2 two bars" 3 "Distance_3 three bars" 4 "Distance_4 four bars" 5 "Resvered" 7 "Resvered";
VAL_ 683 ACC_RiTgtObjBarDisp 0 "No display" 1 "Distance_1 one bar" 2 "Distance_2 two bars" 3 "Distance_3 three bars" 4 "Distance_4 four bars" 5 "Resvered" 7 "Resvered";
VAL_ 683 Checksum_ACC3 0 "Valid value" 255 "Valid value";
VAL_ 683 ICA_HandsOffResp 0 "OFF" 1 "ON";
VAL_ 683 ALC_Resp 0 "OFF" 1 "ON";
VAL_ 683 HWA_Resp 0 "OFF" 1 "ON";
VAL_ 683 ISL_Resp 0 "OFF" 1 "ON";
VAL_ 683 HWA_SnvtySet_Resp 0 "Normal" 1 "High sensitivity" 2 "Low sensitivity" 3 "Reserved";
VAL_ 683 Longctrl_VehHldReq_DVR 0 "No Request" 1 "Request";
VAL_ 683 Longctrl_DrvOFF_Req_DVR 0 "No Request" 1 "Request";
VAL_ 683 Longctrl_ModSts_DVR 0 "OFF mode" 1 "Passive mode(Reject)" 2 "Passive mode(Stand-by)" 3 "Active-Control mode" 4 "Brake-only mode" 5 "Override" 6 "Standstill" 7 "Failure mode Longctrl" 8 "Reserved" 9 "Shut off" 10 "Reserved" 15 "Reserved";
VAL_ 683 Longctrl_Decel_Req_DVR 0 "No Request" 1 "Request";
VAL_ 683 Longctrl_EngTrqReq_DVR 0 "Valid value" 65535 "Valid value";
VAL_ 683 Longctrl_EngTrqReqActive_DVR 0 "Not active" 1 "Active";
VAL_ 683 Longctrl_DecelToStopReq_DVR 0 "No Request" 1 "Request";
VAL_ 683 Longctrl_ParkShiftReq_DVR 0 "No request" 1 "Request park Shift" 2 "Invalid" 3 "Reserved";
VAL_ 683 Longctrl_Decel_ReqValue_DVR 0 "Valid value" 255 "Valid value";
VAL_ 683 ALC_InterSysInfoDisp 0 "No display" 1 "Automatic lane change function failure" 2 "Reserve" 3 "Reserve";
VAL_ 683 RollingCounter_ACC3 0 "Valid value" 14 "Valid value" 15 "Invalid value";
VAL_ 683 Checksum_ACC4 0 "Valid value" 255 "Valid value";
VAL_ 683 ACC_ObjDetecte 0 "No object" 1 "Target object detected";
VAL_ 683 ACC_TakeOverReq 0 "No TakeOver request" 1 "Valid TakeOver request";
VAL_ 683 ACC_InterSysInfoDisp 0 "No display" 1 "Unable to activate ACC due to speed not achive" 2 "ACC active control is cancelled" 3 "Resvered" 4 "ACC and PEBS temporary unavailable" 5 "Unable to activate ACC due to other limitation(except speed not achive)" 6 "ACC and PEBS error" 7 "ACC temporary unavailable" 8 "ACC is active" 9 "Blindness" 10 "Resvered" 31 "Resvered";
VAL_ 683 ACC_ModDisp 0 "OFF Mode" 1 "Passive Mode" 2 "StandBy Mode" 3 "Active-Control Mode" 4 "Brake-Only Mode" 5 "Override" 6 "Reserved" 7 "ACC and PEBS Failure mode" 8 "ACC Failure mode" 9 "Reserved" 31 "Reserved";
VAL_ 683 ACC_FctSts 0 "Fuction Not  Available" 1 "Fuction Available" 2 "Performance degradation" 3 "Reserved";
VAL_ 683 ACC_TgtObjBarDisp 0 "No display" 1 "Distance_1 one bar" 2 "Distance_2 two bars" 3 "Distance_3 three bars" 4 "Distance_4 four bars" 5 "Resvered" 7 "Resvered";
VAL_ 683 Longctrl_HazActv 0 "Not active" 1 "AEB active" 2 "Safestop active" 3 "Reserved";
VAL_ 683 TJA_ACC_SelSts 0 "off" 1 "ACC selected" 2 "TJAICA selected" 3 "Off selected" 4 "ACC on" 5 "TJAICA on" 6 "Reserved" 7 "Reserved";
VAL_ 683 CruCha_ModDisp 0 "OFF mode" 1 "Idle mode" 2 "Ready mode" 3 "Active" 4 "Reserved" 5 "Warning Level 1" 6 "Warning Level 2" 7 "Warning Level 3" 8 "Reserved" 9 "Failure" 10 "Reserved" 15 "Reserved";
VAL_ 683 TJA_ICA_InterSysInfoDisp 0 "No display" 1 "Unable to activate TJAICA due to other limitation" 2 "TJAICA active control is cancelled" 3 "TJAICA   temporarily unavailable" 4 "Current IGN Cycle Function Inhibit" 5 "TJA is active" 6 "Restart or P gear to activate" 7 "Resvered";
VAL_ 683 TJA_ICA_ModDisp 0 "OFF_mode" 1 "Passive_mode" 2 "Active_mode" 3 "Ready_mode" 4 "Failure" 5 "Recoverable_mode" 6 "Reserved" 7 "Reserved";
VAL_ 683 ISL_InterSysInfoDisp 0 "no_display" 1 "Speed_Limit_Confirm_Request" 2 "Speed_Limit_Take_Over_Request" 3 "Reduce_speed_on_a_curve";
VAL_ 683 ACC_TimeGapSet 0 "No display" 1 "TimeGap_1 1s" 2 "TimeGap_2 1.4s" 3 "TimeGap_3 1.8s" 4 "TimeGap_4 2.1s" 5 "Reserved" 7 "Reserved";
VAL_ 683 ACC_SpdSetValue 0 "Valid value" 254 "Valid value" 255 "No display";
VAL_ 683 CruChar_InterSysInfoDisp 0 "No display" 1 "Unable to activate CruiseChauffer due to other limitation" 2 "CruiseChauffer active control is cancelled" 3 "CruiseChauffer temporarily unavailable" 4 "Take over request" 5 "Current IGN Cycle Function Inhibit" 6 "Please Keep Attention" 7 "To cross the tunnel, please take over  in time" 8 "Have a branch road ahead. Please take over in time" 9 "Hands off warning" 10 "Reserved" 15 "Reserved";
VAL_ 683 RollingCounter_ACC4 0 "Valid value" 14 "Valid value" 15 "Invalid value";
VAL_ 683 Checksum_ACC8 0 "Valid value" 255 "Valid value";
VAL_ 683 HWA_ModDisp 0 "OFF" 1 "Safstop" 2 "Passive" 3 "Ready" 4 "Active" 5 "Override" 6 "Slow retreat" 7 "Standstill" 8 "Reserved" 14 "Reserved" 15 "Fault";
VAL_ 683 HWA_InterSysInfoDisp 0 "No display" 1 "Left Overtaking" 2 "Right Overtaking" 3 "Turn off the turn light" 4 "Rainmode activated" 5 "Overtime for lane change" 6 "lane change is cancelled" 7 "Rainmode deactivated" 8 "Speed is too low to support lane change" 9 "Reserved" 10 "Take over request" 11 "Please Keep Attention" 12 "To cross the tunnel, please take over in time" 13 "Have a branch road ahead Please take over in time" 14 "Sharp bend ahead Please take over in time" 15 "Speed is too high to support lane change";
VAL_ 683 HWA_LaneChange 0 "No display" 1 "left" 2 "right" 3 "reserved";
VAL_ 683 HWA_LaneChangeReq 0 "No display" 1 "left satisfied" 2 "right satisfied" 3 "left not satisfied" 4 "right not satisfied" 5 "reserved" 7 "reserved";
VAL_ 683 HWA_Warning 0 "No Warning" 1 "Warning Level 1" 2 "Warning Level 2" 3 "Warning Level 3";
VAL_ 683 RollingCounter_ACC8 0 "Valid value" 14 "Valid value" 15 "Invalid value";
VAL_ 683 Checksum_ACC6 0 "Valid value" 255 "Valid value";
VAL_ 683 ACC_PotentialTgtDy 0 "Valid value" 160 "Valid value" 161 "Reserved" 255 "Reserved";
VAL_ 683 ACC_PotentialTgtDx 0 "Valid value" 300 "Valid value" 301 "Reserved" 511 "Reserved";
VAL_ 683 ACC_RlvTgtDetn 0 "Not dectected" 1 "Dectected" 2 "Reserved" 3 "Invalid";
VAL_ 683 ACC_EgoStatus 0 "No Display" 1 "Override" 2 "Deceleration" 3 "Reserved";
VAL_ 683 ACC_RlvTgtTyp 0 "Unkown" 1 "Sedan" 2 "Truck" 3 "Motorcycle" 4 "Pedestrian" 5 "Bicycle" 6 "Traffic_cone" 7 "Obstacle";
VAL_ 683 ACC_RlvTgtDy 0 "Valid value" 160 "Valid value" 161 "Reserved" 255 "Reserved";
VAL_ 683 ACC_RlvTgtDx 0 "Valid value" 300 "Valid value" 301 "Reserved" 511 "Reserved";
VAL_ 683 ACC_PotentialTgtDetn 0 "Not dectected" 1 "Dectected" 2 "Reserved" 3 "Invalid";
VAL_ 683 ACC_PotentialTgtTyp 0 "Unkown" 1 "Sedan" 2 "Truck" 3 "Motorcycle" 4 "Pedestrian" 5 "Bicycle" 6 "Traffic_cone" 7 "Obstacle";
VAL_ 683 RollingCounter_ACC6 0 "Valid value" 14 "Valid value" 15 "Invalid value";
VAL_ 683 Checksum_ACC7 0 "Valid value" 255 "Valid value";
VAL_ 683 Request_driveoff 0 "no request" 1 "The front car has started" 2 "The front car has started,Please pay attention to the road environment ahead" 3 "The front car has started,please keep your attention" 4 "The front car has started,please take over the car" 5 "Reserved" 7 "Reserved";
VAL_ 683 ACCSts 0 "Deactive" 1 "Active";
VAL_ 683 ACC_LeTgtDy 0 "Valid value" 160 "Valid value" 161 "Reserved" 255 "Reserved";
VAL_ 683 ACC_LeTgtDx 0 "Valid value" 300 "Valid value" 301 "Reserved" 511 "Reserved";
VAL_ 683 ACC_LeTgtTyp 0 "Unkown" 1 "Sedan" 2 "Truck" 3 "Motorcycle" 4 "Pedestrian" 5 "Bicycle" 6 "Traffic_cone" 7 "Obstacle";
VAL_ 683 ACC_LeTargrtDection 0 "Not dectected" 1 "Dectected" 2 "Reserved" 3 "Invalid";
VAL_ 683 ACC_RiTargrtDetn 0 "Not dectected" 1 "Dectected" 2 "Reserved" 3 "Invalid";
VAL_ 683 ACC_RiTgtDy 0 "Valid value" 160 "Valid value" 161 "Reserved" 255 "Reserved";
VAL_ 683 ACC_RiTgtDx 0 "Valid value" 300 "Valid value" 301 "Reserved" 511 "Reserved";
VAL_ 683 ACC_RiTgtTyp 0 "Unkown" 1 "Sedan" 2 "Truck" 3 "Motorcycle" 4 "Pedestrian" 5 "Bicycle" 6 "Traffic_cone" 7 "Obstacle";
VAL_ 683 RollingCounter_ACC7 0 "Valid value" 14 "Valid value" 15 "Invalid value";
VAL_ 683 ACC_RlvTgtfusion 0 "no fusion" 1 "fusion";
VAL_ 683 ACC_RlvTgtHeading 0 "valid value" 60 "valid value" 61 "Reserved" 63 "Reserved";
VAL_ 683 ACC_LeTgtfusion 0 "no fusion" 1 "fusion";
VAL_ 683 ACC_LeTgtHeading 0 "valid value" 60 "valid value" 61 "Reserved" 63 "Reserved";
VAL_ 683 ACC_RiTgtfusion 0 "no fusion" 1 "fusion";
VAL_ 683 ACC_RiTgtHeading 0 "valid value" 60 "valid value" 61 "Reserved" 63 "Reserved";
VAL_ 683 ACC_PotentialTgtfusion 0 "no fusion" 1 "fusion";
VAL_ 683 ACC_PotentialTgtHeading 0 "valid value" 60 "valid value" 61 "Reserved" 63 "Reserved";
VAL_ 683 TargetCutinPro 0 "valid value" 50 "Reserved" 63 "Reserved";
VAL_ 683 TargetCutoutPro 0 "valid value" 50 "Reserved" 63 "Reserved";
VAL_ 683 Longctrl_WheelTrqReqActive_DVR 0 "Not active" 1 "Active";
VAL_ 683 Longctrl_WheelTrqReq_DVR 0 "Valid value" 65535 "Valid value";
VAL_ 692 JAPedObjExist 0 "Valid Value" 63 "Valid Value";
VAL_ 692 AEBJAObjID 0 "Valid Value" 254 "Valid Value" 255 "No Object";
VAL_ 692 AEBJAObjExist 0 "Valid Value" 63 "Valid Value";
VAL_ 692 JAPedObjID 0 "Valid Value" 254 "Valid Value" 255 "No Object";
VAL_ 692 AEBJAObjVideoCfmd 0 "No Fusion" 1 "Fusion";
VAL_ 692 AEBJAObjVx 0 "Valid Value" 2047 "Valid Value" 4081 "Reserved" 4095 "Reserved";
VAL_ 692 AEBJAObjDx 0 "Valid Value" 4095 "Valid Value";
VAL_ 692 JAPedObjVideoCfmd 0 "No Fusion" 1 "Fusion";
VAL_ 692 AEBJAObjState 0 "UNDEFINED" 1 "PRECEDING" 2 "STATIONARY" 3 "STOPPED" 4 "ONCOMING" 5 "Reserved" 7 "Reserved";
VAL_ 692 AEBJAObjCntAlive 0 "Valid Value" 3855 "Valid Value" 3856 "Reserved" 4095 "Reserved";
VAL_ 692 AEBJAObjDy 0 "Valid Value" 2047 "Valid Value";
VAL_ 692 JAPedObjState 0 "UNDEFINED" 1 "PRECEDING" 2 "STATIONARY" 3 "STOPPED" 4 "ONCOMING" 5 "Reserved" 7 "Reserved";
VAL_ 692 AEBJAObjObstcl 0 "Valid Value" 31 "Valid Value";
VAL_ 692 AEBJAObjVy 0 "Valid Value" 1023 "Valid Value";
VAL_ 692 AEBJAObjAx 0 "Valid Value" 1023 "Valid Value";
VAL_ 692 AEBJAObjAy 0 "Valid Value" 1023 "Valid Value";
VAL_ 692 JAPedObjObstcl 0 "Valid Value" 31 "Valid Value";
VAL_ 692 JAPedObjDy 0 "Valid Value" 2047 "Valid Value";
VAL_ 692 JAPedObjDx 0 "Valid Value" 4095 "Valid Value";
VAL_ 692 FCWAEB_JATTC 0 "No Display" 1 "valid value" 63 "valid value";
VAL_ 692 JAPedObjVx 0 "Valid Value" 4080 "Valid Value" 4081 "Reserved" 4095 "Reserved";
VAL_ 692 JAPedObjVy 0 "Valid Value" 1023 "Valid Value";
VAL_ 692 JAPedObjAy 0 "Valid Value" 1023 "Valid Value";
VAL_ 692 JAPedObjCntAlive 0 "Valid Value" 3855 "Valid Value" 3856 "Reserved" 4095 "Reserved";
VAL_ 692 FCWAEB_longTTC 0 "No Display" 1 "valid value" 63 "valid value";
VAL_ 692 FCWAEB_crossingTTC 0 "No Display" 1 "valid value" 63 "valid value";
VAL_ 692 JAPedObjAx 0 "Valid Value" 1023 "Valid Value";
VAL_ 692 NOH_Sts 0 "OFF" 1 "Passive" 2 "Standby" 3 "Active" 4 "Override" 5 "Slow_retreat" 6 "Standstill" 7 "Inhibit" 8 "Reserved" 14 "Reserved" 15 "Fail";
VAL_ 692 NOH_Swt_Resp 0 "OFF" 1 "ON";
VAL_ 692 NOH_Act_Resp 0 "Deactivate" 1 "Activate";
VAL_ 692 NOH_SysInfoDisplay 0 "Default" 1 "In NOH GeoFence" 2 "NOH is activated" 3 "Please confirm L lane change" 4 "Please confirm R lane change" 5 "To overtake from left" 6 "To overtake from right" 7 "Lane change waiting" 8 "To merge in mainroad" 9 "NOH to be deactivated" 10 "NOH cancelled" 11 "NOH deactivated" 12 "Cruise speed has been set by NOH" 13 "Speed is too high to support NOH" 14 "To merge in fast route" 15 "To merge in ramp";
VAL_ 692 NOH_DistToExit 0 "Valid value" 4095 "Valid value";
VAL_ 696 AEBObjID 0 "Valid Value" 254 "Valid Value" 255 "No Object";
VAL_ 696 AEBObjExist 0 "Valid Value" 63 "Valid Value";
VAL_ 696 AEBObjVideoCfmd 0 "No Fusion" 1 "Fusion";
VAL_ 696 AEBObjVx 0 "Valid Value" 2047 "Valid Value" 4081 "Reserved" 4095 "Reserved";
VAL_ 696 AEBObjDx 0 "Valid Value" 4095 "Valid Value";
VAL_ 696 AEBObjCntAlive 0 "Valid Value" 3855 "Valid Value" 3856 "Reserved" 4095 "Reserved";
VAL_ 696 AEBObjDy 0 "Valid Value" 2047 "Valid Value";
VAL_ 696 AEBObjState 0 "UNDEFINED" 1 "PRECEDING" 2 "STATIONARY" 3 "STOPPED" 4 "Reserved" 7 "Reserved";
VAL_ 696 AEBObjObstcl 0 "Valid Value" 31 "Valid Value";
VAL_ 696 AEBObjVy 0 "Valid Value" 1023 "Valid Value";
VAL_ 696 CyclistObjExist 0 "Valid Value" 63 "Valid Value";
VAL_ 696 AEBObjAx 0 "Valid Value" 1023 "Valid Value";
VAL_ 696 AEBObjAy 0 "Valid Value" 1023 "Valid Value";
VAL_ 696 CyclistObjDx 0 "Valid Value" 4095 "Valid Value";
VAL_ 696 CyclistObjID 0 "Valid Value" 254 "Valid Value" 255 "No Object";
VAL_ 696 CyclistObjObstcl 0 "Valid Value" 31 "Valid Value";
VAL_ 696 CyclistObjDy 0 "Valid Value" 2047 "Valid Value";
VAL_ 696 CyclistObjVx 0 "Valid Value" 4080 "Valid Value" 4081 "Reserved" 4095 "Reserved";
VAL_ 696 CyclistObjCntAlive 0 "Valid Value" 3855 "Valid Value" 3856 "Reserved" 4095 "Reserved";
VAL_ 696 CyclistObjVy 0 "Valid Value" 1023 "Valid Value";
VAL_ 696 CyclistObjState 0 "UNDEFINED" 1 "PRECEDING" 2 "STATIONARY" 3 "STOPPED" 4 "Reserved" 7 "Reserved";
VAL_ 696 CyclistObjVideoCfmd 0 "No Fusion" 1 "Fusion";
VAL_ 696 CyclistObjAx 0 "Valid Value" 1023 "Valid Value";
VAL_ 696 CyclistObjAy 0 "Valid Value" 1023 "Valid Value";
VAL_ 696 PedObjExist 0 "Valid Value" 63 "Valid Value";
VAL_ 696 PedObjID 0 "Valid Value" 254 "Valid Value" 255 "No Object";
VAL_ 696 PedObjObstcl 0 "Valid Value" 31 "Valid Value";
VAL_ 696 PedObjDy 0 "Valid Value" 2047 "Valid Value";
VAL_ 696 PedObjDx 0 "Valid Value" 4095 "Valid Value";
VAL_ 696 PedObjVx 0 "Valid Value" 4080 "Valid Value" 4081 "Reserved" 4095 "Reserved";
VAL_ 696 PedObjVy 0 "Valid Value" 1023 "Valid Value";
VAL_ 696 PedObjVideoCfmd 0 "No Fusion" 1 "Fusion";
VAL_ 696 ACCTgtObjDx 0 "Valid Value" 4095 "Valid Value";
VAL_ 696 PedObjAy 0 "Valid Value" 1023 "Valid Value";
VAL_ 696 PedObjCntAlive 0 "Valid Value" 3855 "Valid Value" 3856 "Reserved" 4095 "Reserved";
VAL_ 696 PedObjAx 0 "Valid Value" 1023 "Valid Value";
VAL_ 696 ACCTgtObjID 0 "Valid Value" 254 "Valid Value" 255 "No Object";
VAL_ 696 ACCTgtObjObstcl 0 "Valid Value" 31 "Valid Value";
VAL_ 696 ACCTgtObjDy 0 "Valid Value" 2047 "Valid Value";
VAL_ 696 ACCTgtObjExist 0 "Valid Value" 63 "Valid Value";
VAL_ 696 ACCTgtObjVy 0 "Valid Value" 1023 "Valid Value";
VAL_ 696 ACCTgtObjVx 0 "Valid Value" 4080 "Valid Value" 4081 "Reserved" 4095 "Reserved";
VAL_ 696 ACCTgtObjAx 0 "Valid Value" 1023 "Valid Value";
VAL_ 696 ACCTgtObjAy 0 "Valid Value" 1023 "Valid Value";
VAL_ 696 ACCTgtObjState 0 "UNDEFINED" 1 "PRECEDING" 2 "STATIONARY" 3 "STOPPED" 4 "Reserved" 7 "Reserved";
VAL_ 696 ACCTgtObjVideoCfmd 0 "No Fusion" 1 "Fusion";
VAL_ 696 ACCTgtObjCntAlive 0 "Valid Value" 3855 "Valid Value" 3856 "Reserved" 4095 "Reserved";
VAL_ 696 RadarHorMisalign 0 "Valid Value" 4095 "Valid Value";
VAL_ 696 HandsoffDetd 0 "Unknown" 1 "Hands off" 2 "Not hands off" 3 "Reserved";
VAL_ 696 DrvgOnHiWay 0 "Unknown" 1 "On Hignway" 2 "Not on hgh way" 3 "Reserved";
VAL_ 696 RoadCrvt 0 "Valid Value(Left bend)" 510 "Valid Value(Left bend)" 511 "Straightaway" 512 "Valid Value((Reft bend))" 1021 "Valid Value((Reft bend))" 1022 "Reserved" 1023 "Unknown";
VAL_ 696 SpdLimitDst 0 "Valid Value" 60 "Valid Value" 61 "Out of Range" 62 "Reserved" 63 "Unknown";
VAL_ 696 RoadCrvtFar 0 "Valid Value(Left bend)" 510 "Valid Value(Left bend)" 511 "Straightaway" 512 "Valid Value((Reft bend))" 1021 "Valid Value((Reft bend))" 1022 "Reserved" 1023 "Unknown";
VAL_ 696 RampDst 0 "Valid Value" 60 "Valid Value" 61 "Out of Range" 62 "Reserved" 63 "Unknown";
VAL_ 696 SpdLimit 0 "No SPL" 1 "SPL 5" 2 "SPL 10" 3 "SPL 15" 4 "SPL 20" 5 "SPL 25" 6 "SPL 30" 7 "SPL 35" 8 "SPL 40" 9 "SPL 45" 10 "SPL 50" 11 "SPL 55" 12 "SPL 60" 13 "SPL 65" 14 "SPL 70" 15 "SPL 75" 16 "SPL 80" 17 "SPL 85" 18 "SPL 90" 19 "SPL 95" 20 "SPL 100" 21 "SPL 105" 22 "SPL 110" 23 "SPL 115" 24 "SPL 120" 25 "SPL 120" 26 "SPL 130" 27 "SPL 135" 28 "SPL 140" 29 "SPL 145" 30 "SPL 150" 31 "Reserved" 62 "Reserved" 63 "Invalid";
VAL_ 696 CurveDst 0 "Valid Value" 60 "Valid Value" 61 "Out of Range" 62 "Reserved" 63 "Unknown";
VAL_ 696 NavSpdLimUnit 0 "Unknown" 1 "KMH" 2 "MPH" 3 "Reserved";
VAL_ 696 TunnelDst 0 "Valid Value" 60 "Valid Value" 61 "Out of Range" 62 "Reserved" 63 "Unknown";
VAL_ 696 DrvgOnRiLane 0 "Unknown" 1 "On right most lane" 2 "Not on right most lane" 3 "Reserved";
VAL_ 696 BrdgDst 0 "Valid Value" 60 "Valid Value" 61 "Out of Range" 62 "Reserved" 63 "Unknown";
VAL_ 696 RadarDrvrAttentive 0 "Inattentive" 1 "Attentive";
VAL_ 696 ACC_DataRecReq 0 "No Demand" 1 "Scenario01" 2 "Scenario02" 3 "Scenario03" 4 "Scenario04" 5 "Scenario05" 6 "Scenario06" 7 "Scenario07" 8 "Scenario08" 9 "Scenario09" 10 "Scenario10" 11 "Scenario11" 12 "Scenario12" 13 "Scenario13" 14 "Scenario14" 15 "Scenario15" 16 "Scenario16" 17 "Scenario17" 18 "Scenario18" 19 "Scenario19" 20 "Scenario20" 21 "Scenario21" 22 "Scenario22" 23 "Scenario23" 24 "Scenario24" 25 "Scenario25" 26 "Scenario26" 27 "Scenario27" 28 "Scenario28" 29 "Scenario29" 30 "Scenario30" 31 "Scenario31" 32 "Scenario32" 33 "Scenario33" 34 "Scenario34" 35 "Scenario35" 36 "Scenario36" 37 "Scenario37" 38 "Scenario38" 39 "Scenario39" 40 "Scenario40" 41 "Scenario41" 42 "Scenario42" 43 "Scenario43" 44 "Scenario44" 45 "Scenario45" 46 "Scenario46" 47 "Scenario47" 48 "Scenario48" 49 "Scenario49" 50 "Scenario50" 51 "Reserved" 255 "Reserved";
VAL_ 696 ACC_SOSReq 0 "No Request" 1 "Request" 2 "Reserved" 3 "Invalid";
VAL_ 696 PedObjState 0 "UNDEFINED" 1 "PRECEDING" 2 "STATIONARY" 3 "STOPPED" 4 "Reserved" 7 "Reserved";
VAL_ 696 MapDataValid 0 "Valid" 1 "Invalid";
VAL_ 696 DrvrSts 0 "Good" 1 "Unbelievable" 2 "Low" 3 "Middle" 4 "High Level 1" 5 "High Level 2" 6 "Reserved" 7 "Reserved";
VAL_ 696 AEBObjOverlap 0 "Valid" 20 "Valid" 21 "reserved" 30 "reserved" 31 "invalid";
VAL_ 696 AEBObjDrvby 0 "Valid" 20 "Valid" 21 "reserved" 30 "reserved" 31 "invalid";
VAL_ 395 AEB_ABA_Level 0 "Level 0" 1 "Level 1" 2 "Level 2" 3 "Level 3";
VAL_ 395 AEB_ABA_Req 0 "No Request" 1 "Request";
VAL_ 395 EBA_TgtDecel_Req 0 "No Request" 1 "Request";
VAL_ 395 AEB_VehHldReq 0 "No Request" 1 "Request";
VAL_ 395 AEB_TgtDecel_Req 0 "No Request" 1 "Request";
VAL_ 395 AEB_TgtDecel_ReqValue 0 "Valid value" 65534 "Valid value" 65535 "Invalid";
VAL_ 395 AEB_AWB_Req 0 "No Request" 1 "Request";
VAL_ 395 AEB_AWB_Level 0 "No level" 1 "Level 1" 2 "Level 2" 3 "Level 3" 4 "Level 4" 5 "Resvered" 15 "Resvered";
VAL_ 395 AEB_ABP_Req 0 "No Request" 1 "Request";
VAL_ 395 AEB_BrkReqFunc 0 "No Request" 1 "AEB-V" 2 "AEB-VRU" 3 "AEB-JA" 4 "Reserved" 5 "AEB-FCTB" 6 "Reserved" 7 "Reserved";
VAL_ 395 AEB_ObjSty 0 "No Object" 1 "Vehicle" 2 "Pedestrian" 3 "Cyclist" 4 "unknown" 5 "Resvered" 7 "Resvered";
VAL_ 551 Checksum_AEB2 0 "Valid value" 255 "Valid value";
VAL_ 551 AEB_PedResp 0 "OFF" 1 "ON";
VAL_ 551 AEB_VehResp 0 "OFF" 1 "ON";
VAL_ 551 FCW_Snvty 0 "Normal" 1 "High sensitivity" 2 "Low sensitivity" 3 "Reserved";
VAL_ 551 AEB_JA_Resp 0 "OFF" 1 "ON";
VAL_ 551 RollingCounter_AEB2 0 "Valid value" 14 "Valid value" 15 "Invalid value";
VAL_ 551 Checksum_AEB3 0 "Valid value" 255 "Valid value";
VAL_ 551 AEB_VehTrig 0 "not tirggered" 1 "triggered";
VAL_ 551 AEB_PedTrig 0 "not tirggered" 1 "triggered";
VAL_ 551 FCW_AEB_VehFctSts 0 "No display" 1 "error" 2 "FCWAEB_V temporarily unavailable" 3 "FCWAEB_V Performance degradation";
VAL_ 551 FCW_AEB_PedFctSts 0 "No display" 1 "error" 2 "FCWAEB_P temporarily unavailable" 3 "FCWAEB_P Performance degradation";
VAL_ 551 FCW_Warn 0 "No warning" 1 "Latent warning" 2 "warning Level 1" 3 "warning Level 2";
VAL_ 551 AEB_JAFuncSts 0 "No display" 1 "error" 2 "FCWAEB_JA temporarily unavailable" 3 "FCWAEB_JA Performance degradation";
VAL_ 551 AEB_JA_Warn 0 "No warning" 1 "Warning  for vehicle" 2 "Warning for pedestrian" 3 "reverse";
VAL_ 551 AEB_JABrkTrig 0 "Not tirggered" 1 "AEB_JA Function Triggered for vehicle" 2 "AEB_JA Function Triggered for pedestrian" 3 "reverse";
VAL_ 551 RollingCounter_AEB3 0 "Valid value" 14 "Valid value" 15 "Invalid value";
VAL_ 551 ACC_PotentialTgt_02_Dy 0 "Valid_value" 160 "Valid_value" 161 "Reserved" 255 "Reserved";
VAL_ 551 ACC_PotentialTgt_02_Dx 0 "Valid_value" 300 "Valid_value" 301 "Reserved" 511 "Reserved";
VAL_ 551 ACC_PotentialTgt_02_Detn 0 "Not_dectected" 1 "Dectected" 2 "Reserved" 3 "Invalid";
VAL_ 551 ACC_PotentialTgt_02_Typ 0 "Unkown" 1 "Sedan" 2 "Truck" 3 "Motorcycle" 4 "Pedestrian" 5 "Bicycle" 6 "Traffic_cone" 7 "Obstacle";
VAL_ 551 ACC_PotentialTgt_02_fusion 0 "No_fusion" 1 "Fusion";
VAL_ 551 ACC_LeTargrt_03_Detn 0 "Not_dectected" 1 "Dectected" 2 "Reserved" 3 "Invalid";
VAL_ 551 ACC_LeTgt_03_Typ 0 "Unkown" 1 "Sedan" 2 "Truck" 3 "Motorcycle" 4 "Pedestrian" 5 "Bicycle" 6 "Traffic_cone" 7 "Obstacle";
VAL_ 551 ACC_LeTgt_03_fusion 0 "No_fusion" 1 "Fusion";
VAL_ 551 ACC_RiTargrt_03_Detn 0 "Not_dectected" 1 "Dectected" 2 "Reserved" 3 "Invalid";
VAL_ 551 ACC_RiTgt_03_Typ 0 "Unkown" 1 "Sedan" 2 "Truck" 3 "Motorcycle" 4 "Pedestrian" 5 "Bicycle" 6 "Traffic_cone" 7 "Obstacle";
VAL_ 551 ACC_RiTgt_03_fusion 0 "No_fusion" 1 "Fusion";
VAL_ 993 AMP_Chan1DTCInfo 0 "No error in this channel" 1 "Short to groundshort to ACC open load error";
VAL_ 993 AMP_Chan2DTCInfo 0 "No error in this channel" 1 "Short to groundshort to ACC open load error";
VAL_ 993 AMP_Chan3DTCInfo 0 "No error in this channel" 1 "Short to groundshort to ACC open load error";
VAL_ 993 AMP_Chan4DTCInfo 0 "No error in this channel" 1 "Short to groundshort to ACC open load error";
VAL_ 993 AMP_Chan5DTCInfo 0 "No error in this channel" 1 "Short to groundshort to ACC open load error";
VAL_ 993 AMP_Chan6DTCInfo 0 "No error in this channel" 1 "Short to groundshort to ACC open load error";
VAL_ 993 AMP_Chan7DTCInfo 0 "No error in this channel" 1 "Short to groundshort to ACC open load error";
VAL_ 993 AMP_Chan8DTCInfo 0 "No error in this channel" 1 "Short to groundshort to ACC open load error";
VAL_ 993 AMP_TempValue 0 "Amplifier internal temperature value" 254 "Amplifier internal temperature value" 255 "Invalid value";
VAL_ 993 AMP_TempSts 0 "Temperature normal" 1 "Temperature value lower than working temperature" 2 "Temperature value higher than working temperature" 3 "Invalid temperature value";
VAL_ 993 AMP_VolValue 0 "Amplifier internal voltage value" 254 "Amplifier internal voltage value" 255 "Invalid value";
VAL_ 993 BestListegPosnResp 0 "All Seat" 1 "Front Seat" 2 "Rear Seat" 3 "Driver Seat" 4 "Boss Seat" 5 "Children sleep Seat" 6 "reserved" 7 "reserved";
VAL_ 993 Clari_FiResp 0 "OFF" 1 "ON";
VAL_ 995 MediaCallSourceState 0 "Media Source on" 1 "Call Source on" 2 "Reserved-CH I CH IIÃ©Â€ÂšÃ©ÂÂ“" 15 "Reserved-CH I CH IIÃ©Â€ÂšÃ©ÂÂ“";
VAL_ 995 BeepSourceSts 0 "None" 1 "Beep on" 2 "IP on" 3 "IP turn light on" 4 "Radar alarm on" 5 "Reserved CH III" 7 "Reserved CH III";
VAL_ 995 BalanceSetState 0 "Lch+10 - Lch+1" 9 "Lch+10 - Lch+1" 10 "Center" 11 "Rch+1 - Rch+10" 20 "Rch+1 - Rch+10" 21 "Reserved" 31 "Reserved";
VAL_ 995 VSCModeState 0 "OFF" 1 "LOW" 2 "MID" 3 "HI";
VAL_ 995 FadeSetState 0 "Rear+10 - Rear+1" 9 "Rear+10 - Rear+1" 10 "Center" 11 "Front+1 - Front+10" 20 "Front+1 - Front+10" 21 "Reserved" 31 "Reserved";
VAL_ 995 DriveSideSts 0 "LHD" 1 "RHD";
VAL_ 995 BassSetState 0 "-10 - -1" 9 "-10 - -1" 10 "0" 11 "+1 - +10" 20 "+1 - +10" 21 "Reserved" 31 "Reserved";
VAL_ 995 MuteState 0 "Unmute" 1 "Mute";
VAL_ 995 NaviSourceState 0 "None" 1 "Navi on" 2 "VRTTS on" 3 "Reserved-CH IV" 7 "Reserved-CH IV";
VAL_ 995 MidrangeSetState 0 "-10" 1 "-9" 2 "-8" 3 "-7" 4 "-6" 5 "-5" 6 "-4" 7 "-3" 8 "-2" 9 "-1" 10 "0" 11 "1" 12 "2" 13 "3" 14 "4" 15 "5" 16 "6" 17 "7" 18 "8" 19 "9" 20 "10" 21 "Reserved" 31 "Reserved";
VAL_ 995 T_box_ECallSts 0 "OFF" 1 "ON";
VAL_ 995 GetHUTInfoSts 0 "No action" 1 "Action";
VAL_ 995 TrebleSetState 0 "-10" 1 "-9" 2 "-8" 3 "-7" 4 "-6" 5 "-5" 6 "-4" 7 "-3" 8 "-2" 9 "-1" 10 "0" 11 "1" 12 "2" 13 "3" 14 "4" 15 "5" 16 "6" 17 "7" 18 "8" 19 "9" 20 "10" 21 "Reserved" 31 "Reserved";
VAL_ 995 QLISurroundSetSt 0 "Stereo" 1 "Surround";
VAL_ 995 AVMStResp 0 "OFF" 1 "ON";
VAL_ 995 NaviMediaVolLvlResp 0 "Main audio attenuation Level 0" 1 "Main audio attenuation Level 1" 2 "Main audio attenuation Level 2" 3 "Main audio attenuation Level 3" 4 "Main audio attenuation Level 4" 5 "Main audio attenuation Level 5" 6 "Main audio attenuation Level 6" 7 "Main audio attenuation Level 7" 8 "Main audio attenuation Level 8" 9 "Main audio attenuation Level 9" 10 "Main audio attenuation Level 10" 11 "Invalid" 15 "Invalid";
VAL_ 995 AVMMediaVolLvlResp 0 "Main audio attenuation Level 0" 1 "Main audio attenuation Level 1" 2 "Main audio attenuation Level 2" 3 "Main audio attenuation Level 3" 4 "Main audio attenuation Level 4" 5 "Main audio attenuation Level 5" 6 "Main audio attenuation Level 6" 7 "Main audio attenuation Level 7" 8 "Main audio attenuation Level 8" 9 "Main audio attenuation Level 9" 10 "Main audio attenuation Level 10" 11 "Invalid" 15 "Invalid";
VAL_ 995 FPASChStResp 0 "OFF" 1 "ON";
VAL_ 995 RPASChStResp 0 "OFF" 1 "ON";
VAL_ 997 HFMVolSetSts 0 "HFMRTTbox-I&B Call volume step 0-39" 39 "HFMRTTbox-I&B Call volume step 0-39" 40 "Reserved" 62 "Reserved" 63 "Invalid Value";
VAL_ 997 VR_TTSVolSetSts 0 "VRTTS volume step 0-39" 39 "VRTTS volume step 0-39" 40 "Reserved" 62 "Reserved" 63 "Invalid Value";
VAL_ 997 NaviVolumeSetState 0 "Navi volume step 0-39" 39 "Navi volume step 0-39" 40 "Reserved" 62 "Reserved" 63 "Invalid Value";
VAL_ 997 MainVolumeSetState 0 "Main volume step 0-39" 39 "Main volume step 0-39" 40 "Reserved" 62 "Reserved" 63 "Invalid Value";
VAL_ 997 AMPPowerSts 0 "OFF" 1 "ON";
VAL_ 997 IPVolSetSts 0 "Reserved" 9 "Reserved" 10 "IP volume step 10-20" 20 "IP volume step 10-20" 21 "Reserved" 62 "Reserved" 63 "Invalid Value";
VAL_ 722 Microphone_Cha1DTCInfo 0 "No error in this channel" 1 "Short to groundshort to ACC open load error";
VAL_ 722 Microphone_Cha2DTCInfo 0 "No error in this channel" 1 "Short to groundshort to ACC open load error";
VAL_ 722 Microphone_Cha3DTCInfo 0 "No error in this channel" 1 "Short to groundshort to ACC open load error";
VAL_ 722 Microphone_Cha4DTCInfo 0 "No error in this channel" 1 "Short to groundshort to ACC open load error";
VAL_ 722 ANCSwtStatus 0 "OFF" 1 "ON";
VAL_ 793 IPBackgroundLmpCmd 0 "Backlight OFF" 1 "Backlight ON";
VAL_ 793 TrunkSts 0 "Closed" 1 "Open";
VAL_ 793 DrvDoorSts 0 "Closed" 1 "Open";
VAL_ 793 LRDoorSts 0 "Closed" 1 "Open";
VAL_ 793 PassengerDoorSts 0 "Closed" 1 "Open";
VAL_ 793 RRDoorSts 0 "Closed" 1 "Open";
VAL_ 793 BrkPedalSts_BCM 0 "Off" 1 "On";
VAL_ 793 BackgroundLightLvl 0 "Valid Values" 255 "Valid Values";
VAL_ 793 DrowsyDrvDetWarn 0 "No warning" 1 "Warning 1" 2 "Warning 2" 3 "Not available";
VAL_ 793 RLSFailSts 0 "No failure" 1 "Failure";
VAL_ 793 PosnLightReq 0 "Off" 1 "On";
VAL_ 793 WindshldWiprActvSts 0 "Not active" 1 "Active";
VAL_ 773 ExpertModSwtReq 0 "No request" 1 "Request";
VAL_ 773 CCO_SwtShift_Warn 0 "No Warn" 1 "Warn";
VAL_ 773 TAB_SwtShift_Warn 0 "No Warn" 1 "Warn";
VAL_ 773 FourLModeSts 0 "No request" 1 "4L Request";
VAL_ 773 Wade_Sw_Warn 0 "No Warn" 1 "Warn";
VAL_ 773 WadeSwtReq 0 "No Request" 1 "4L Request";
VAL_ 568 SrAntiPinch 0 "Not active" 1 "Active";
VAL_ 568 SsPosn_VR_APP 0 "Fully close" 1 "reserved" 9 "reserved" 10 "10%" 11 "reserved" 19 "reserved" 20 "20%" 21 "reserved" 29 "reserved" 30 "30%" 31 "reserved" 39 "reserved" 40 "40%" 41 "reserved" 49 "reserved" 50 "50%" 51 "reserved" 59 "reserved" 60 "60%" 61 "reserved" 69 "reserved" 70 "70%" 71 "reserved" 79 "reserved" 80 "80%" 81 "reserved" 89 "reserved" 90 "90%" 91 "reserved" 99 "reserved" 100 "Fully open" 101 "Reserved" 127 "Reserved";
VAL_ 568 SsAntiPinch 0 "Not active" 1 "Active";
VAL_ 568 SrPosn_VR_APP 0 "Tilt up" 1 "reserved" 9 "reserved" 10 "10%" 11 "reserved" 19 "reserved" 20 "20%" 21 "reserved" 29 "reserved" 30 "30%" 31 "reserved" 39 "reserved" 40 "40%" 41 "reserved" 49 "reserved" 50 "50%" 51 "reserved" 59 "reserved" 60 "60%" 61 "reserved" 69 "reserved" 70 "70%" 71 "reserved" 79 "reserved" 80 "80%" 81 "reserved" 89 "reserved" 90 "90%" 91 "reserved" 99 "reserved" 100 "Fully open" 101 "Fully close" 102 "Vent area" 103 "reserved" 127 "reserved";
VAL_ 568 RLS_IRBrightness 0 "Vaild value" 254 "Vaild value" 255 "Invaild";
VAL_ 568 RLS_FwBrightness 0 "Vaild value" 4094 "Vaild value" 4095 "Invaild";
VAL_ 568 RLS_AmbBrightness 0 "Vaild value" 4094 "Vaild value" 4095 "Invaild";
VAL_ 675 DrvSeatHeatSts_Nine 0 "OFF" 1 "Level1_Low" 2 "Level2" 3 "Level3" 4 "Level4" 5 "Level5" 6 "Level6" 7 "Level7" 8 "Level8" 9 "Level9_High" 10 "Reserved" 15 "Reserved";
VAL_ 675 PassSeatHeatSts_Nine 0 "OFF" 1 "Level1_Low" 2 "Level2" 3 "Level3" 4 "Level4" 5 "Level5" 6 "Level6" 7 "Level7" 8 "Level8" 9 "Level9_High" 10 "Reserved" 15 "Reserved";
VAL_ 675 SecRowLeSeatHeatSts_Nine 0 "OFF" 1 "Level1_Low" 2 "Level2" 3 "Level3" 4 "Level4" 5 "Level5" 6 "Level6" 7 "Level7" 8 "Level8" 9 "Level9_High" 10 "Reserved" 15 "Reserved";
VAL_ 675 SecRowRiSeatHeatSts_Nine 0 "OFF" 1 "Level1_Low" 2 "Level2" 3 "Level3" 4 "Level4" 5 "Level5" 6 "Level6" 7 "Level7" 8 "Level8" 9 "Level9_High" 10 "Reserved" 15 "Reserved";
VAL_ 837 LasHdLmpSts 0 "Off" 1 "On";
VAL_ 837 AntitheftSts 0 "Disarmed" 1 "Armed" 2 "Prearmed" 3 "Alarmed";
VAL_ 837 DrvDoorLockSts 0 "Lock" 1 "Unlock";
VAL_ 837 DoorLockSts 0 "NA" 1 "All doors locked" 2 "Driver door unlocked" 3 "All doors unlocked";
VAL_ 837 HiLowBeamSts 0 "Off" 1 "ON" 2 "error" 3 "Reserved";
SIG_GROUP_ 849 ABM1 1 : CheckSum_ABM1 SecRowLSBR AirbFailLmpCmd SecRowMidSBR DrvSBR SecRowRSBR PassSBR CrashOutputSts SecRowMidSBR_Visual SecRowLSBR_Visual PassSBR_Visual DrvSBR_Visual SecRowRSBR_Visual RollingCounter_ABM1;
SIG_GROUP_ 683 ACC3_ACC_FD2 1 : Checksum_ACC3 ISL_Resp ICA_HandsOffResp HWA_Resp HWA_SnvtySet_Resp ALC_Resp Longctrl_VehHldReq_DVR Longctrl_DrvOFF_Req_DVR Longctrl_ModSts_DVR Longctrl_Decel_Req_DVR Longctrl_EngTrqReqActive_DVR Longctrl_EngTrqReq_DVR Longctrl_Decel_ReqValue_DVR Longctrl_DecelToStopReq_DVR Longctrl_ParkShiftReq_DVR ALC_InterSysInfoDisp RollingCounter_ACC3;
SIG_GROUP_ 683 ACC4_ACC_FD2 1 : Checksum_ACC4 ACC_ObjDetecte ACC_TakeOverReq ACC_InterSysInfoDisp ACC_ModDisp ACC_FctSts ACC_TgtObjBarDisp Longctrl_HazActv TJA_ACC_SelSts CruCha_ModDisp TJA_ICA_InterSysInfoDisp TJA_ICA_ModDisp ISL_InterSysInfoDisp ACC_TimeGapSet ACC_SpdSetValue CruChar_InterSysInfoDisp RollingCounter_ACC4;
SIG_GROUP_ 683 ACC8_ACC_FD2 1 : Checksum_ACC8 HWA_ModDisp HWA_InterSysInfoDisp HWA_LaneChange HWA_LaneChangeReq HWA_Warning RollingCounter_ACC8;
SIG_GROUP_ 683 ACC6_ACC_FD2 1 : Checksum_ACC6 ACC_PotentialTgtDy ACC_PotentialTgtDx ACC_RlvTgtDetn ACC_EgoStatus ACC_RlvTgtTyp ACC_RlvTgtDy ACC_RlvTgtDx ACC_PotentialTgtDetn ACC_PotentialTgtTyp RollingCounter_ACC6;
SIG_GROUP_ 683 ACC7_ACC_FD2 1 : Checksum_ACC7 ACC_LeTgtDy ACC_LeTgtDx ACC_LeTgtTyp ACC_LeTargrtDection ACC_RiTargrtDetn ACC_RiTgtDy ACC_RiTgtDx ACC_RiTgtTyp Request_driveoff ACCSts RollingCounter_ACC7;
SIG_GROUP_ 551 AEB2_AEB_FD2 1 : Checksum_AEB2 AEB_PedResp AEB_VehResp FCW_Snvty AEB_JA_Resp RollingCounter_AEB2;
SIG_GROUP_ 551 AEB3_AEB_FD2 1 : Checksum_AEB3 AEB_VehTrig AEB_PedTrig FCW_AEB_VehFctSts FCW_AEB_PedFctSts FCW_Warn AEB_JAFuncSts AEB_JA_Warn AEB_JABrkTrig RollingCounter_AEB3;
